VERSION ""

NS_ :

BS_:

BU_: PFAF_HS LVMPC_HS DCDC_HS AMP_HS VICM2_HS FICM_HS ARS_HS MCP_B_HS MCP_A_HS ICCM_OBD_HS SAS_HS ACCM_HS VLBS_HS EBCM_OBD_HS EDI_HS HPCC_HS VITM_OBD_HS PTAM_HS OBCM_HS VICM_HS HCP_HS FDCM_HS APPS_HS ICCM_HS EOCM_F_HS GPCM_HS FSCM_ITBC_HS SCM_HS ITBC_HS VCM_HS HMIM_HS FCP_HS VES_HS Dummy_HS MCP_C_HS RWS_HS ONSTAR_HS EPS_HS TestTool_HS MCP_HS BCP_HS ALC_HS AHL_AFL_HS SADS_HS EPB_HS FSCM_HS AFS_HS FCM_HS TCCM_HS RDCM_HS PTO_HS PCM_HS EBCM_HS ACC_HS BCM_HS TCM_HS ECM_HS

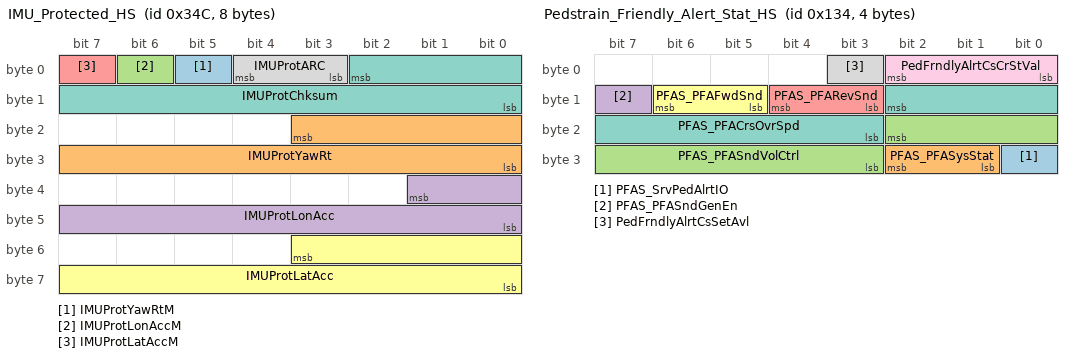
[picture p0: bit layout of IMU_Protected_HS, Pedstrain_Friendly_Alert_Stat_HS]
BO_ 844 IMU_Protected_HS: 8 EBCM_HS
  SG_ IMUProtYawRtM: 5|1@0+ (1,0) [0|1] "" FCM_HS
  SG_ IMUProtYawRt: 19|12@0- (0.0625,0) [-128|127.93751] "deg/sec" FCM_HS
  SG_ IMUProtLonAccM: 6|1@0+ (1,0) [0|1] "" FCM_HS
  SG_ IMUProtLonAcc: 33|10@0- (0.030000001,0) [-15.360001|15.33] "m/s^2" FCM_HS
  SG_ IMUProtLatAccM: 7|1@0+ (1,0) [0|1] "" FCM_HS
  SG_ IMUProtLatAcc: 51|12@0- (0.015625,0) [-32|31.984375] "m/s^2" FCM_HS
  SG_ IMUProtChksum: 2|11@0+ (1,0) [0|2047] "" FCM_HS
  SG_ IMUProtARC: 4|2@0+ (1,0) [0|3] "" FCM_HS

BO_ 308 Pedstrain_Friendly_Alert_Stat_HS: 4 PFAF_HS
  SG_ PFAS_SrvPedAlrtIO: 24|1@0+ (1,0) [0|1] "" BCM_HS
  SG_ PFAS_PFASysStat: 26|2@0+ (1,0) [0|3] "" BCM_HS
  SG_ PFAS_PFASndVolCtrl: 18|8@0+ (0.39215702,0) [0|100.00004] "%" BCM_HS
  SG_ PFAS_PFASndGenEn: 15|1@0+ (1,0) [0|1] "" BCM_HS
  SG_ PFAS_PFARevSnd: 12|2@0+ (1,0) [0|3] "" BCM_HS
  SG_ PFAS_PFAFwdSnd: 14|2@0+ (1,0) [0|3] "" BCM_HS
  SG_ PFAS_PFACrsOvrSpd: 10|8@0+ (1,0) [0|255] "km/h" BCM_HS
  SG_ PedFrndlyAlrtCsSetAvl: 3|1@0+ (1,0) [0|1] "" BCM_HS
  SG_ PedFrndlyAlrtCsCrStVal: 2|3@0+ (1,0) [0|7] "" BCM_HS

BO_ 806 DC_Converter_Stabilization_HS: 1 DCDC_HS
  SG_ DCCnvStblznErrIO: 0|1@0+ (1,0) [0|1] "" BCM_HS

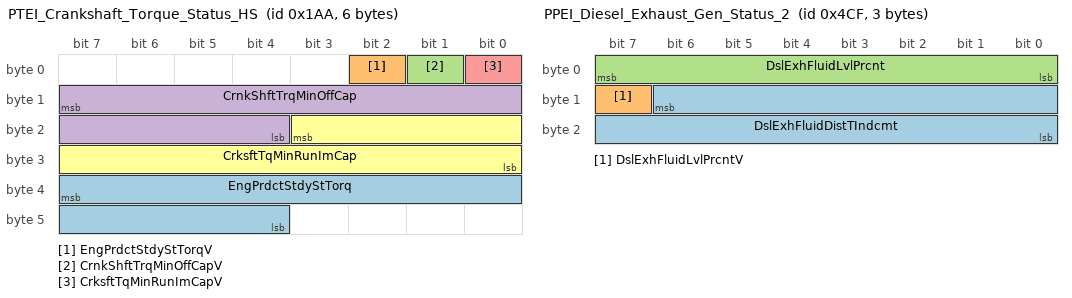
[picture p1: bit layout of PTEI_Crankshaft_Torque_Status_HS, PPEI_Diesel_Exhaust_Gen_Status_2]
BO_ 426 PTEI_Crankshaft_Torque_Status_HS: 6 ECM_HS
  SG_ EngPrdctStdyStTorq: 39|12@0+ (0.5,-848) [-848|1199.5] "Nm" TCM_HS
  SG_ EngPrdctStdyStTorqV: 2|1@0+ (1,0) [0|1] "" TCM_HS
  SG_ CrnkShftTrqMinOffCapV: 1|1@0+ (1,0) [0|1] "" TCM_HS
  SG_ CrnkShftTrqMinOffCap: 15|12@0+ (0.5,-848) [-848|1199.5] "Nm" TCM_HS
  SG_ CrksftTqMinRunImCapV: 0|1@0+ (1,0) [0|1] "" TCM_HS
  SG_ CrksftTqMinRunImCap: 19|12@0+ (0.5,-848) [-848|1199.5] "Nm" TCM_HS

BO_ 1231 PPEI_Diesel_Exhaust_Gen_Status_2: 3 ECM_HS
  SG_ DslExhFluidDistTIndcmt: 14|15@0+ (2,0) [0|65534] "km" BCM_HS
  SG_ DslExhFluidLvlPrcntV: 15|1@0+ (1,0) [0|1] "" BCM_HS
  SG_ DslExhFluidLvlPrcnt: 7|8@0+ (0.39215702,0) [0|100.00004] "%" BCM_HS

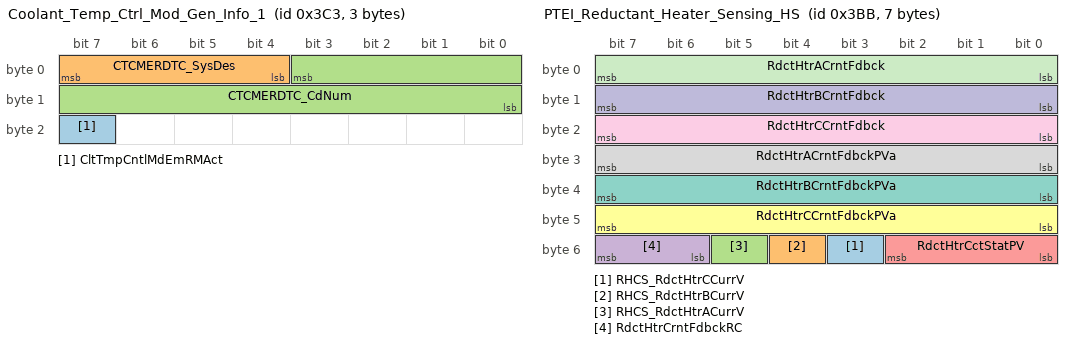
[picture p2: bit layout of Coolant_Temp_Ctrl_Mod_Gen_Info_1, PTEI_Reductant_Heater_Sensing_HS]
BO_ 963 Coolant_Temp_Ctrl_Mod_Gen_Info_1: 3 VICM2_HS
  SG_ CltTmpCntlMdEmRMAct: 23|1@0+ (1,0) [0|1] "" ECM_HS
  SG_ CTCMERDTC_SysDes: 7|4@0+ (1,0) [0|15] "" ECM_HS
  SG_ CTCMERDTC_CdNum: 3|12@0+ (1,0) [0|4095] "" ECM_HS

BO_ 955 PTEI_Reductant_Heater_Sensing_HS: 7 GPCM_HS
  SG_ RHCS_RdctHtrCCurrV: 51|1@0+ (1,0) [0|1] "" PCM_HS ECM_HS
  SG_ RHCS_RdctHtrBCurrV: 52|1@0+ (1,0) [0|1] "" PCM_HS ECM_HS
  SG_ RHCS_RdctHtrACurrV: 53|1@0+ (1,0) [0|1] "" PCM_HS ECM_HS
  SG_ RdctHtrCrntFdbckRC: 55|2@0+ (1,0) [0|3] "" PCM_HS ECM_HS
  SG_ RdctHtrCctStatPV: 50|3@0+ (1,0) [0|7] "" PCM_HS ECM_HS
  SG_ RdctHtrCCrntFdbckPVa: 47|8@0+ (1,0) [0|255] "" PCM_HS ECM_HS
  SG_ RdctHtrBCrntFdbckPVa: 39|8@0+ (1,0) [0|255] "" PCM_HS ECM_HS
  SG_ RdctHtrACrntFdbckPVa: 31|8@0+ (1,0) [0|255] "" PCM_HS ECM_HS
  SG_ RdctHtrCCrntFdbck: 23|8@0+ (0.11764701,0) [0|29.999987] "A" PCM_HS ECM_HS
  SG_ RdctHtrBCrntFdbck: 15|8@0+ (0.11764701,0) [0|29.999987] "A" PCM_HS ECM_HS
  SG_ RdctHtrACrntFdbck: 7|8@0+ (0.11764701,0) [0|29.999987] "A" PCM_HS ECM_HS

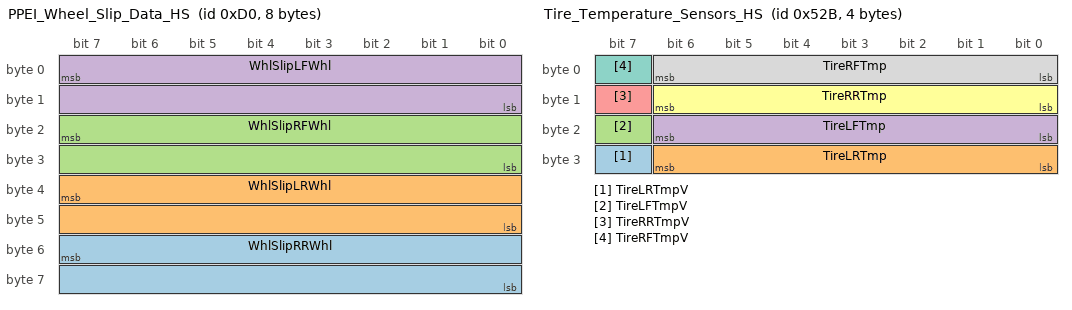
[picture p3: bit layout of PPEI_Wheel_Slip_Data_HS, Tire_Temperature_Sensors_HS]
BO_ 208 PPEI_Wheel_Slip_Data_HS: 8 EBCM_HS
  SG_ WhlSlipRRWhl: 55|16@0+ (0.39062503,-12800) [-12800|12799.608] "%" TCM_HS
  SG_ WhlSlipLRWhl: 39|16@0+ (0.39062503,-12800) [-12800|12799.608] "%" TCM_HS
  SG_ WhlSlipRFWhl: 23|16@0+ (0.39062503,-12800) [-12800|12799.608] "%" TCM_HS
  SG_ WhlSlipLFWhl: 7|16@0+ (0.39062503,-12800) [-12800|12799.608] "%" TCM_HS

BO_ 2034 CCP_Data_Transmission_Object_HS: 8 PTO_HS
  SG_ DgnInf: 7|64@0+ (1,0) [0|1.8446742e+19] "" TestTool_HS

BO_ 2032 CCP_Command_Receive_Object_HS: 8 TestTool_HS
  SG_ DgnInf: 7|64@0+ (1,0) [0|1.8446742e+19] "" PTO_HS

BO_ 563 Performance_Mode_Cust_Setings_HS: 5 EBCM_HS
  SG_ SPMCA_SusPrfMd6Avl: 32|1@0+ (1,0) [0|1] "" BCM_HS
  SG_ SPMCA_SusPrfMd5Avl: 33|1@0+ (1,0) [0|1] "" BCM_HS
  SG_ SPMCA_SusPrfMd4Avl: 34|1@0+ (1,0) [0|1] "" BCM_HS
  SG_ SPMCA_SusPrfMd3Avl: 35|1@0+ (1,0) [0|1] "" BCM_HS
  SG_ SPMCA_SusPrfMd2Avl: 36|1@0+ (1,0) [0|1] "" BCM_HS
  SG_ SPMCA_SusPrfMd1Avl: 37|1@0+ (1,0) [0|1] "" BCM_HS
  SG_ SPMCA_StrPrfMd6Avl: 24|1@0+ (1,0) [0|1] "" BCM_HS
  SG_ SPMCA_StrPrfMd5Avl: 25|1@0+ (1,0) [0|1] "" BCM_HS
  SG_ SPMCA_StrPrfMd4Avl: 26|1@0+ (1,0) [0|1] "" BCM_HS
  SG_ SPMCA_StrPrfMd3Avl: 27|1@0+ (1,0) [0|1] "" BCM_HS
  SG_ SPMCA_StrPrfMd2Avl: 28|1@0+ (1,0) [0|1] "" BCM_HS
  SG_ SPMCA_StrPrfMd1Avl: 29|1@0+ (1,0) [0|1] "" BCM_HS
  SG_ SPMCA_SndPrfMd6Avl: 16|1@0+ (1,0) [0|1] "" BCM_HS
  SG_ SPMCA_SndPrfMd5Avl: 17|1@0+ (1,0) [0|1] "" BCM_HS
  SG_ SPMCA_SndPrfMd4Avl: 18|1@0+ (1,0) [0|1] "" BCM_HS
  SG_ SPMCA_SndPrfMd3Avl: 19|1@0+ (1,0) [0|1] "" BCM_HS
  SG_ SPMCA_SndPrfMd2Avl: 20|1@0+ (1,0) [0|1] "" BCM_HS
  SG_ SPMCA_SndPrfMd1Avl: 21|1@0+ (1,0) [0|1] "" BCM_HS
  SG_ DPMCA_DispPrfMd6Avl: 8|1@0+ (1,0) [0|1] "" BCM_HS
  SG_ DPMCA_DispPrfMd5Avl: 9|1@0+ (1,0) [0|1] "" BCM_HS
  SG_ DPMCA_DispPrfMd4Avl: 10|1@0+ (1,0) [0|1] "" BCM_HS
  SG_ DPMCA_DispPrfMd3Avl: 11|1@0+ (1,0) [0|1] "" BCM_HS
  SG_ DPMCA_DispPrfMd2Avl: 12|1@0+ (1,0) [0|1] "" BCM_HS
  SG_ DPMCA_DispPrfMd1Avl: 13|1@0+ (1,0) [0|1] "" BCM_HS
  SG_ DPMCA_DrvlPrfMd6Avl: 0|1@0+ (1,0) [0|1] "" BCM_HS
  SG_ DPMCA_DrvlPrfMd5Avl: 1|1@0+ (1,0) [0|1] "" BCM_HS
  SG_ DPMCA_DrvlPrfMd4Avl: 2|1@0+ (1,0) [0|1] "" BCM_HS
  SG_ DPMCA_DrvlPrfMd3Avl: 3|1@0+ (1,0) [0|1] "" BCM_HS
  SG_ DPMCA_DrvlPrfMd2Avl: 4|1@0+ (1,0) [0|1] "" BCM_HS
  SG_ DPMCA_DrvlPrfMd1Avl: 5|1@0+ (1,0) [0|1] "" BCM_HS

BO_ 1323 Tire_Temperature_Sensors_HS: 4 BCM_HS
  SG_ TireLRTmpV: 31|1@0+ (1,0) [0|1] "" LVMPC_HS EDI_HS EBCM_OBD_HS EBCM_HS ICCM_OBD_HS ICCM_HS RDCM_HS
  SG_ TireLRTmp: 30|7@0+ (1,-20) [-20|107] "deg C" LVMPC_HS EDI_HS EBCM_OBD_HS EBCM_HS ICCM_OBD_HS ICCM_HS RDCM_HS
  SG_ TireLFTmpV: 23|1@0+ (1,0) [0|1] "" LVMPC_HS EDI_HS EBCM_OBD_HS EBCM_HS ICCM_OBD_HS ICCM_HS RDCM_HS
  SG_ TireLFTmp: 22|7@0+ (1,-20) [-20|107] "deg C" LVMPC_HS EDI_HS EBCM_OBD_HS EBCM_HS ICCM_OBD_HS ICCM_HS RDCM_HS
  SG_ TireRRTmpV: 15|1@0+ (1,0) [0|1] "" LVMPC_HS EDI_HS EBCM_OBD_HS EBCM_HS ICCM_OBD_HS ICCM_HS RDCM_HS
  SG_ TireRRTmp: 14|7@0+ (1,-20) [-20|107] "deg C" LVMPC_HS EDI_HS EBCM_OBD_HS EBCM_HS ICCM_OBD_HS ICCM_HS RDCM_HS
  SG_ TireRFTmpV: 7|1@0+ (1,0) [0|1] "" LVMPC_HS EDI_HS EBCM_OBD_HS EBCM_HS ICCM_OBD_HS ICCM_HS RDCM_HS
  SG_ TireRFTmp: 6|7@0+ (1,-20) [-20|107] "deg C" LVMPC_HS EDI_HS EBCM_OBD_HS EBCM_HS ICCM_OBD_HS ICCM_HS RDCM_HS

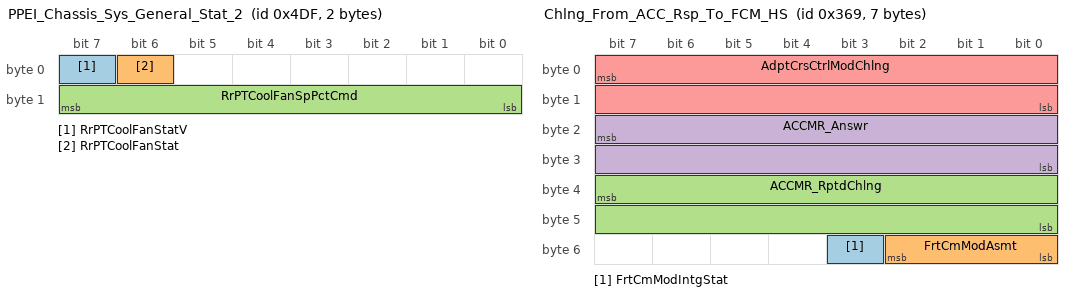
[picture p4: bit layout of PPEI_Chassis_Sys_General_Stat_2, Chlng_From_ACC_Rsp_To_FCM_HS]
BO_ 1247 PPEI_Chassis_Sys_General_Stat_2: 2 ICCM_HS
  SG_ RrPTCoolFanStatV: 7|1@0+ (1,0) [0|2] "" TCM_HS
  SG_ RrPTCoolFanStat: 6|1@0+ (1,0) [0|1] "" TCM_HS
  SG_ RrPTCoolFanSpPctCmd: 15|8@0+ (0.39215702,0) [0|100.00004] "%" TCM_HS

BO_ 873 Chlng_From_ACC_Rsp_To_FCM_HS: 7 ACC_HS
  SG_ FrtCmModIntgStat: 51|1@0+ (1,0) [0|1] "" FCM_HS
  SG_ FrtCmModAsmt: 50|3@0+ (1,0) [0|7] "" FCM_HS
  SG_ ACCMR_RptdChlng: 39|16@0+ (1,0) [0|65535] "" FCM_HS
  SG_ ACCMR_Answr: 23|16@0+ (1,0) [0|65535] "" FCM_HS
  SG_ AdptCrsCtrlModChlng: 7|16@0+ (1,0) [0|65535] "" FCM_HS

BO_ 306 Exhst_Heat_Recvry_Mngmnt_HS: 1 VICM2_HS
  SG_ ClntCrcFlwRtEst: 7|8@0+ (0.39215702,0) [0|100.00004] "%" BCM_HS

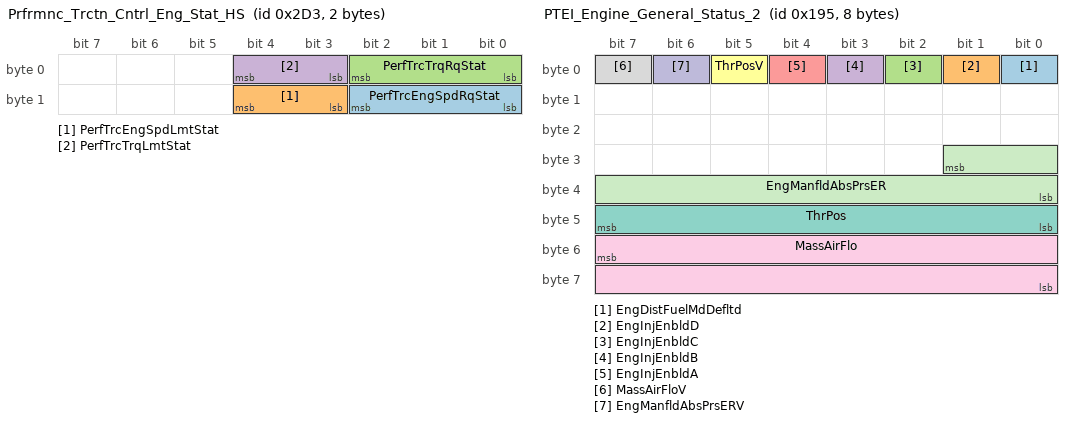
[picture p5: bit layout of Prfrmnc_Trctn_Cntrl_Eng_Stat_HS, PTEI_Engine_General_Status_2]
BO_ 723 Prfrmnc_Trctn_Cntrl_Eng_Stat_HS: 2 ECM_HS
  SG_ PerfTrcEngSpdRqStat: 10|3@0+ (1,0) [0|7] "" EBCM_OBD_HS EBCM_HS PTAM_HS
  SG_ PerfTrcEngSpdLmtStat: 12|2@0+ (1,0) [0|3] "" EBCM_OBD_HS EBCM_HS PTAM_HS
  SG_ PerfTrcTrqRqStat: 2|3@0+ (1,0) [0|7] "" EBCM_OBD_HS EBCM_HS PTAM_HS
  SG_ PerfTrcTrqLmtStat: 4|2@0+ (1,0) [0|3] "" EBCM_OBD_HS EBCM_HS PTAM_HS

BO_ 405 PTEI_Engine_General_Status_2: 8 ECM_HS
  SG_ EngDistFuelMdDefltd: 0|1@0+ (1,0) [0|1] "" FICM_HS
  SG_ EngInjEnbldD: 1|1@0+ (1,0) [0|1] "" FICM_HS
  SG_ EngInjEnbldC: 2|1@0+ (1,0) [0|1] "" FICM_HS
  SG_ EngInjEnbldB: 3|1@0+ (1,0) [0|1] "" FICM_HS
  SG_ EngInjEnbldA: 4|1@0+ (1,0) [0|1] "" FICM_HS
  SG_ ThrPosV: 5|1@0+ (1,0) [0|1] "" FICM_HS
  SG_ ThrPos: 47|8@0+ (0.39215702,0) [0|100.00004] "%" FICM_HS
  SG_ MassAirFloV: 7|1@0+ (1,0) [0|1] "" VCM_HS FICM_HS
  SG_ MassAirFlo: 55|16@0+ (0.010000001,0) [0|655.34998] "grams/s" VCM_HS FICM_HS
  SG_ EngManfldAbsPrsERV: 6|1@0+ (1,0) [0|1] "" FICM_HS
  SG_ EngManfldAbsPrsER: 25|10@0+ (0.5,0) [0|511.5] "kPa" FICM_HS

BO_ 419 PTEI_Engine_Common_Use_1: 1 ECM_HS
  SG_ EngRunng: 7|1@0+ (1,0) [0|1] "" BCM_HS DCDC_HS TCCM_HS EBCM_OBD_HS EBCM_HS OBCM_HS MCP_C_HS MCP_B_HS MCP_A_HS FICM_HS TCM_HS HCP_HS BCP_HS

BO_ 289 ADASIS_RawData_Multiplexed_HS: 8 HMIM_HS
  SG_ ARDM_RawData: 4|61@0+ (1,0) [0|2.305843e+18] "" Dummy_HS
  SG_ ARDM_MsgType: 7|3@0+ (1,0) [0|7] "" Dummy_HS

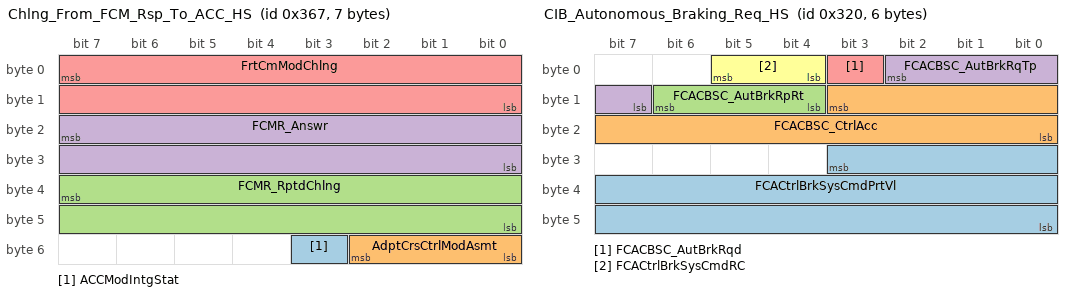
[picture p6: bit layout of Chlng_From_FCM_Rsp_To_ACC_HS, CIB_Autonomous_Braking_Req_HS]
BO_ 871 Chlng_From_FCM_Rsp_To_ACC_HS: 7 FCM_HS
  SG_ ACCModIntgStat: 51|1@0+ (1,0) [0|1] "" ACC_HS
  SG_ AdptCrsCtrlModAsmt: 50|3@0+ (1,0) [0|7] "" ACC_HS
  SG_ FCMR_RptdChlng: 39|16@0+ (1,0) [0|65535] "" ACC_HS
  SG_ FCMR_Answr: 23|16@0+ (1,0) [0|65535] "" ACC_HS
  SG_ FrtCmModChlng: 7|16@0+ (1,0) [0|65535] "" ACC_HS

BO_ 800 CIB_Autonomous_Braking_Req_HS: 6 FCM_HS
  SG_ FCACtrlBrkSysCmdPrtVl: 27|20@0+ (1,0) [0|1048575] "" EBCM_OBD_HS EBCM_HS
  SG_ FCACBSC_CtrlAcc: 11|12@0- (0.010000001,0) [-20.48|20.469999] "m/s^2" EBCM_OBD_HS EBCM_HS
  SG_ FCACBSC_AutBrkRpRt: 14|3@0+ (1,0) [0|7] "" EBCM_OBD_HS EBCM_HS
  SG_ FCACBSC_AutBrkRqTp: 2|4@0+ (1,0) [0|15] "" EBCM_OBD_HS EBCM_HS
  SG_ FCACBSC_AutBrkRqd: 3|1@0+ (1,0) [0|1] "" EBCM_OBD_HS EBCM_HS
  SG_ FCACtrlBrkSysCmdRC: 5|2@0+ (1,0) [0|3] "" EBCM_OBD_HS EBCM_HS

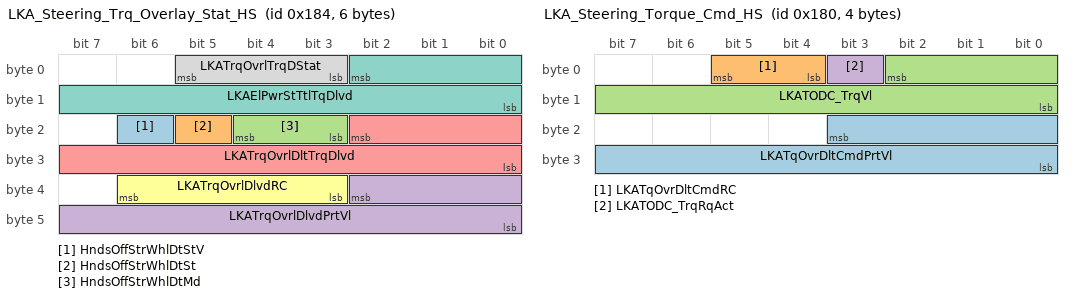
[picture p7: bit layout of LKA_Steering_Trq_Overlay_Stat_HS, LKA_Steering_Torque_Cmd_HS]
BO_ 388 LKA_Steering_Trq_Overlay_Stat_HS: 6 EPS_HS
  SG_ HndsOffStrWhlDtStV: 22|1@0+ (1,0) [0|1] "" FCM_HS
  SG_ HndsOffStrWhlDtSt: 21|1@0+ (1,0) [0|1] "" FCM_HS
  SG_ HndsOffStrWhlDtMd: 20|2@0+ (1,0) [0|3] "" FCM_HS
  SG_ LKATrqOvrlDlvdPrtVl: 34|11@0+ (1,0) [0|2047] "" FCM_HS
  SG_ LKATrqOvrlDltTrqDlvd: 18|11@0- (0.010000001,0) [-10.24|10.23] "Nm" FCM_HS
  SG_ LKATrqOvrlDlvdRC: 38|4@0+ (1,0) [0|15] "" FCM_HS
  SG_ LKAElPwrStTtlTqDlvd: 2|11@0- (0.010000001,0) [-10.24|10.23] "Nm" FCM_HS
  SG_ LKATrqOvrlTrqDStat: 5|3@0+ (1,0) [0|7] "" FCM_HS

BO_ 384 LKA_Steering_Torque_Cmd_HS: 4 FCM_HS
  SG_ LKATqOvrDltCmdPrtVl: 19|12@0+ (1,0) [0|4095] "" EPS_HS
  SG_ LKATqOvrDltCmdRC: 5|2@0+ (1,0) [0|3] "" EPS_HS
  SG_ LKATODC_TrqVl: 2|11@0- (0.010000001,0) [-10.24|10.23] "Nm" EPS_HS
  SG_ LKATODC_TrqRqAct: 3|1@0+ (1,0) [0|1] "" EPS_HS

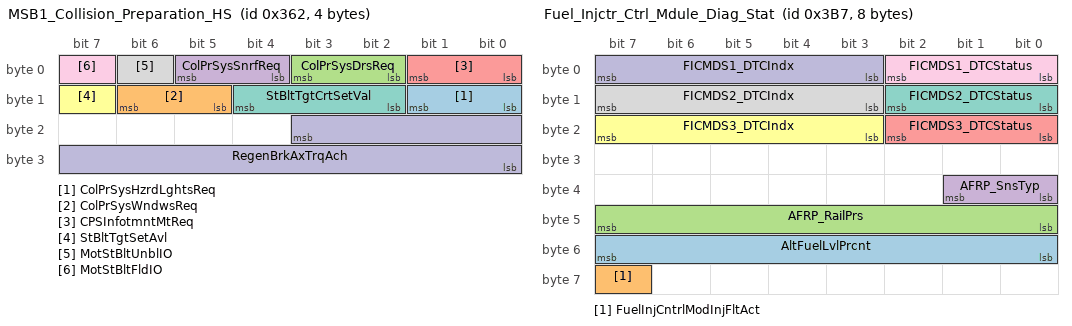
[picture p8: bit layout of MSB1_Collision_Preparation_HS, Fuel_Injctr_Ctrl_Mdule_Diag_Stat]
BO_ 866 MSB1_Collision_Preparation_HS: 4 EBCM_HS
  SG_ ColPrSysHzrdLghtsReq: 9|2@0+ (1,0) [0|3] "" BCM_HS
  SG_ ColPrSysWndwsReq: 14|2@0+ (1,0) [0|3] "" BCM_HS
  SG_ ColPrSysDrsReq: 3|2@0+ (1,0) [0|3] "" BCM_HS
  SG_ ColPrSysSnrfReq: 5|2@0+ (1,0) [0|3] "" BCM_HS
  SG_ CPSInfotmntMtReq: 1|2@0+ (1,0) [0|3] "" BCM_HS
  SG_ StBltTgtSetAvl: 15|1@0+ (1,0) [0|1] "" BCM_HS
  SG_ StBltTgtCrtSetVal: 12|3@0+ (1,0) [0|7] "" BCM_HS
  SG_ MotStBltUnblIO: 6|1@0+ (1,0) [0|1] "" BCM_HS
  SG_ MotStBltFldIO: 7|1@0+ (1,0) [0|1] "" BCM_HS
  SG_ RegenBrkAxTrqAch: 19|12@0+ (2,0) [0|8190] "Nm" VICM_HS

BO_ 951 Fuel_Injctr_Ctrl_Mdule_Diag_Stat: 8 FICM_HS
  SG_ AltFuelLvlPrcnt: 55|8@0+ (0.39215702,0) [0|100.00004] "%" ECM_HS
  SG_ FuelInjCntrlModInjFltAct: 63|1@0+ (1,0) [0|1] "" ECM_HS
  SG_ AFRP_RailPrs: 47|8@0+ (3,0) [0|765] "kPa" ECM_HS
  SG_ AFRP_SnsTyp: 33|2@0+ (1,0) [0|3] "" ECM_HS
  SG_ FICMDS3_DTCStatus: 18|3@0+ (1,0) [0|7] "" ECM_HS
  SG_ FICMDS3_DTCIndx: 23|5@0+ (1,0) [0|31] "" ECM_HS
  SG_ FICMDS2_DTCStatus: 10|3@0+ (1,0) [0|7] "" ECM_HS
  SG_ FICMDS2_DTCIndx: 15|5@0+ (1,0) [0|31] "" ECM_HS
  SG_ FICMDS1_DTCStatus: 2|3@0+ (1,0) [0|7] "" ECM_HS
  SG_ FICMDS1_DTCIndx: 7|5@0+ (1,0) [0|31] "" ECM_HS

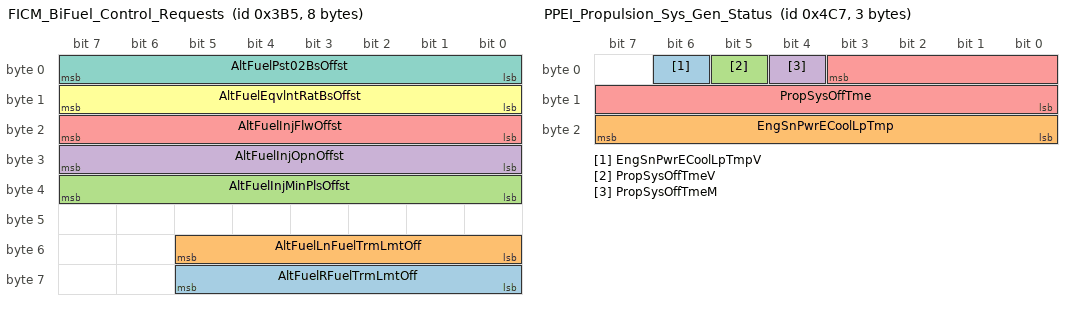
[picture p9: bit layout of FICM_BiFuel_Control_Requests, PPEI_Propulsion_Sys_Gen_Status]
BO_ 949 FICM_BiFuel_Control_Requests: 8 FICM_HS
  SG_ AltFuelRFuelTrmLmtOff: 61|6@0- (0.010000001,0) [-0.32000002|0.31] "" ECM_HS
  SG_ AltFuelLnFuelTrmLmtOff: 53|6@0- (0.010000001,0) [-0.32000002|0.31] "" ECM_HS
  SG_ AltFuelInjMinPlsOffst: 39|8@0- (0.031372499,0) [-4.0156803|3.9843073] "grams/s" ECM_HS
  SG_ AltFuelInjOpnOffst: 31|8@0- (0.031372499,0) [-4.0156803|3.9843073] "grams/s" ECM_HS
  SG_ AltFuelInjFlwOffst: 23|8@0- (0.031372499,0) [-4.0156803|3.9843073] "grams/s" ECM_HS
  SG_ AltFuelEqvlntRatBsOffst: 15|8@0- (0.00039215703,0) [-0.050196104|0.049803939] "" ECM_HS
  SG_ AltFuelPst02BsOffst: 7|8@0- (4,0) [-512|508] "mVolts" ECM_HS

BO_ 1223 PPEI_Propulsion_Sys_Gen_Status: 3 ECM_HS
  SG_ EngSnPwrECoolLpTmpV: 6|1@0+ (1,0) [0|1] "" VICM_HS
  SG_ EngSnPwrECoolLpTmp: 23|8@0+ (1,-40) [-40|215] "deg C" VICM_HS
  SG_ PropSysOffTmeV: 5|1@0+ (1,0) [0|1] "" VICM2_HS EBCM_OBD_HS EBCM_HS MCP_C_HS TCM_HS HCP_HS BCP_HS MCP_B_HS MCP_A_HS VICM_HS
  SG_ PropSysOffTmeM: 4|1@0+ (1,0) [0|1] "" VICM2_HS EBCM_OBD_HS EBCM_HS MCP_C_HS TCM_HS HCP_HS BCP_HS MCP_B_HS MCP_A_HS VICM_HS
  SG_ PropSysOffTme: 3|12@0+ (0.5,0) [0|2047.5] "min" VICM2_HS EBCM_OBD_HS EBCM_HS MCP_C_HS TCM_HS HCP_HS BCP_HS MCP_B_HS MCP_A_HS VICM_HS

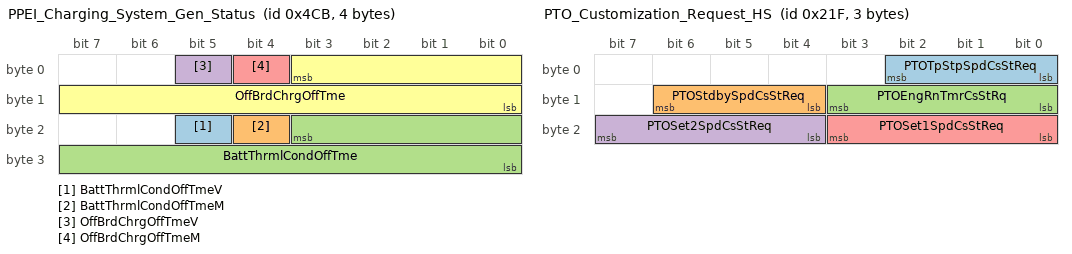
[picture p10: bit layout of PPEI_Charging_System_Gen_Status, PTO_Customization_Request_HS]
BO_ 1227 PPEI_Charging_System_Gen_Status: 4 VICM_HS
  SG_ BattThrmlCondOffTmeV: 21|1@0+ (1,0) [0|1] "" MCP_C_HS TCM_HS HCP_HS MCP_B_HS MCP_A_HS PCM_HS ECM_HS
  SG_ BattThrmlCondOffTmeM: 20|1@0+ (1,0) [0|1] "" MCP_C_HS TCM_HS HCP_HS MCP_B_HS MCP_A_HS PCM_HS ECM_HS
  SG_ BattThrmlCondOffTme: 19|12@0+ (0.5,0) [0|2047.5] "min" MCP_C_HS TCM_HS HCP_HS MCP_B_HS MCP_A_HS PCM_HS ECM_HS
  SG_ OffBrdChrgOffTmeV: 5|1@0+ (1,0) [0|1] "" MCP_C_HS TCM_HS HCP_HS MCP_B_HS MCP_A_HS PCM_HS ECM_HS
  SG_ OffBrdChrgOffTmeM: 4|1@0+ (1,0) [0|1] "" MCP_C_HS TCM_HS HCP_HS MCP_B_HS MCP_A_HS PCM_HS ECM_HS
  SG_ OffBrdChrgOffTme: 3|12@0+ (0.5,0) [0|2047.5] "min" MCP_C_HS TCM_HS HCP_HS MCP_B_HS MCP_A_HS PCM_HS ECM_HS

BO_ 543 PTO_Customization_Request_HS: 3 BCM_HS
  SG_ PTOTpStpSpdCsStReq: 2|3@0+ (1,0) [0|7] "" PTO_HS
  SG_ PTOStdbySpdCsStReq: 14|3@0+ (1,0) [0|7] "" PTO_HS
  SG_ PTOEngRnTmrCsStRq: 11|4@0+ (1,0) [0|15] "" PTO_HS
  SG_ PTOSet2SpdCsStReq: 23|4@0+ (1,0) [0|15] "" PTO_HS
  SG_ PTOSet1SpdCsStReq: 19|4@0+ (1,0) [0|15] "" PTO_HS

BO_ 544 PTO_Status_HS: 5 PTO_HS
  SG_ PTOAudExtAlertReq: 19|1@0+ (1,0) [0|1] "" BCM_HS
  SG_ PTOTransInGearIO: 13|1@0+ (1,0) [0|1] "" BCM_HS
  SG_ PTOTpStpSpdCsStAvl: 10|1@0+ (1,0) [0|1] "" BCM_HS
  SG_ PTOTpStSpdCsCrStVal: 26|3@0+ (1,0) [0|7] "" BCM_HS
  SG_ PTOStdbySpdCsStAvl: 12|1@0+ (1,0) [0|1] "" BCM_HS
  SG_ PTOStdbSpdCsCrStVal: 18|3@0+ (1,0) [0|7] "" BCM_HS
  SG_ PTOSetPrkBrkIO: 14|1@0+ (1,0) [0|1] "" BCM_HS
  SG_ PTOSet2SpdCsStAvl: 9|1@0+ (1,0) [0|1] "" BCM_HS
  SG_ PTOSet2SpdCsCrStVal: 39|4@0+ (1,0) [0|15] "" BCM_HS
  SG_ PTOSet1SpdCsStAvl: 8|1@0+ (1,0) [0|1] "" BCM_HS
  SG_ PTOSet1SpdCsCrStVal: 35|4@0+ (1,0) [0|15] "" BCM_HS
  SG_ PTORelCltPedIO: 15|1@0+ (1,0) [0|1] "" BCM_HS
  SG_ PTORelBrkPedIO: 0|1@0+ (1,0) [0|1] "" BCM_HS
  SG_ PTORelAccPedIO: 1|1@0+ (1,0) [0|1] "" BCM_HS
  SG_ PTORedEngSpdIO: 2|1@0+ (1,0) [0|1] "" BCM_HS
  SG_ PTOPrsRelCltPedIO: 3|1@0+ (1,0) [0|1] "" BCM_HS
  SG_ PTOPrsRelBrkPedIO: 4|1@0+ (1,0) [0|1] "" BCM_HS
  SG_ PTOEngRnTmrCsStAvl: 11|1@0+ (1,0) [0|1] "" BCM_HS
  SG_ PTOEnRnTmCsCrStVal: 30|4@0+ (1,0) [0|15] "" BCM_HS
  SG_ PTOEngmntStatInd: 6|2@0+ (1,0) [0|3] "" BCM_HS
  SG_ PTODisengCrsCntlIO: 7|1@0+ (1,0) [0|1] "" BCM_HS

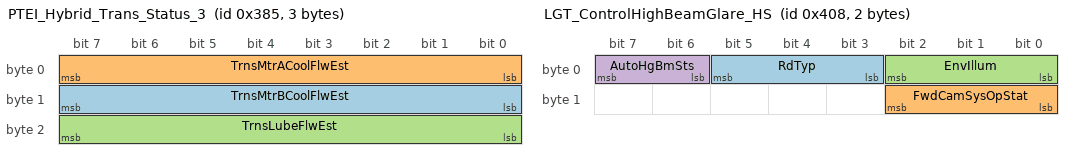
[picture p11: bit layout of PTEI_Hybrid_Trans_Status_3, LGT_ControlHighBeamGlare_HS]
BO_ 901 PTEI_Hybrid_Trans_Status_3: 3 TCM_HS
  SG_ TrnsMtrBCoolFlwEst: 15|8@0+ (0.050000004,0) [0|12.75] "l/min" HCP_HS
  SG_ TrnsMtrACoolFlwEst: 7|8@0+ (0.050000004,0) [0|12.75] "l/min" HCP_HS
  SG_ TrnsLubeFlwEst: 23|8@0+ (0.0625,0) [0|15.937499] "l/min" HCP_HS

BO_ 1032 LGT_ControlHighBeamGlare_HS: 2 FCM_HS
  SG_ RdTyp: 5|3@0+ (1,0) [0|7] "" AHL_AFL_HS
  SG_ FwdCamSysOpStat: 10|3@0+ (1,0) [0|7] "" AHL_AFL_HS
  SG_ EnvIllum: 2|3@0+ (1,0) [0|7] "" AHL_AFL_HS
  SG_ AutoHgBmSts: 7|2@0+ (1,0) [0|3] "" AHL_AFL_HS

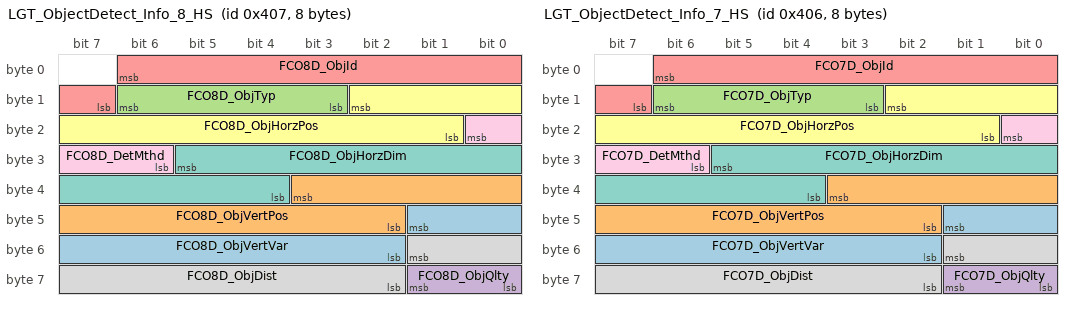
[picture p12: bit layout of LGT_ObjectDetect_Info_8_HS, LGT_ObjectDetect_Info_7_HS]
BO_ 1031 LGT_ObjectDetect_Info_8_HS: 8 FCM_HS
  SG_ FCO8D_ObjVertVar: 41|8@0- (0.050000004,0) [-6.4000001|6.3500004] "deg" AHL_AFL_HS
  SG_ FCO8D_ObjVertPos: 35|10@0- (0.050000004,0) [-25.6|25.549999] "deg" AHL_AFL_HS
  SG_ FCO8D_ObjTyp: 14|4@0+ (1,0) [0|15] "" AHL_AFL_HS
  SG_ FCO8D_ObjQlty: 57|2@0+ (1,0) [0|3] "" AHL_AFL_HS
  SG_ FCO8D_ObjId: 6|8@0+ (1,0) [0|255] "" AHL_AFL_HS
  SG_ FCO8D_ObjHorzPos: 10|10@0- (0.050000004,0) [-25.6|25.549999] "deg" AHL_AFL_HS
  SG_ FCO8D_ObjHorzDim: 29|10@0+ (0.010000001,0) [0|10.23] "deg" AHL_AFL_HS
  SG_ FCO8D_ObjDist: 49|8@0+ (2,0) [0|510] "m" AHL_AFL_HS
  SG_ FCO8D_DetMthd: 16|3@0+ (1,0) [0|7] "" AHL_AFL_HS

BO_ 1030 LGT_ObjectDetect_Info_7_HS: 8 FCM_HS
  SG_ FCO7D_ObjVertVar: 41|8@0- (0.050000004,0) [-6.4000001|6.3500004] "deg" AHL_AFL_HS
  SG_ FCO7D_ObjVertPos: 35|10@0- (0.050000004,0) [-25.6|25.549999] "deg" AHL_AFL_HS
  SG_ FCO7D_ObjTyp: 14|4@0+ (1,0) [0|15] "" AHL_AFL_HS
  SG_ FCO7D_ObjQlty: 57|2@0+ (1,0) [0|3] "" AHL_AFL_HS
  SG_ FCO7D_ObjId: 6|8@0+ (1,0) [0|255] "" AHL_AFL_HS
  SG_ FCO7D_ObjHorzPos: 10|10@0- (0.050000004,0) [-25.6|25.549999] "deg" AHL_AFL_HS
  SG_ FCO7D_ObjHorzDim: 29|10@0+ (0.010000001,0) [0|10.23] "deg" AHL_AFL_HS
  SG_ FCO7D_ObjDist: 49|8@0+ (2,0) [0|510] "m" AHL_AFL_HS
  SG_ FCO7D_DetMthd: 16|3@0+ (1,0) [0|7] "" AHL_AFL_HS

BO_ 479 PPEI_Propulsion_Gen_Stat_1_HS: 4 HCP_HS
  SG_ ASIRI_Indication16: 24|1@0+ (1,0) [0|1] "" BCM_HS
  SG_ ASIRI_Indication15: 25|1@0+ (1,0) [0|1] "" BCM_HS
  SG_ ASIRI_Indication14: 26|1@0+ (1,0) [0|1] "" BCM_HS
  SG_ ASIRI_Indication13: 27|1@0+ (1,0) [0|1] "" BCM_HS
  SG_ ASIRI_Indication12: 28|1@0+ (1,0) [0|1] "" BCM_HS
  SG_ ASIRI_Indication11: 29|1@0+ (1,0) [0|1] "" BCM_HS
  SG_ ASIRI_Indication10: 30|1@0+ (1,0) [0|1] "" BCM_HS
  SG_ ASIRI_Indication09: 31|1@0+ (1,0) [0|1] "" BCM_HS
  SG_ ASIRI_Indication08: 16|1@0+ (1,0) [0|1] "" BCM_HS
  SG_ ASIRI_Indication07: 17|1@0+ (1,0) [0|1] "" BCM_HS
  SG_ ASIRI_Indication06: 18|1@0+ (1,0) [0|1] "" BCM_HS
  SG_ ASIRI_Indication05: 19|1@0+ (1,0) [0|1] "" BCM_HS
  SG_ ASIRI_Indication04: 20|1@0+ (1,0) [0|1] "" BCM_HS
  SG_ ASIRI_Indication03: 21|1@0+ (1,0) [0|1] "" BCM_HS
  SG_ ASIRI_Indication02: 22|1@0+ (1,0) [0|1] "" BCM_HS
  SG_ ASIRI_Indication01: 23|1@0+ (1,0) [0|1] "" BCM_HS
  SG_ PTWrmgWtToShftIO: 5|1@0+ (1,0) [0|1] "" BCM_HS
  SG_ PrplsnSysAtv: 7|1@0+ (1,0) [0|1] "" EPB_HS TCM_HS ECM_HS TCCM_HS VICM_HS ICCM_OBD_HS ICCM_HS FSCM_HS ACCM_HS EBCM_OBD_HS EBCM_HS OBCM_HS VICM2_HS VITM_OBD_HS
  SG_ PTShftLvrLckRqd: 6|1@0+ (1,0) [0|1] "" BCM_HS

BO_ 211 PPEI_Hybrid_General_Status_3_HS: 2 HCP_HS
  SG_ ActAxleTrqV: 7|1@0+ (1,0) [0|1] "" SADS_HS ICCM_OBD_HS ICCM_HS TCM_HS PCM_HS ECM_HS EBCM_OBD_HS EBCM_HS BCP_HS EOCM_F_HS VICM_HS TCCM_HS ACC_HS
  SG_ ActAxleTrq: 6|15@0+ (2,-22534) [-22534|43000] "Nm" SADS_HS ICCM_OBD_HS ICCM_HS EBCM_OBD_HS EBCM_HS TCM_HS PCM_HS ECM_HS BCP_HS EOCM_F_HS TCCM_HS VICM_HS ACC_HS

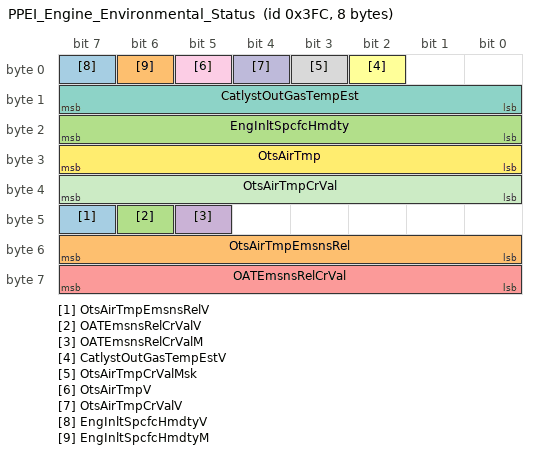
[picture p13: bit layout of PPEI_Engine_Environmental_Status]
BO_ 1020 PPEI_Engine_Environmental_Status: 8 ECM_HS
  SG_ OtsAirTmpEmsnsRelV: 47|1@0+ (1,0) [0|1] "" VICM_HS
  SG_ OtsAirTmpEmsnsRel: 55|8@0+ (0.5,-40) [-40|87.5] "deg C" VICM_HS
  SG_ OATEmsnsRelCrValV: 46|1@0+ (1,0) [0|1] "" VICM_HS
  SG_ OATEmsnsRelCrValM: 45|1@0+ (1,0) [0|1] "" VICM_HS
  SG_ OATEmsnsRelCrVal: 63|8@0+ (0.5,-40) [-40|87.5] "deg C" VICM_HS
  SG_ CatlystOutGasTempEstV: 2|1@0+ (1,0) [0|1] "" VICM_HS
  SG_ CatlystOutGasTempEst: 15|8@0+ (5,-40) [-40|1235] "deg C" VICM_HS
  SG_ OtsAirTmpCrValMsk: 3|1@0+ (1,0) [0|1] "" VICM_HS BCM_HS
  SG_ OtsAirTmpV: 5|1@0+ (1,0) [0|1] "" VICM_HS BCM_HS
  SG_ OtsAirTmpCrValV: 4|1@0+ (1,0) [0|1] "" VICM_HS BCM_HS
  SG_ OtsAirTmpCrVal: 39|8@0+ (0.5,-40) [-40|87.5] "deg C" VICM_HS BCM_HS
  SG_ OtsAirTmp: 31|8@0+ (0.5,-40) [-40|87.5] "deg C" VICM_HS BCM_HS
  SG_ EngInltSpcfcHmdtyV: 7|1@0+ (1,0) [0|1] "" VICM_HS BCM_HS EBCM_OBD_HS EBCM_HS
  SG_ EngInltSpcfcHmdtyM: 6|1@0+ (1,0) [0|1] "" VICM_HS BCM_HS EBCM_OBD_HS EBCM_HS
  SG_ EngInltSpcfcHmdty: 23|8@0+ (0.019607801,0) [0|4.999989] "% water" VICM_HS BCM_HS EBCM_OBD_HS EBCM_HS

VAL_TABLE_ vt_BooleanValues 0 "false" 1 "true";
VAL_TABLE_ TCTPIR_DrvNotfn 0 "No Indication" 1 "Indication 1" 2 "Indication 2" 3 "Indication 3" 4 "Indication 4" 5 "Indication 5" 6 "Indication 6" 7 "Indication 7" 8 "Indication 8" 9 "Indication 9" 10 "Indication 10" 11 "Indication 11" 12 "Indication 12" 13 "Indication 13" 14 "Indication 14" 15 "Indication 15";
VAL_TABLE_ PltfrmEngSpdCmmndSt 0 "No Request" 1 "Request Honored" 2 "Lost Arbitration" 3 "Request Denied";
VAL_TABLE_ TrStPTGrdBrkDsMdOvr 0 "No Override" 1 "To Not Grade Braking Disable" 2 "To Grade Braking Disable" 3 "Unused and Reserved";
VAL_TABLE_ SpdLmtrSttngTyp 0 "Manual" 1 "Auto";
VAL_TABLE_ HiPresFuelPmpCntMd 0 "Disable Mode" 1 "DFCO Mode" 2 "Normal Mode" 3 "Start Mode" 4 "Noise Control Disable Mode" 5 "Noise Control Max Mode" 6 "Zero Flow Mode";
VAL_TABLE_ ClmtCtrlHtrEngRunRq 0 "No Action" 1 "Engine Run Requested";
VAL_TABLE_ TrnsStWntrMdOvrd 0 "No Override" 1 "Override To Not Winter" 2 "Override To Winter";
VAL_TABLE_ TrnsStTwHaulMdOvrd 0 "No Override" 1 "Override To Not Tow Haul" 2 "Override To Tow Haul";
VAL_TABLE_ TrnsStSprtMdOvrd 0 "No Override" 1 "Override To Not Sport" 2 "Override To Sport";
VAL_TABLE_ TrnsStEconMdOvrd 0 "No Override" 1 "Override To Not Economy" 2 "Override To Economy";
VAL_TABLE_ StgSysPerfMdRq 0 "No Action" 1 "Performance Mode 1" 2 "Performance Mode 2" 3 "Performance Mode 3" 4 "Performance Mode 4" 5 "Performance Mode 5" 6 "Performance Mode 6" 7 "Performance Mode 7";
VAL_TABLE_ SndEnhcmtPerfMdRq 0 "No Action" 1 "Performance Mode 1" 2 "Performance Mode 2" 3 "Performance Mode 3" 4 "Performance Mode 4" 5 "Performance Mode 5" 6 "Performance Mode 6" 7 "Performance Mode 7";
VAL_TABLE_ RideCntrlPerfMdRq 0 "No Action" 1 "Performance Mode 1" 2 "Performance Mode 2" 3 "Performance Mode 3" 4 "Performance Mode 4" 5 "Performance Mode 5" 6 "Performance Mode 6" 7 "Performance Mode 7";
VAL_TABLE_ ExhstPerfMdRq 0 "No Action" 1 "Performance Mode 1" 2 "Performance Mode 2" 3 "Performance Mode 3" 4 "Performance Mode 4" 5 "Performance Mode 5" 6 "Performance Mode 6" 7 "Performance Mode 7";
VAL_TABLE_ DsplyPerfMdRq 0 "No Action" 1 "Performance Mode 1" 2 "Performance Mode 2" 3 "Performance Mode 3" 4 "Performance Mode 4" 5 "Performance Mode 5" 6 "Performance Mode 6" 7 "Performance Mode 7";
VAL_TABLE_ DiffPerfMdRq 0 "No Action" 1 "Performance Mode 1" 2 "Performance Mode 2" 3 "Performance Mode 3" 4 "Performance Mode 4" 5 "Performance Mode 5" 6 "Performance Mode 6" 7 "Performance Mode 7";
VAL_TABLE_ AWDPerfMdRq 0 "No Action" 1 "Performance Mode 1" 2 "Performance Mode 2" 3 "Performance Mode 3" 4 "Performance Mode 4" 5 "Performance Mode 5" 6 "Performance Mode 6" 7 "Performance Mode 7";
VAL_TABLE_ RdHVltBatPckVltM 0 "Don't Use Data" 1 "Use Data";
VAL_TABLE_ RdHVltBatPckCrntM 0 "Don't Use Data" 1 "Use Data";
VAL_TABLE_ RdHVltBatMinClVltM 0 "Don't Use Data" 1 "Use Data";
VAL_TABLE_ RdHVltBatMaxClVltM 0 "Don't Use Data" 1 "Use Data";
VAL_TABLE_ AFRP_SnsTyp 0 "Not Supported" 1 "Pressure Relative Manifold Vacuum" 2 "Absolute Pressure" 3 "Gauge Pressure";
VAL_TABLE_ FICMDS3_DTCStatus 0 "Not Supported" 1 "Critically Disabled" 2 "No Status to Report" 3 "Diagnostic Passed" 4 "Diagnostic Failed";
VAL_TABLE_ FICMDS2_DTCStatus 0 "Not Supported" 1 "Critically Disabled" 2 "No Status to Report" 3 "Diagnostic Passed" 4 "Diagnostic Failed";
VAL_TABLE_ FICMDS1_DTCStatus 0 "Not Supported" 1 "Critically Disabled" 2 "No Status to Report" 3 "Diagnostic Passed" 4 "Diagnostic Failed";
VAL_TABLE_ PropSysOffTmeM 0 "Don't Use Data" 1 "Use Data";
VAL_TABLE_ OffBrdChrgOffTmeM 0 "Don't Use Data" 1 "Use Data";
VAL_TABLE_ BattThrmlCondOffTmeM 0 "Don't Use Data" 1 "Use Data";
VAL_TABLE_ CrsSecSwStat 0 "Indeterminate" 1 "No Activation" 2 "Unused and Reserved 1" 3 "Gap Down" 4 "Gap Up" 5 "Speed Increase High" 6 "Speed Decrease High" 7 "Open/Short to Ground" 8 "Short to Power" 9 "Between Ranges" 10 "Unused and Reserved 2" 11 "Unused and Reserved 3" 12 "Unused and Reserved 4" 13 "Unused and Reserved 5" 14 "Unused and Reserved 6" 15 "Unused and Reserved 7";
VAL_TABLE_ EDADS_RcmndtFwdGr 0 "None" 1 "First Gear" 2 "Second Gear" 3 "Third Gear" 4 "Fourth Gear" 5 "Fifth Gear" 6 "Sixth Gear" 7 "Seventh Gear" 8 "Eighth Gear" 9 "Unused and Reserved 1" 10 "Unused and Reserved 2" 11 "Unused and Reserved 3" 12 "Unused and Reserved 4" 13 "Unused and Reserved 5" 14 "Unused and Reserved 6" 15 "Unused and Reserved 7";
VAL_TABLE_ EDADS_CrntFwdMsdG 0 "None" 1 "First Gear" 2 "Second Gear" 3 "Third Gear" 4 "Fourth Gear" 5 "Fifth Gear" 6 "Sixth Gear" 7 "Seventh Gear" 8 "Eighth Gear" 9 "Unused and Reserved 1" 10 "Unused and Reserved 2" 11 "Unused and Reserved 3" 12 "Unused and Reserved 4" 13 "Unused and Reserved 5" 14 "Unused and Reserved 6" 15 "Unused and Reserved 7";
VAL_TABLE_ EDADS_ShftIndStat 0 "Shift Down" 1 "Shift Up" 2 "No Shift";
VAL_TABLE_ PrsElvtdIdlCntlStat 0 "Disabled" 1 "Enabled";
VAL_TABLE_ GPCMDS2_DTCStatus 0 "Not Supported" 1 "Critically Disabled" 2 "No Status to Report" 3 "Diagnostic Passed" 4 "Diagnostic Failed";
VAL_TABLE_ EngPwrCnfg 0 "Default" 1 "Configuration 1" 2 "Configuration 2" 3 "Configuration 3" 4 "Configuration 4" 5 "Configuration 5" 6 "Configuration 6" 7 "Configuration 7" 8 "Configuration 8" 9 "Configuration 9" 10 "Configuration 10" 11 "Configuration 11" 12 "Configuration 12" 13 "Configuration 13" 14 "Configuration 14" 15 "Configuration 15";
VAL_TABLE_ CTSS_StbltyLvl 0 "Level 0" 1 "Level 1" 2 "Level 2" 3 "Level 3" 4 "Level 4" 5 "Level 5" 6 "Level 6" 7 "Level 7";
VAL_TABLE_ CTSS_StbltyTyp 0 "Normal Stability" 1 "Torque High Pulsation" 2 "Torque Decrease Pending" 3 "Torque Increase Pending" 4 "Unused and Reserved 1" 5 "Unused and Reserved 2" 6 "Unused and Reserved 3" 7 "Unused and Reserved 4";
VAL_TABLE_ DslExhFldWrngIdRqER 0 "No Indication" 1 "Warning Level 1" 2 "Warning Level 2" 3 "Warning Level 3" 4 "Warning Level 4" 5 "Warning Level 5" 6 "Warning Level 6" 7 "Warning Level 7" 8 "Warning Level 8" 9 "Warning Level 9" 10 "Warning Level 10" 11 "Warning Level 11" 12 "Warning Level 12" 13 "Warning Level 13" 14 "Warning Level 14" 15 "Warning Level 15";
VAL_TABLE_ DslExhFldQlyWrngIReq 0 "No Indication" 1 "Warning Level 1" 2 "Warning Level 2" 3 "Warning Level 3" 4 "Warning Level 4" 5 "Warning Level 5" 6 "Warning Level 6" 7 "Warning Level 7" 8 "Warning Level 8" 9 "Warning Level 9" 10 "Warning Level 10" 11 "Warning Level 11" 12 "Warning Level 12" 13 "Warning Level 13" 14 "Warning Level 14" 15 "Warning Level 15";
VAL_TABLE_ DslExNxEmWrngIndRq 0 "No Indication" 1 "Warning Level 1" 2 "Warning Level 2" 3 "Warning Level 3" 4 "Warning Level 4" 5 "Warning Level 5" 6 "Warning Level 6" 7 "Warning Level 7" 8 "Warning Level 8" 9 "Warning Level 9" 10 "Warning Level 10" 11 "Warning Level 11" 12 "Warning Level 12" 13 "Warning Level 13" 14 "Warning Level 14" 15 "Warning Level 15";
VAL_TABLE_ DslExFldTpWrngIndRq 0 "No Indication" 1 "Warning Level 1" 2 "Warning Level 2" 3 "Warning Level 3" 4 "Warning Level 4" 5 "Warning Level 5" 6 "Warning Level 6" 7 "Warning Level 7" 8 "Warning Level 8" 9 "Warning Level 9" 10 "Warning Level 10" 11 "Warning Level 11" 12 "Warning Level 12" 13 "Warning Level 13" 14 "Warning Level 14" 15 "Warning Level 15";
VAL_TABLE_ DslExFldCnWrngIndRq 0 "No Indication" 1 "Warning Level 1" 2 "Warning Level 2" 3 "Warning Level 3" 4 "Warning Level 4" 5 "Warning Level 5" 6 "Warning Level 6" 7 "Warning Level 7" 8 "Warning Level 8" 9 "Warning Level 9" 10 "Warning Level 10" 11 "Warning Level 11" 12 "Warning Level 12" 13 "Warning Level 13" 14 "Warning Level 14" 15 "Warning Level 15";
VAL_TABLE_ DrvSelMdSw3Sta 0 "Inactive" 1 "Active";
VAL_TABLE_ DrvSelMdSw2Sta 0 "Inactive" 1 "Active";
VAL_TABLE_ DrvSelMd8Stat 0 "Inactive" 1 "Active";
VAL_TABLE_ DrvSelMd7Stat 0 "Inactive" 1 "Active";
VAL_TABLE_ DrvSelMd6Stat 0 "Inactive" 1 "Active";
VAL_TABLE_ DrvSelMd5Stat 0 "Inactive" 1 "Active";
VAL_TABLE_ DrvSelMd4Stat 0 "Inactive" 1 "Active";
VAL_TABLE_ DrvSelMd3Stat 0 "Inactive" 1 "Active";
VAL_TABLE_ DrvSelMd2Stat 0 "Inactive" 1 "Active";
VAL_TABLE_ A6ERRAlrmReq 0 "No Action" 1 "Set Alarm" 2 "Cancel Alarm";
VAL_TABLE_ MntnceMdDsplyRq 0 "No Request" 1 "EM 5 Day Warning" 2 "EM 4 Day Warning" 3 "EM 3 Day Warning" 4 "EM 2 Day Warning" 5 "EM 1 Day Warning" 6 "Force EM" 7 "Continue EM" 8 "FM 5 Day Warning" 9 "FM 4 Day Warning" 10 "FM 3 Day Warning" 11 "FM 2 Day Warning" 12 "FM 1 Day Warning" 13 "Force FM" 14 "Continue FM" 15 "Unused and Reserved";
VAL_TABLE_ HybACCompRq 0 "No Action" 1 "Engage" 2 "Disengage" 3 "Reserved";
VAL_TABLE_ TrnsInpDvcStat 0 "Normal Control" 1 "Temporary Isolation" 2 "Permanent Isolation" 3 "Unused and Reserved 1" 4 "Unused and Reserved 2" 5 "Unused and Reserved 3" 6 "Unused and Reserved 4" 7 "Unused and Reserved 5";
VAL_TABLE_ AuxClntHtrVlvStat 0 "Engine Bypass" 1 "Transition" 2 "Engine Link" 3 "Fault Active" 4 "Re-Calibration" 5 "Diagnostic Override" 6 "De-Aeration Routine Active" 7 "Unused and Reserved 2";
VAL_TABLE_ DrvSelMdSw1Sta 0 "Inactive" 1 "Active";
VAL_TABLE_ VICntlModRunCrkTrmSt 0 "Inactive" 1 "Active";
VAL_TABLE_ DrvSelMd1Stat 0 "Inactive" 1 "Active";
VAL_TABLE_ ETC_EngOpMd 0 "All cylinders" 1 "Half Cylinders";
VAL_TABLE_ EngCntrlUtldTrnCsRng 0 "High" 1 "Low" 2 "Unused and Reserved" 3 "Neutral";
VAL_TABLE_ CSTATRS_ReqStat 0 "No Request" 1 "Request Honored" 2 "Lost Arbitration" 3 "Serial Data Failure Temporary" 4 "Serial Data Failure Permanent" 5 "Control System Failure Temporary" 6 "Control System Failure Permanent";
VAL_TABLE_ CSTATRS_LmtgStat 0 "Not Limited" 1 "Rate Limited" 2 "Value Limited" 3 "Rate and Value Limited";
VAL_TABLE_ PTTrnsfrCseMd 0 "2 Wheel Drive High" 1 "4 Wheel Drive High" 2 "4 Wheel Drive Low" 3 "Neutral";
VAL_TABLE_ TrnsHybEngSrtStpOvrd 0 "No Override" 1 "Engine On" 2 "Engine Off";
VAL_TABLE_ EngCntrlDtrmdTrfCRng 0 "High" 1 "Low" 2 "Unused and Reserved" 3 "Neutral";
VAL_TABLE_ ElecPrkBrkAvailStat 0 "Unavailable, Not Failed" 1 "Available, Not Failed" 2 "Unavailable, Failed Applied" 3 "Unavailable, Failed Released" 4 "Unavailable, Failed other" 5 "Unused and Reserved 1" 6 "Unused and Reserved 2" 7 "Unused and Reserved 3";
VAL_TABLE_ ElecPrkBrkApplStat 0 "Unknown" 1 "Park Brake Applied" 2 "Park brake Released" 3 "Park Brake Application in Progress";
VAL_TABLE_ BCHR_BattCrntRwVlMu 0 "Multiplier Factor 1" 1 "Multiplier Factor 8" 2 "Multiplier Factor 64" 3 "Multiplier Factor 256";
VAL_TABLE_ BattSOXStat 0 "Don't Use SOC,SOH, & SOF" 1 "Use SOC,SOH, & SOF";
VAL_TABLE_ CSPATR_TrqIntrvnTyp 0 "No Intervention" 1 "Maximum Limit" 2 "Minimum Limit" 3 "Minimum and Maximum Limit";
VAL_TABLE_ CSPATR_TrqRqTyp 0 "Absolute Torque Request";
VAL_TABLE_ ChsSysAxlTqRqRspTyp 0 "Inactive" 1 "Pleasability Limited Request" 2 "Maximum Range Request" 3 "Automatic Actuator Selection" 4 "Braking Torque Request";
VAL_TABLE_ EngOffTmPTM 0 "Don't Use Data" 1 "Use Data";
VAL_TABLE_ HybMdDisp 0 "Default / Accessory" 1 "Engine Idle" 2 "Auto Stop" 3 "Battery Power 2WD" 4 "Battery Power 4WD" 5 "Engine Power 2WD" 6 "Engine Power 4WD" 7 "Hybrid Power 2WD" 8 "Hybrid Power 4WD" 9 "Charging With Engine Off" 10 "Charging With Engine On" 11 "Undetermined" 12 "Battery Power Load Sharing" 13 "Engine Power Load Sharing" 14 "Engine Charging Battery Moving" 15 "Engine Charging Battery While Idle";
VAL_TABLE_ PerfTrcTrqRqStat 0 "No Request" 1 "Request Honored" 2 "Lost Arbitration" 3 "Serial Data Failure Temporary" 4 "Serial Data Failure Permanent" 5 "Control System Failure Temporary" 6 "Control System Failure Permanent";
VAL_TABLE_ PTTR_TrqRedRlzSugg 0 "No Suggestion" 1 "Transient Optimized";
VAL_TABLE_ PTTR_TrqInvTyp 0 "No Intervention" 1 "Maximum Limit";
VAL_TABLE_ PerfTrcTrqLmtStat 0 "Not Limited" 1 "Rate Limited" 2 "Value Limited" 3 "Rate & Value Limited";
VAL_TABLE_ PerfTrcEngSpdRqStat 0 "No Request" 1 "Request Honored" 2 "Lost Arbitration" 3 "Serial Data Failure Temporary" 4 "Serial Data Failure Permanent" 5 "Control System Failure Temporary" 6 "Control System Failure Permanent";
VAL_TABLE_ PTESR_EngSpdCntlRs 0 "No Suggestion" 1 "Transient Optimized" 2 "Stability Optimized Cond 1" 3 "Stability Optimized Cond 2";
VAL_TABLE_ PTESR_EngSpdIntTyp 0 "No Intervention" 1 "Engine Speed Max Limit";
VAL_TABLE_ PerfTrcEngSpdLmtStat 0 "Not Limited" 1 "Rate Limited" 2 "Value Limited" 3 "Rate & Value Limited";
VAL_TABLE_ TPCTR_TrqIntrvnTyp 0 "No Request" 1 "Maximum Limit" 2 "Minimum Limit" 3 "Unused and Reserved";
VAL_TABLE_ TICTR_TorqRespTyp 0 "Inactive" 1 "Pleasability Limited" 2 "Maximum Range" 3 "Automatic Actuator Selection";
VAL_TABLE_ EngCrsCntrlMode 0 "Inactive" 1 "Engaged" 2 "Resume" 3 "Accel" 4 "Coast" 5 "Tap";
VAL_TABLE_ EngPrdctTrqTnsRqStat 0 "No Request" 1 "Request Honored" 2 "Lost Arbitration" 3 "Serial Data Failure Temporary" 4 "Serial Data Failure Permanent" 5 "Control System Failure Temporary" 6 "Control System Failure Permanent" 7 "Unused and Reserved";
VAL_TABLE_ EngPrdctTrqTnsRqLmS 0 "Not Limited" 1 "Rate Limited" 2 "Value Limited Low" 3 "Value Limited High" 4 "Unused and Reserved 1" 5 "Unused and Reserved 2" 6 "Unused and Reserved 3" 7 "Unused and Reserved 4";
VAL_TABLE_ EngImmTrqTnsRqStat 0 "No Request" 1 "Request Honored" 2 "Lost Arbitration" 3 "Serial Data Failure Temporary" 4 "Serial Data Failure Permanent" 5 "Control System Failure Temporary" 6 "Control System Failure Permanent" 7 "Unused and Reserved";
VAL_TABLE_ EngImmTrqTnsRqLmSt 0 "Not Limited" 1 "Rate Limited" 2 "Value Limited Low" 3 "Value Limited High" 4 "Unused and Reserved 1" 5 "Unused and Reserved 2" 6 "Unused and Reserved 3" 7 "Unused and Reserved 4";
VAL_TABLE_ CrsSpdLmtrSwStat 0 "Indeterminate" 1 "No Activation" 2 "Resume" 3 "Set" 4 "SL/SW On/Off/GAP" 5 "Cruise On/Off" 6 "Cancel" 7 "Open/Short to Ground" 8 "Short to Power" 9 "Between Ranges";
VAL_TABLE_ RrAxlSta 0 "Normal" 1 "Temporary Inhibit" 2 "Temporary Limited" 3 "Permanently Failed";
VAL_TABLE_ SecAxlStat 0 "Normal" 1 "Temporary Inhibit" 2 "Temporary Limited" 3 "Permanently Failed";
VAL_TABLE_ HESSI_EngStrtTyp 0 "No Start" 1 "Key Start Normal" 2 "Key Start Low Power" 3 "Key Start Low Power B" 4 "Key Start Generic" 5 "Auto Start Smooth" 6 "Auto Start Normal" 7 "Auto Start Aggressive" 8 "Auto Start Generic" 9 "Compression Test";
VAL_TABLE_ HESSI_EngStrtStpMd 0 "Stop" 1 "Immediate Stop" 2 "Start Pending" 3 "Enable Fuel" 4 "Producing Torque" 5 "Disable Fuel" 6 "Stop Pending" 7 "Start Failed";
VAL_TABLE_ HybDFCOReq 0 "DFCO Not Requested" 1 "DFCO Requested";
VAL_TABLE_ EngCntlSenPTRlyVltM 0 "Don't Use Data" 1 "Use Data";
VAL_TABLE_ GPCMDS_DTCStatus 0 "Not Supported" 1 "Critically Disabled" 2 "No Status to Report" 3 "Diagnostic Passed" 4 "Diagnostic Failed";
VAL_TABLE_ IQAI_InjIdInd 0 "Injector 1" 1 "Injector 2" 2 "Injector 3" 3 "Injector 4" 4 "Injector 5" 5 "Injector 6" 6 "Injector 7" 7 "Injector 8";
VAL_TABLE_ IQAI_DataStat 0 "IQA Data Byte Not Stored" 1 "IQA Data Byte Stored";
VAL_TABLE_ ACCATC_DrvAstdGoSt 0 "Not Stopped" 1 "Apply Accel Pedal to Go" 2 "Apply Acc Pedal or Resume Sw To Go";
VAL_TABLE_ WhlSlpSt 0 "No Slip Detected" 1 "Negative Slip Detected" 2 "Positive Slip Detected" 3 "Slip Detection Fault";
VAL_TABLE_ EnhSvVehTopSpdLmR 0 "No Action" 1 "Active" 2 "Inactive";
VAL_TABLE_ ACCmEngRunReq 0 "No Action" 1 "Engine Run Requested";
VAL_TABLE_ FuelMdSwAct 0 "False" 1 "True";
VAL_TABLE_ FuelMdStat 0 "Gasoline Mode" 1 "Natural Gas Mode" 2 "Liquified Petroleum Gas Mode" 3 "Alternative Fuel Cut-off Active";
VAL_TABLE_ WrmUpShftPtrnRq 0 "Inactive" 1 "Active";
VAL_TABLE_ EngCntrlRunCrnkTrmSt 0 "Inactive" 1 "Active";
VAL_TABLE_ ACCATC_ACCTyp 0 "Adaptive Cruise Control" 1 "Full Speed Range ACC" 2 "Full Speed Range ACC with Booster";
VAL_TABLE_ ACCATCS_RqStat 0 "No Request" 1 "Request Honored" 2 "Lost Arbitration" 3 "Request Denied" 4 "Request Suspended Till Driver Input";
VAL_TABLE_ ACCATCS_LmtgStat 0 "Request Not Limited" 1 "Request Value Limited Minimum" 2 "Request Value Limited Maximum" 3 "Request Rate Limited";
VAL_TABLE_ EPBSysWrnIndReq 0 "No Indication" 1 "Continuous Indication" 2 "Flash Rate #1 Indication" 3 "Flash Rate #2 Indication";
VAL_TABLE_ VehSpeSta 0 "Stationary" 1 "Slow" 2 "Fast" 3 "Invalid";
VAL_TABLE_ DslPartFltrClngAlgActM 0 "Don't Use Data" 1 "Use Data";
VAL_TABLE_ SecAxlOpeMod 0 "2 Wheel Drive High" 1 "4 Wheel Drive High Locked" 2 "4 Wheel Drive Low Locked" 3 "Active All Wheel Drive (High)" 4 "4 Wheel Drive High Open" 5 "4 Wheel Drive Low Open" 6 "Active All Wheel Drive (Low)" 7 "2 Wheel Drive Low" 14 "Unknown" 15 "Neutral";
VAL_TABLE_ SecAxlCtrlMod 0 "Internal" 1 "External";
VAL_TABLE_ RrAxlOpeMod 0 "Open" 1 "Active" 2 "Locked" 3 "Unknown";
VAL_TABLE_ RrAxlCtrlMod 0 "Internal" 1 "External";
VAL_TABLE_ EPBSwSta 0 "NotActive" 1 "Release" 2 "Apply";
VAL_TABLE_ EPBSta 0 "Released" 1 "Applied" 2 "Fault";
VAL_TABLE_ FlPmpEDscOtptCmdSta 0 "Fuel Pump Disabled" 1 "Fuel Pump Enabled";
VAL_TABLE_ TransTUDMdStat 0 "No Activation" 1 "Driver Shift Control Active" 2 "Electronic Range Select Active";
VAL_TABLE_ TrnShftPtrnActStat 0 "Default Shift Pattern Active" 1 "Shift Pattern 1 Active" 2 "Shift Pattern 2 Active" 3 "Shift Pattern 3 Active" 4 "Shift Pattern 4 Active" 5 "PT Non-Protection Pattern Active" 6 "PT Protection Pattern Active";
VAL_TABLE_ EPBSysAudWarnReq 0 "Off" 1 "Warning #1" 2 "Warning #2";
VAL_TABLE_ NotEventSta 0 "No Event" 1 "Near Deployment Event" 2 "Pretensioner Deployment Event" 3 "Airbag Deployment Event";
VAL_TABLE_ VehMovSta 0 "Parked" 1 "Neutral" 2 "Forward" 3 "Reverse" 4 "Invalid";
VAL_TABLE_ PFTrnsTUDSwSt 0 "No Activation" 1 "Increment Switch Active" 2 "Decrement Switch Active" 3 "Illegal Up/Down Switch State Active";
VAL_TABLE_ PFTrnsTUDEnSwSt 0 "No Activation" 1 "Driver Shift Control Enable Switch" 2 "Electronic Range Select Enable Sw" 3 "Illegal Enable Switch State";
VAL_TABLE_ AuxHtrRq 0 "Off" 1 "On";
VAL_TABLE_ TrnsEngdState 0 "Transmission Not Engaged" 1 "Transmission Engaged in Forward" 2 "Transmission Engaged in Reverse" 3 "Operating State Not Reached";
VAL_TABLE_ EPBSysDspMsgReq 0 "Off" 1 "Message #1" 2 "Message #2" 3 "Message #3" 4 "Message #4" 5 "Message #5" 6 "Message #6" 7 "Message #7";
VAL_TABLE_ OtsdAmbtLtLvlStat 0 "Unknown" 1 "Night" 2 "Day";
VAL_TABLE_ RdSpdCatType 0 "all speed categories > 130 km/h" 1 "all speed categories 81-130 km/h" 2 "all speed categories 51-80 km/h" 3 "all speed categories 0 - 50 km/h";
VAL_TABLE_ LnCat 0 "no info available" 1 "One lane" 2 "Two Or Three Lanes" 3 "Four Or More Lanes";
VAL_TABLE_ FncRdClass 0 "LOCAL (Residential Road)" 1 "SFREEWAY" 2 "FREEWAY" 3 "PED-MALL" 4 "HIGHWAY" 5 "ARTERIAL" 6 "ALLEY" 7 "COLLECTOR";
VAL_TABLE_ CustomizationSettingRequest 0 "No Action" 1 "Performance Mode 1" 2 "Performance Mode 2" 3 "Performance Mode 3" 4 "Performance Mode 4" 5 "Performance Mode 5" 6 "Performance Mode 6" 7 "Auto";
VAL_TABLE_ RstrCustFctrDef 0 "No Action" 1 "Restore Defaults";
VAL_TABLE_ PFTrnsTUDSecSwSt 0 "No Activation" 1 "Increment Switch Active" 2 "Decrement Switch Active" 3 "Illegal Up/Down Switch State Active";
VAL_TABLE_ AdvFrntLghtSysIndRq 0 "No Indication" 1 "Indication 1" 2 "Indication 2" 3 "Indication 3" 4 "Indication 4" 5 "Indication 5" 6 "Indication 6" 7 "Indication 7";
VAL_TABLE_ CustomizationCurrentSettingValue 0 "No Action" 1 "Performance Mode 1" 2 "Performance Mode 2" 3 "Performance Mode 3" 4 "Performance Mode 4" 5 "Performance Mode 5" 6 "Performance Mode 6" 7 "Auto";
VAL_TABLE_ EPBSysStatIndReq 0 "No Indication" 1 "Continuous Indication" 2 "Flash Rate 1 Indication" 3 "Flash Rate 2 Indication";
VAL_TABLE_ AllNodesVNA 0 "No Activation" 1 "Activate Virtual Network";
VAL_TABLE_ ClntCircPmpRq 0 "Off" 1 "On";
VAL_TABLE_ ImoIdSt 0 "No info" 1 "Info valid";
VAL_TABLE_ LrnEnvIdSt 0 "No_info" 1 "Info_valid";
VAL_TABLE_ EnvIdRspSt4 0 "No_info" 1 "Info_valid" 2 "Incorrect_immo_id" 3 "Environment_id_request";
VAL_TABLE_ VDAvailability 0 "VirtualDeviceUnavailable" 1 "VirtualDeviceAvailable";
VAL_TABLE_ AlrmStat 0 "Off" 1 "Armed" 2 "Disarmed" 3 "Alarm Active" 4 "Arming Delay";
VAL_TABLE_ RstVTDTmprDtctd 0 "No Action" 1 "Reset";
VAL_TABLE_ RstIllDrIdDevDtctd 0 "No Action" 1 "Reset";
VAL_TABLE_ RstDrIdDevLrnd 0 "No Action" 1 "Reset";
VAL_TABLE_ CldrMth 0 "Unknown" 1 "January" 2 "February" 3 "March" 4 "April" 5 "May" 6 "June" 7 "July" 8 "August" 9 "September" 10 "October" 11 "November" 12 "December";
VAL_TABLE_ TrnSwAct 0 "No Activation" 1 "Left" 2 "Right";
VAL_TABLE_ VehHghtStat 0 "Unknown" 1 "Normal Design Ride Height" 2 "Aerodynamic Height" 3 "Kneeling Height" 4 "Maximum Height";
VAL_TABLE_ HdlmpBmSelectStat 0 "Unknown" 1 "Low Beams" 2 "High Beams";
VAL_TABLE_ ACSAlarm9 0 "Inactive" 1 "Active" 2 "Expired";
VAL_TABLE_ ACSAlarm8 0 "Inactive" 1 "Active" 2 "Expired";
VAL_TABLE_ ACSAlarm7 0 "Inactive" 1 "Active" 2 "Expired";
VAL_TABLE_ ACSAlarm6 0 "Inactive" 1 "Active" 2 "Expired";
VAL_TABLE_ ACSAlarm5 0 "Inactive" 1 "Active" 2 "Expired";
VAL_TABLE_ ACSAlarm4 0 "Inactive" 1 "Active" 2 "Expired";
VAL_TABLE_ ACSAlarm3 0 "Inactive" 1 "Active" 2 "Expired";
VAL_TABLE_ ACSAlarm2 0 "Inactive" 1 "Active" 2 "Expired";
VAL_TABLE_ ACSAlarm15 0 "Inactive" 1 "Active" 2 "Expired";
VAL_TABLE_ ACSAlarm14 0 "Inactive" 1 "Active" 2 "Expired";
VAL_TABLE_ ACSAlarm13 0 "Inactive" 1 "Active" 2 "Expired";
VAL_TABLE_ ACSAlarm12 0 "Inactive" 1 "Active" 2 "Expired";
VAL_TABLE_ ACSAlarm11 0 "Inactive" 1 "Active" 2 "Expired";
VAL_TABLE_ ACSAlarm10 0 "Inactive" 1 "Active" 2 "Expired";
VAL_TABLE_ ACSAlarm1 0 "Inactive" 1 "Active" 2 "Expired";
VAL_TABLE_ ACSAlarm0 0 "Inactive" 1 "Active" 2 "Expired";
VAL_TABLE_ ACCHdwyStg 0 "Minimum Headway Setting" 1 "Headway Setting 1" 2 "Headway Setting 2" 3 "Headway Setting 3" 4 "Headway Setting 4" 5 "Headway Setting 5" 6 "Headway Setting 6" 7 "Headway Setting 7";
VAL_TABLE_ VehStabEnhmntMd 0 "Off" 1 "Normal" 2 "Competitive";
VAL_TABLE_ VehStabEnhmntStat 0 "Inactive" 1 "Active" 2 "Fault" 3 "Warming Up" 4 "Not Ready";
VAL_TABLE_ TCSysOpMd 0 "Off" 1 "Normal" 2 "Off Road";
VAL_TABLE_ TCSysOpStat 0 "Inactive" 1 "Active" 2 "Fault";
VAL_TABLE_ HillDscntCntlSysStat 0 "Normal" 1 "Enabled" 2 "Active" 3 "Failed" 4 "Temporarily Inhibited";
VAL_TABLE_ EnrgMgtLdShdRq 0 "No Load Shedding" 1 "Load Shed Level 1" 2 "Load Shed Level 2" 3 "Load Shed Level 3" 4 "Load Shed Level 4";
VAL_TABLE_ DrId 0 "Driver #1" 1 "Driver #2" 2 "Driver #3" 3 "Driver #4" 4 "Driver #5" 5 "Driver #6" 6 "Driver #7" 7 "Unknown";
VAL_TABLE_ TireRRPrsStat 0 "Unknown" 1 "Nominal" 2 "Low - Service Now" 3 "Low" 4 "Low - Extended Mobility" 5 "High";
VAL_TABLE_ TireRFPrsStat 0 "Unknown" 1 "Nominal" 2 "Low - Service Now" 3 "Low" 4 "Low - Extended Mobility" 5 "High";
VAL_TABLE_ TireLRPrsStat 0 "Unknown" 1 "Nominal" 2 "Low - Service Now" 3 "Low" 4 "Low - Extended Mobility" 5 "High";
VAL_TABLE_ TireLFPrsStat 0 "Unknown" 1 "Nominal" 2 "Low - Service Now" 3 "Low" 4 "Low - Extended Mobility" 5 "High";
VAL_TABLE_ DTCI_DTCFaultType 0 "Not Supported" 1 "Type A" 2 "Type B" 3 "Type C";
VAL_TABLE_ DistRollCntAvgDrvnSrc 0 "Transmission Output Speed" 1 "Wheel Speed";
VAL_TABLE_ VehSpdAvgDrvnSrc 0 "Transmission Output Speed" 1 "Wheel Speed";
VAL_TABLE_ TORSLstTransType 0 "Single Edge Sensor" 1 "Rising Transition" 2 "Falling Transition" 3 "Undefined";
VAL_TABLE_ TORSRotDir 0 "Unknown" 1 "Forward" 2 "Reverse" 3 "Undefined";
VAL_TABLE_ TrnsThrmlMngmntStat 0 "Normal" 1 "Countermeasures Active" 2 "Driver Intervention Requested";
VAL_TABLE_ TrnsSftMdStat 0 "No Override Mode" 1 "Performance Mode" 2 "Lift-Foot Cornering Mode" 3 "Automatic Grade Braking Mode";
VAL_TABLE_ TrnsRngInhbtStat 0 "No Range Inhibit Active" 1 "Transmission Inhibit Active" 2 "Transmission Range Re-Selection Req" 3 "Driveline Not Engaged" 4 "Diagnostic Inhibit Active";
VAL_TABLE_ DrvtShftCntrlTrgtGear 0 "Not Supported" 1 "First Gear" 2 "Second Gear" 3 "Third Gear" 4 "Fourth Gear" 5 "Fifth Gear" 6 "Sixth Gear" 7 "Seventh Gear" 8 "Eighth Gear";
VAL_TABLE_ StrWhlAngSenCalStat 0 "Unknown" 1 "Estimated" 2 "Calibrated";
VAL_TABLE_ PTOTGRReqdGear 0 "No Action" 1 "First Gear" 2 "Second Gear" 3 "Third Gear" 4 "Fourth Gear" 5 "Fifth Gear" 6 "Sixth Gear" 7 "Seventh Gear" 8 "Eighth Gear";
VAL_TABLE_ PTOTGRReqType 0 "No Action" 1 "Max Gear Request" 2 "Min Gear Request" 3 "Hold Gear";
VAL_TABLE_ PTORmtEngStrtReq 0 "PTO Remote Start Not Requested" 1 "PTO Remote Start Requested";
VAL_TABLE_ FSERDTC_SysDes 0 "P0-Powertrain Codes SAE Controlled" 1 "P1-Powertrain Codes MFG Controlled" 2 "P2-Powertrain Codes Reserved" 3 "P3-Powertrain Codes Reserved" 4 "C0-Chassis Codes SAE Controlled" 5 "C1-Chassis Codes MFG Controlled" 6 "C2-Chassis Codes Reserved" 7 "C3-Chassis Codes Reserved" 8 "B0-Body Codes SAE Controlled" 9 "B1-Body Codes MFG Controlled" 10 "B2-Body Codes Reserved" 11 "B3-Body Codes Reserved" 12 "U0-Network Codes SAE Controlled" 13 "U1-Network Codes MFG Controlled" 14 "U2-Network Codes Reserved" 15 "U3-Network Codes Reserved";
VAL_TABLE_ EngFuelCntlState 0 "Open Loop" 1 "Non-Stoichiometric Closed Loop" 2 "Stoichiometric Closed Loop";
VAL_TABLE_ EngTrqRdFlrSt 0 "Torque Reduction OK" 1 "Torque Reduction Temporarily Failed" 2 "Torque Reduction Permanently Failed" 3 "Torque Reduction Limited" 4 "Torq Reduction Communication Failed";
VAL_TABLE_ ParkNeutralSwStat 0 "Park/Neutral" 1 "Not Park/Neutral";
VAL_TABLE_ EngBrkStat 0 "Inactive" 1 "Active Not Absorbing Torque" 2 "Active Absorbing Torque";
VAL_TABLE_ ETGRReqdGear 0 "No Action" 1 "First Gear" 2 "Second Gear" 3 "Third Gear" 4 "Fourth Gear" 5 "Fifth Gear" 6 "Sixth Gear" 7 "Seventh Gear" 8 "Eighth Gear";
VAL_TABLE_ ETGRReqType 0 "No Action" 1 "Max Gear Request" 2 "Min Gear Request" 3 "Hold Gear";
VAL_TABLE_ OAT_PT_EstM 0 "Don't Use Data" 1 "Use Data";
VAL_TABLE_ ACCompCmnd 0 "Off" 1 "On";
VAL_TABLE_ EngEmsRelMalfIndReq 0 "Continuous Indication" 1 "No Indication" 2 "Flashing 1 Hertz Indication" 3 "Flashing 2 Hertz Indication" 4 "Flashing 0.5 Hertz Indication";
VAL_TABLE_ EngCylDeactMd 0 "All Cylinders Active" 1 "Deactivation In Progress" 2 "Half of Total Cylinders Active" 3 "Reactivation In Progress";
VAL_TABLE_ PltfrmEngSpdCmdInhtRq 0 "Allow Platform Engine Speed Control" 1 "Inhibit Platform Eng. Speed Control";
VAL_TABLE_ PT_BrkPedDscrtInpStat 0 "Brake Not Applied" 1 "Brake Applied";
VAL_TABLE_ EngSpdStat 0 "Normal Operation" 1 "Degraded Operation" 3 "Invalid";
VAL_TABLE_ TrnsCyDactTransStat 0 "Not Ready" 1 "Ready for All Cylinders" 2 "Ready for Half of TotalCylinders";
VAL_TABLE_ ACCompSysVDM 0 "Don't Use Data" 1 "Use Data";
VAL_TABLE_ BkupPwrModeMstrVDM 0 "Don't Use Data" 1 "Use Data";
VAL_TABLE_ PrkBrkVDM 0 "Don't Use Data" 1 "Use Data";
VAL_TABLE_ DispMeasSys 0 "Metric" 1 "English";
VAL_TABLE_ ACCompModReq 0 "Disengage Immediately" 1 "Disengage" 2 "Engage" 3 "No Action";
VAL_TABLE_ TransNtrlCntrlMdStat 0 "Neutral Control Not Active" 1 "Entering Neutral Control" 2 "Neutral Control Active" 3 "Exiting Neutral Control";
VAL_TABLE_ ACCompType 0 "None" 1 "Fixed Displacement Clutched" 2 "Variable Displacement Mechanical" 3 "Variable Displacement Electronic" 4 "Electric Driven Motor";
VAL_TABLE_ TrnsShftLvrPos 0 "Between Ranges" 1 "Park Range" 2 "Reverse Range" 3 "Neutral Range" 4 "Forward Range A" 5 "Forward Range B" 6 "Forward Range C" 7 "Forward Range D" 8 "Forward Range E" 9 "Forward Range F" 10 "Forward Range G" 11 "Forward Range H" 15 "Lever Position Unknown";
VAL_TABLE_ TrnsTrqCnvCltCmndMd 0 "Unlocked" 1 "Transitioning" 2 "Controlled Slip" 3 "Locked" 7 "Not Supported";
VAL_TABLE_ AutoTransComndGear 0 "Not Supported" 1 "First Gear" 2 "Second Gear" 3 "Third Gear" 4 "Fourth Gear" 5 "Fifth Gear" 6 "Sixth Gear" 7 "Seventh Gear" 8 "Eighth Gear" 10 "EVT Mode 1" 11 "EVT Mode 2" 12 "CVT Forward Gear" 13 "Neutral Gear" 14 "Reverse Gear" 15 "Park Gear";
VAL_TABLE_ AutoTransGrSftDirect 0 "No Shift in Progress" 1 "Upshift in Progress" 2 "Downshift in Progress";
VAL_TABLE_ TransEstGear 0 "Not Supported" 1 "First Gear" 2 "Second Gear" 3 "Third Gear" 4 "Fourth Gear" 5 "Fifth Gear" 6 "Sixth Gear" 7 "Seventh Gear" 8 "Eighth Gear" 10 "EVT Mode 1" 11 "EVT Mode 2" 12 "CVT Forward Gear" 13 "Neutral Gear" 14 "Reverse Gear" 15 "Park Gear";
VAL_TABLE_ TERDTC_SysDes 0 "P0-Powertrain Codes SAE Controlled" 1 "P1-Powertrain Codes MFG Controlled" 2 "P2-Powertrain Codes Reserved" 3 "P3-Powertrain Codes Reserved" 4 "C0-Chassis Codes SAE Controlled" 5 "C1-Chassis Codes MFG Controlled" 6 "C2-Chassis Codes Reserved" 7 "C3-Chassis Codes Reserved" 8 "B0-Body Codes SAE Controlled" 9 "B1-Body Codes MFG Controlled" 10 "B2-Body Codes Reserved" 11 "B3-Body Codes Reserved" 12 "U0-Network Codes SAE Controlled" 13 "U1-Network Codes MFG Controlled" 14 "U2-Network Codes Reserved" 15 "U3-Network Codes Reserved";
VAL_TABLE_ TESR_EngSpdCntlRsp 0 "No Suggestion" 1 "Transient Optimized" 2 "Stability Optimized Condition 1" 3 "Stability Optimized Condition 2";
VAL_TABLE_ TESR_EngSpdIntTyp 0 "No Intervention" 1 "Engine Speed Max Limit" 2 "Engine Speed Min Limit";
VAL_TABLE_ TTRLT_TqRdnRlznSgg 0 "No Suggestion" 1 "Transient Optimized" 2 "Stability Optimized 1" 3 "Stability Optimized 2";
VAL_TABLE_ TTRLT_TorqInvntnTyp 0 "No Intervention" 1 "Maximum Limit" 2 "Minimum Limit";
VAL_TABLE_ TTRST_TorqInvntnTyp 0 "No Intervention" 1 "Maximum Limit";
VAL_TABLE_ PTORmStMsEngStRq 0 "PTO Remote Start Not Requested" 1 "PTO Remote Start Requested";
VAL_TABLE_ PFESpdCmdSwDIntg 0 "Data Valid" 1 "Data Invalid" 2 "Failure Detected";
VAL_TABLE_ RmVehStrRq 0 "Remote Start Not Requested" 1 "Remote Start Requested";
VAL_TABLE_ VehSpdCntlSystmType 0 "No Vehicle Speed Control" 1 "Conventional Cruise Control" 2 "Adaptive Cruise Control";
VAL_TABLE_ PF_MinIdlBstLvlReq 0 "No Boost Requested" 1 "Boost Level 1" 2 "Boost Level 2" 3 "Boost Level 3";
VAL_TABLE_ PltfrmEngSpdCmdSysTp 0 "No Platform Eng. Speed Command Sys." 1 "Stationary PTO" 2 "Stationary Variable PTO" 3 "Mobile Variable PTO" 4 "Fast Idle" 5 "Enhanced Fast Idle" 6 "Auto Elevated Idle";
VAL_TABLE_ ThrtlPrgrsnReq 0 "Map A" 1 "Map B" 2 "Map C";
VAL_TABLE_ PMMAccTrmSt 0 "Inactive" 1 "Active";
VAL_TABLE_ PMMRunCrkTrmSt 0 "Inactive" 1 "Active";
VAL_TABLE_ SysBkUpPwrMd 0 "Off" 1 "Accessory" 2 "Run" 3 "Crank Request";
VAL_TABLE_ SysPwrMd 0 "Off" 1 "Accessory" 2 "Run" 3 "Crank Request";
VAL_TABLE_ ImmblzrPreRelPswdStat 0 "No Information" 1 "Information Valid";
VAL_TABLE_ AdptCrsGapSwAct 0 "No Activation" 1 "Decrease Gap" 2 "Increase Gap";
VAL_TABLE_ CrsCntrlSwStSwDataIntgty 0 "Data Valid" 1 "Data Invalid" 2 "Failure Detected" 3 "Illegal Range";
VAL_TABLE_ CrsCntCncRq 0 "Do Not Cancel" 1 "Cancel";
VAL_TABLE_ WhlSpdSnsgDTCStat 0 "Not Supported" 1 "Critically Disabled" 2 "No Status to Report" 3 "Diagnostic Passed" 4 "Diagnostic Failed";
VAL_TABLE_ SprTireSt 0 "Undetermined" 1 "No Spare Detected" 2 "Spare Detected";
VAL_TABLE_ BSTGRReqdGear 0 "No Action" 1 "First Gear" 2 "Second Gear" 3 "Third Gear" 4 "Fourth Gear" 5 "Fifth Gear" 6 "Sixth Gear" 7 "Seventh Gear" 8 "Eighth Gear";
VAL_TABLE_ BSTGRReqType 0 "No Action" 1 "Max Gear Request" 2 "Min Gear Request" 3 "Hold Gear";
VAL_TABLE_ VhDynCntlSysSt 0 "Normal Operation" 1 "Reduced Function" 2 "Temporarily Inhibited" 3 "Permanently Failed" 4 "Warming Up" 5 "Calibrating" 6 "Enhanced Operation" 7 "Driver Disabled";
VAL_TABLE_ TracCntrlSysDrIntnt 0 "Disabled" 1 "Enabled";
VAL_TABLE_ ValidityStates 0 "Valid" 1 "Invalid";
VAL_TABLE_ MainLghtSw 0 "AUTO" 1 "OFF" 2 "PARKLAMP" 3 "HEADLAMP";
VAL_TABLE_ ExhPrsRgVlvPos 0 "Open" 1 "Closed";
VAL_TABLE_ CSETRER_TqIntvnTyp 0 "No Intervention" 1 "Reduce Torque" 2 "Increase Torque";
BO_TX_BU_ 844:EBCM_OBD_HS,EBCM_HS;
BO_TX_BU_ 426:PCM_HS,ECM_HS;
BO_TX_BU_ 208:EBCM_OBD_HS,EBCM_HS;
BO_TX_BU_ 563:EBCM_OBD_HS,EBCM_HS;
BO_TX_BU_ 1247:ICCM_OBD_HS,ICCM_HS;
BO_TX_BU_ 419:PCM_HS,ECM_HS;
BO_TX_BU_ 866:EBCM_OBD_HS,EBCM_HS;
BO_TX_BU_ 951:VCM_HS,FICM_HS;
BO_TX_BU_ 1223:PCM_HS,ECM_HS;
BO_TX_BU_ 479:BCP_HS,ECM_HS,HCP_HS;
BO_TX_BU_ 211:HCP_HS,PCM_HS,ECM_HS;
BO_TX_BU_ 1020:PCM_HS,ECM_HS;
VAL_ 844 IMUProtYawRtM 0 "Don't Use Data" 1 "Use Data";
VAL_ 844 IMUProtLonAccM 0 "Don't Use Data" 1 "Use Data";
VAL_ 844 IMUProtLatAccM 0 "Don't Use Data" 1 "Use Data";
VAL_ 308 PFAS_SrvPedAlrtIO 0 "false" 1 "true";
VAL_ 308 PFAS_PFASysStat 0 "Disable" 1 "Active" 2 "Fault" 3 "Unused and Reserved";
VAL_ 308 PFAS_PFASndGenEn 0 "false" 1 "true";
VAL_ 308 PFAS_PFARevSnd 0 "No Action" 1 "Sound #1" 2 "Sound #2" 3 "Sound #3";
VAL_ 308 PFAS_PFAFwdSnd 0 "No Action" 1 "Sound #1" 2 "Sound #2" 3 "Sound #3";
VAL_ 308 PedFrndlyAlrtCsSetAvl 0 "false" 1 "true";
VAL_ 308 PedFrndlyAlrtCsCrStVal 0 "No Value" 1 "Off" 2 "On";
VAL_ 806 DCCnvStblznErrIO 0 "false" 1 "true";
VAL_ 426 EngPrdctStdyStTorqV 0 "Valid" 1 "Invalid";
VAL_ 426 CrnkShftTrqMinOffCapV 0 "Valid" 1 "Invalid";
VAL_ 426 CrksftTqMinRunImCapV 0 "Valid" 1 "Invalid";
VAL_ 1231 DslExhFluidLvlPrcntV 0 "Valid" 1 "Invalid";
VAL_ 963 CltTmpCntlMdEmRMAct 0 "false" 1 "true";
VAL_ 963 CTCMERDTC_SysDes 0 "P0-Powertrain Codes SAE Controlled" 1 "P1-Powertrain Codes MFG Controlled" 2 "P2-Powertrain Codes Reserved" 3 "P3-Powertrain Codes Reserved" 4 "C0-Chassis Codes SAE Controlled" 5 "C1-Chassis Codes MFG Controlled" 6 "C2-Chassis Codes Reserved" 7 "C3-Chassis Codes Reserved" 8 "B0-Body Codes SAE Controlled" 9 "B1-Body Codes MFG Controlled" 10 "B2-Body Codes Reserved" 11 "B3-Body Codes Reserved" 12 "U0-Network Codes SAE Controlled" 13 "U1-Network Codes MFG Controlled" 14 "U2- Network Codes Reserved" 15 "U3-Network Codes Reserved";
VAL_ 955 RHCS_RdctHtrCCurrV 0 "Valid" 1 "Invalid";
VAL_ 955 RHCS_RdctHtrBCurrV 0 "Valid" 1 "Invalid";
VAL_ 955 RHCS_RdctHtrACurrV 0 "Valid" 1 "Invalid";
VAL_ 563 SPMCA_SusPrfMd6Avl 0 "false" 1 "true";
VAL_ 563 SPMCA_SusPrfMd5Avl 0 "false" 1 "true";
VAL_ 563 SPMCA_SusPrfMd4Avl 0 "false" 1 "true";
VAL_ 563 SPMCA_SusPrfMd3Avl 0 "false" 1 "true";
VAL_ 563 SPMCA_SusPrfMd2Avl 0 "false" 1 "true";
VAL_ 563 SPMCA_SusPrfMd1Avl 0 "false" 1 "true";
VAL_ 563 SPMCA_StrPrfMd6Avl 0 "false" 1 "true";
VAL_ 563 SPMCA_StrPrfMd5Avl 0 "false" 1 "true";
VAL_ 563 SPMCA_StrPrfMd4Avl 0 "false" 1 "true";
VAL_ 563 SPMCA_StrPrfMd3Avl 0 "false" 1 "true";
VAL_ 563 SPMCA_StrPrfMd2Avl 0 "false" 1 "true";
VAL_ 563 SPMCA_StrPrfMd1Avl 0 "false" 1 "true";
VAL_ 563 SPMCA_SndPrfMd6Avl 0 "false" 1 "true";
VAL_ 563 SPMCA_SndPrfMd5Avl 0 "false" 1 "true";
VAL_ 563 SPMCA_SndPrfMd4Avl 0 "false" 1 "true";
VAL_ 563 SPMCA_SndPrfMd3Avl 0 "false" 1 "true";
VAL_ 563 SPMCA_SndPrfMd2Avl 0 "false" 1 "true";
VAL_ 563 SPMCA_SndPrfMd1Avl 0 "false" 1 "true";
VAL_ 563 DPMCA_DispPrfMd6Avl 0 "false" 1 "true";
VAL_ 563 DPMCA_DispPrfMd5Avl 0 "false" 1 "true";
VAL_ 563 DPMCA_DispPrfMd4Avl 0 "false" 1 "true";
VAL_ 563 DPMCA_DispPrfMd3Avl 0 "false" 1 "true";
VAL_ 563 DPMCA_DispPrfMd2Avl 0 "false" 1 "true";
VAL_ 563 DPMCA_DispPrfMd1Avl 0 "false" 1 "true";
VAL_ 563 DPMCA_DrvlPrfMd6Avl 0 "false" 1 "true";
VAL_ 563 DPMCA_DrvlPrfMd5Avl 0 "false" 1 "true";
VAL_ 563 DPMCA_DrvlPrfMd4Avl 0 "false" 1 "true";
VAL_ 563 DPMCA_DrvlPrfMd3Avl 0 "false" 1 "true";
VAL_ 563 DPMCA_DrvlPrfMd2Avl 0 "false" 1 "true";
VAL_ 563 DPMCA_DrvlPrfMd1Avl 0 "false" 1 "true";
VAL_ 1323 TireLRTmpV 0 "Valid" 1 "Invalid";
VAL_ 1323 TireLFTmpV 0 "Valid" 1 "Invalid";
VAL_ 1323 TireRRTmpV 0 "Valid" 1 "Invalid";
VAL_ 1323 TireRFTmpV 0 "Valid" 1 "Invalid";
VAL_ 1247 RrPTCoolFanStatV 0 "Valid" 1 "Invalid";
VAL_ 1247 RrPTCoolFanStat 0 "Off" 1 "On";
VAL_ 873 FrtCmModIntgStat 0 "Pass" 1 "Fail";
VAL_ 873 FrtCmModAsmt 0 "No Problem" 1 "Improper Response" 2 "Repeated Challenge";
VAL_ 723 PerfTrcEngSpdRqStat 0 "No Request" 1 "Request Honored" 2 "Lost Arbitration" 3 "Serial Data Failure Temporary" 4 "Serial Data Failure Permanent" 5 "Control System Failure Temporary" 6 "Control System Failure Permanent";
VAL_ 723 PerfTrcEngSpdLmtStat 0 "Not Limited" 1 "Rate Limited" 2 "Value Limited" 3 "Rate & Value Limited";
VAL_ 723 PerfTrcTrqRqStat 0 "No Request" 1 "Request Honored" 2 "Lost Arbitration" 3 "Serial Data Failure Temporary" 4 "Serial Data Failure Permanent" 5 "Control System Failure Temporary" 6 "Control System Failure Permanent";
VAL_ 723 PerfTrcTrqLmtStat 0 "Not Limited" 1 "Rate Limited" 2 "Value Limited" 3 "Rate & Value Limited";
VAL_ 405 EngDistFuelMdDefltd 0 "false" 1 "true";
VAL_ 405 EngInjEnbldD 0 "false" 1 "true";
VAL_ 405 EngInjEnbldC 0 "false" 1 "true";
VAL_ 405 EngInjEnbldB 0 "false" 1 "true";
VAL_ 405 EngInjEnbldA 0 "false" 1 "true";
VAL_ 405 ThrPosV 0 "Valid" 1 "Invalid";
VAL_ 405 MassAirFloV 0 "Valid" 1 "Invalid";
VAL_ 405 EngManfldAbsPrsERV 0 "Valid" 1 "Invalid";
VAL_ 419 EngRunng 0 "false" 1 "true";
VAL_ 289 ARDM_MsgType 0 "Reserved 1" 1 "Position" 2 "Segment" 3 "Stub" 4 "Profile Short" 5 "Profile Long" 6 "Meta Data" 7 "Reserved 2";
VAL_ 871 ACCModIntgStat 0 "Pass" 1 "Fail";
VAL_ 871 AdptCrsCtrlModAsmt 0 "No Problem" 1 "Improper Response" 2 "Repeated Challenge";
VAL_ 800 FCACBSC_AutBrkRpRt 0 "None" 1 "Light" 2 "Full" 3 "Reserved";
VAL_ 800 FCACBSC_AutBrkRqTp 0 "None" 1 "Prefill" 2 "Haptic Pulse" 3 "Brake Per Requested Decel" 4 "Apply Park Brake" 5 "Hold" 6 "Lower Panic Brake Threshold" 7 "Reserved" 8 "Object Detected/Confirmation";
VAL_ 800 FCACBSC_AutBrkRqd 0 "false" 1 "true";
VAL_ 388 HndsOffStrWhlDtStV 0 "Valid" 1 "Invalid";
VAL_ 388 HndsOffStrWhlDtSt 0 "Hands Off" 1 "Hands On";
VAL_ 388 HndsOffStrWhlDtMd 0 "Disabled" 1 "Enabled" 2 "Failed";
VAL_ 388 LKATrqOvrlTrqDStat 0 "Inactive" 1 "Active" 2 "Temporarily Limited" 3 "Permanently Failed";
VAL_ 384 LKATODC_TrqRqAct 0 "false" 1 "true";
VAL_ 866 ColPrSysHzrdLghtsReq 0 "No Action" 1 "Activate" 2 "Deactivate" 3 "Reserved";
VAL_ 866 ColPrSysWndwsReq 0 "No Action" 1 "Close" 2 "Open" 3 "Reserved";
VAL_ 866 ColPrSysDrsReq 0 "No Action" 1 "Lock All" 2 "Unlock All" 3 "Reserved";
VAL_ 866 ColPrSysSnrfReq 0 "No Action" 1 "Close" 2 "Open" 3 "Reserved";
VAL_ 866 CPSInfotmntMtReq 0 "No Mute" 1 "Unused and Reserved 1" 2 "Unused and Reserved 2" 3 "Mute";
VAL_ 866 StBltTgtSetAvl 0 "false" 1 "true";
VAL_ 866 StBltTgtCrtSetVal 0 "No Action" 1 "Low" 2 "Normal" 3 "Performance" 4 "Locked";
VAL_ 866 MotStBltUnblIO 0 "false" 1 "true";
VAL_ 866 MotStBltFldIO 0 "false" 1 "true";
VAL_ 951 FuelInjCntrlModInjFltAct 0 "false" 1 "true";
VAL_ 951 AFRP_SnsTyp 0 "Not Supported" 1 "Pressure Relative Manifold Vacuum" 2 "Absolute Pressure" 3 "Gauge Pressure";
VAL_ 951 FICMDS3_DTCStatus 0 "Not Supported" 1 "Critically Disabled" 2 "No Status to Report" 3 "Diagnostic Passed" 4 "Diagnostic Failed";
VAL_ 951 FICMDS2_DTCStatus 0 "Not Supported" 1 "Critically Disabled" 2 "No Status to Report" 3 "Diagnostic Passed" 4 "Diagnostic Failed";
VAL_ 951 FICMDS1_DTCStatus 0 "Not Supported" 1 "Critically Disabled" 2 "No Status to Report" 3 "Diagnostic Passed" 4 "Diagnostic Failed";
VAL_ 1223 EngSnPwrECoolLpTmpV 0 "Valid" 1 "Invalid";
VAL_ 1223 PropSysOffTmeV 0 "Valid" 1 "Invalid";
VAL_ 1223 PropSysOffTmeM 0 "Don't Use Data" 1 "Use Data";
VAL_ 1227 BattThrmlCondOffTmeV 0 "Valid" 1 "Invalid";
VAL_ 1227 BattThrmlCondOffTmeM 0 "Don't Use Data" 1 "Use Data";
VAL_ 1227 OffBrdChrgOffTmeV 0 "Valid" 1 "Invalid";
VAL_ 1227 OffBrdChrgOffTmeM 0 "Don't Use Data" 1 "Use Data";
VAL_ 543 PTOTpStpSpdCsStReq 0 "No Action" 1 "5 rpm" 2 "10 rpm" 3 "25 rpm" 4 "50 rpm" 5 "100 rpm" 6 "250 rpm" 7 "500 rpm";
VAL_ 543 PTOStdbySpdCsStReq 0 "No Action" 1 "900 rpm" 2 "1000 rpm" 3 "1100 rpm" 4 "1200 rpm" 5 "1300 rpm" 6 "1400 rpm" 7 "1500 rpm";
VAL_ 543 PTOEngRnTmrCsStRq 0 "No Action" 1 "10 min" 2 "30 min" 3 "90 min" 4 "120 min" 5 "150 min" 6 "180 min" 7 "210 min" 8 "240 min" 9 "270 min" 10 "300 min" 11 "330 min" 12 "360 min" 13 "390 min" 14 "420 min" 15 "450 min";
VAL_ 543 PTOSet2SpdCsStReq 0 "No Action" 1 "1900 rpm" 2 "2000 rpm" 3 "2100 rpm" 4 "2200 rpm" 5 "2300 rpm" 6 "2400 rpm" 7 "2500 rpm" 8 "2600 rpm" 9 "2700 rpm" 10 "2800 rpm" 11 "2900 rpm" 12 "3000 rpm" 13 "3100 rpm" 14 "3200 rpm" 15 "3300 rpm";
VAL_ 543 PTOSet1SpdCsStReq 0 "No Action" 1 "1100 rpm" 2 "1200 rpm" 3 "1300 rpm" 4 "1400 rpm" 5 "1500 rpm" 6 "1600 rpm" 7 "1700 rpm" 8 "1800 rpm" 9 "1900 rpm" 10 "2000 rpm" 11 "2100 rpm" 12 "2200 rpm" 13 "2300 rpm" 14 "2400 rpm" 15 "2500 rpm";
VAL_ 544 PTOAudExtAlertReq 0 "false" 1 "true";
VAL_ 544 PTOTransInGearIO 0 "false" 1 "true";
VAL_ 544 PTOTpStpSpdCsStAvl 0 "false" 1 "true";
VAL_ 544 PTOTpStSpdCsCrStVal 0 "No Action" 1 "5 rpm" 2 "10 rpm" 3 "25 rpm" 4 "50 rpm" 5 "100 rpm" 6 "250 rpm" 7 "500 rpm";
VAL_ 544 PTOStdbySpdCsStAvl 0 "false" 1 "true";
VAL_ 544 PTOStdbSpdCsCrStVal 0 "No Action" 1 "900 rpm" 2 "1000 rpm" 3 "1100 rpm" 4 "1200 rpm" 5 "1300 rpm" 6 "1400 rpm" 7 "1500 rpm";
VAL_ 544 PTOSetPrkBrkIO 0 "false" 1 "true";
VAL_ 544 PTOSet2SpdCsStAvl 0 "false" 1 "true";
VAL_ 544 PTOSet2SpdCsCrStVal 0 "No Action" 1 "1900 rpm" 2 "2000 rpm" 3 "2100 rpm" 4 "2200 rpm" 5 "2300 rpm" 6 "2400 rpm" 7 "2500 rpm" 8 "2600 rpm" 9 "2700 rpm" 10 "2800 rpm" 11 "2900 rpm" 12 "3000 rpm" 13 "3100 rpm" 14 "3200 rpm" 15 "3300 rpm";
VAL_ 544 PTOSet1SpdCsStAvl 0 "false" 1 "true";
VAL_ 544 PTOSet1SpdCsCrStVal 0 "No Action" 1 "1100 rpm" 2 "1200 rpm" 3 "1300 rpm" 4 "1400 rpm" 5 "1500 rpm" 6 "1600 rpm" 7 "1700 rpm" 8 "1800 rpm" 9 "1900 rpm" 10 "2000 rpm" 11 "2100 rpm" 12 "2200 rpm" 13 "2300 rpm" 14 "2400 rpm" 15 "2500 rpm";
VAL_ 544 PTORelCltPedIO 0 "false" 1 "true";
VAL_ 544 PTORelBrkPedIO 0 "false" 1 "true";
VAL_ 544 PTORelAccPedIO 0 "false" 1 "true";
VAL_ 544 PTORedEngSpdIO 0 "false" 1 "true";
VAL_ 544 PTOPrsRelCltPedIO 0 "false" 1 "true";
VAL_ 544 PTOPrsRelBrkPedIO 0 "false" 1 "true";
VAL_ 544 PTOEngRnTmrCsStAvl 0 "false" 1 "true";
VAL_ 544 PTOEnRnTmCsCrStVal 0 "No Action" 1 "10 min" 2 "30 min" 3 "90 min" 4 "120 min" 5 "150 min" 6 "180 min" 7 "210 min" 8 "240 min" 9 "270 min" 10 "300 min" 11 "330 min" 12 "360 min" 13 "390 min" 14 "420 min" 15 "450 min";
VAL_ 544 PTOEngmntStatInd 0 "No Indication" 1 "Continuous Indication" 2 "Slow Flashing Indication" 3 "Fast Flashing Indication";
VAL_ 544 PTODisengCrsCntlIO 0 "false" 1 "true";
VAL_ 1032 RdTyp 0 "Town" 1 "Country Road" 2 "Motorway" 3 "Unused and Reserved 1" 4 "Unused and Reserved 2" 5 "Unused and Reserved 3" 6 "Unused and Reserved 4" 7 "Undefined";
VAL_ 1032 FwdCamSysOpStat 0 "Unknown" 1 "Initializing" 2 "Inactive" 3 "Active" 4 "Unused and Reserved 1" 5 "Unused and Reserved 2" 6 "Unused and Reserved 3" 7 "Failed";
VAL_ 1032 EnvIllum 0 "Unknown" 1 "Lit Environment During Night" 2 "Unlit Environment During Night" 3 "Daylight";
VAL_ 1032 AutoHgBmSts 0 "Not Available" 1 "Inactive" 2 "Active";
VAL_ 1031 FCO8D_ObjTyp 0 "No Object" 1 "Headlamp" 2 "Rearlamp" 3 "Pair Headlamps" 4 "Pair Rearlamps";
VAL_ 1031 FCO8D_ObjQlty 0 "Less than 70%" 1 "70-85%" 2 "85-95%" 3 "95-100%";
VAL_ 1031 FCO8D_DetMthd 0 "Measured Object" 1 "Tracked Object" 2 "Initializing" 3 "Unavailable";
VAL_ 1030 FCO7D_ObjTyp 0 "No Object" 1 "Headlamp" 2 "Rearlamp" 3 "Pair Headlamps" 4 "Pair Rearlamps";
VAL_ 1030 FCO7D_ObjQlty 0 "Less than 70%" 1 "70-85%" 2 "85-95%" 3 "95-100%";
VAL_ 1030 FCO7D_DetMthd 0 "Measured Object" 1 "Tracked Object" 2 "Initializing" 3 "Unavailable";
VAL_ 479 ASIRI_Indication16 0 "false" 1 "true";
VAL_ 479 ASIRI_Indication15 0 "false" 1 "true";
VAL_ 479 ASIRI_Indication14 0 "false" 1 "true";
VAL_ 479 ASIRI_Indication13 0 "false" 1 "true";
VAL_ 479 ASIRI_Indication12 0 "false" 1 "true";
VAL_ 479 ASIRI_Indication11 0 "false" 1 "true";
VAL_ 479 ASIRI_Indication10 0 "false" 1 "true";
VAL_ 479 ASIRI_Indication09 0 "false" 1 "true";
VAL_ 479 ASIRI_Indication08 0 "false" 1 "true";
VAL_ 479 ASIRI_Indication07 0 "false" 1 "true";
VAL_ 479 ASIRI_Indication06 0 "false" 1 "true";
VAL_ 479 ASIRI_Indication05 0 "false" 1 "true";
VAL_ 479 ASIRI_Indication04 0 "false" 1 "true";
VAL_ 479 ASIRI_Indication03 0 "false" 1 "true";
VAL_ 479 ASIRI_Indication02 0 "false" 1 "true";
VAL_ 479 ASIRI_Indication01 0 "false" 1 "true";
VAL_ 479 PTWrmgWtToShftIO 0 "false" 1 "true";
VAL_ 479 PrplsnSysAtv 0 "false" 1 "true";
VAL_ 479 PTShftLvrLckRqd 0 "false" 1 "true";
VAL_ 211 ActAxleTrqV 0 "Valid" 1 "Invalid";
VAL_ 1020 OtsAirTmpEmsnsRelV 0 "Valid" 1 "Invalid";
VAL_ 1020 OATEmsnsRelCrValV 0 "Valid" 1 "Invalid";
VAL_ 1020 OATEmsnsRelCrValM 0 "Don't Use Data" 1 "Use Data";
VAL_ 1020 CatlystOutGasTempEstV 0 "Valid" 1 "Invalid";
VAL_ 1020 OtsAirTmpCrValMsk 0 "Don't Use Data" 1 "Use Data";
VAL_ 1020 OtsAirTmpV 0 "Valid" 1 "Invalid";
VAL_ 1020 OtsAirTmpCrValV 0 "Valid" 1 "Invalid";
VAL_ 1020 EngInltSpcfcHmdtyV 0 "Valid" 1 "Invalid";
VAL_ 1020 EngInltSpcfcHmdtyM 0 "Don't Use Data" 1 "Use Data";
CM_ "Primary High Speed GMLAN";
CM_ BU_ PFAF_HS "Pedestrian Friendly Alert Function";
CM_ BU_ LVMPC_HS "Low Volume Module (Performance Computer )";
CM_ BU_ DCDC_HS "DC/DC Converter";
CM_ BU_ AMP_HS "Audio Amplifier";
CM_ BU_ VICM2_HS "Vehicle Integration Control Module 2 (CTCM - Coolant Temperature Control Module)";
CM_ BU_ FICM_HS "Fuel Injection Control Module";
CM_ BU_ ARS_HS "Active Rear Steering";
CM_ BU_ MCP_B_HS "Motor Control Processor B(part of TPIM-Traction Powertrain Inverter Module)";
CM_ BU_ MCP_A_HS "Motor Control Processor A(part of TPIM-Traction Powertrain Inverter Module)";
CM_ BU_ ICCM_OBD_HS "Integrated Chassis Control Module";
CM_ BU_ SAS_HS "Steering Angle Sensor";
CM_ BU_ ACCM_HS "Air Conditioning Control Module";
CM_ BU_ VLBS_HS "Vehicle Location & Blocking System";
CM_ BU_ EBCM_OBD_HS "Electronic Brake Control Module";
CM_ BU_ EDI_HS "Enhanced Driver Interface";
CM_ BU_ HPCC_HS "High Power Charging Contactor";
CM_ BU_ VITM_OBD_HS "Voltage, Current, Temperature Module BAS+";
CM_ BU_ PTAM_HS "Perfomance Traction Algorithm Module";
CM_ BU_ OBCM_HS "On Board Charger Module";
CM_ BU_ VICM_HS "Vehicle Integration Control Module 4Mode";
CM_ BU_ HCP_HS "Hybrid Control Processor";
CM_ BU_ FDCM_HS "Front Drive Control Module";
CM_ BU_ APPS_HS "Active Pedestrian Protection System";
CM_ BU_ ICCM_HS "Integrated Chassis Control Module";
CM_ BU_ EOCM_F_HS "External Object Control Module - Front";
CM_ BU_ GPCM_HS "Glow Plug Control Module";
CM_ BU_ FSCM_ITBC_HS "Fuel System Control Module";
CM_ BU_ SCM_HS "Supervisory Control";
CM_ BU_ ITBC_HS "Integrated Trail Brake Control";
CM_ BU_ VCM_HS "Vaporizer Control Module";
CM_ BU_ HMIM_HS "Next-Gen Infotainment HMIModule ";
CM_ BU_ FCP_HS "Flexible Compute Platform";
CM_ BU_ VES_HS "Variable Effort Steering";
CM_ BU_ Dummy_HS "This is for avoid signle ended signalling";
CM_ BU_ MCP_C_HS "Motor control processor C";
CM_ BU_ RWS_HS "Rear Wheel Steer";
CM_ BU_ ONSTAR_HS "OnStar Module";
CM_ BU_ EPS_HS "Electronic Power Steering";
CM_ BU_ MCP_HS "Motor Control Processor";
CM_ BU_ BCP_HS "BAS+";
CM_ BU_ ALC_HS "Automatic Level Control";
CM_ BU_ AHL_AFL_HS "Automatic Headlamp Levelling";
CM_ BU_ SADS_HS "Semi Active Damping System";
CM_ BU_ EPB_HS "Electronic Park Brake";
CM_ BU_ FSCM_HS "Fuel System Control Module";
CM_ BU_ AFS_HS "Active Front Steering";
CM_ BU_ FCM_HS "Front Camera Module";
CM_ BU_ TCCM_HS "Transfer Case Control Module";
CM_ BU_ RDCM_HS "Rear Drive Control Module";
CM_ BU_ PTO_HS "Power TakeOff Module";
CM_ BU_ PCM_HS "Engine Control Module";
CM_ BU_ EBCM_HS "Electronic Brake Control Module";
CM_ BU_ ACC_HS "Adaptive Cruise Control";
CM_ BU_ BCM_HS "HS Side Global Architecture Gateway and Body Control Module";
CM_ BU_ TCM_HS "Transmission Control Module";
CM_ BU_ ECM_HS "Engine Control Module";
CM_ SG_ 949 AltFuelEqvlntRatBsOffst "Units = Equivalence Ratio";
BA_DEF_  "BusType" STRING;
BA_DEF_ SG_ "VNSigSLHS_VNReq" ENUM "No","Yes";
BA_DEF_ SG_ "VNSigSLHSSharedDiagnostic" ENUM "No","Yes";
BA_DEF_ SG_ "SignalType" STRING;
BA_DEF_ SG_ "PacketOrder" INT 0 65535;
BA_DEF_ SG_ "SignalLongName" STRING;
BA_DEF_ SG_ "GenSigStartValue" INT 0 65535;
BA_DEF_ SG_ "VNSigAllNodes" ENUM "No","Yes";
BA_DEF_ SG_ "GenSigDeltaValue" INT 0 0;
BA_DEF_ SG_ "GenSigSendType" ENUM "not used","not used","not used","not used","not used","not used","not used","NoSigSendType","not used","not used","OnAnyChange","OnChangeIfActive","OnDelta";
BA_DEF_ SG_ "GenSigSendOnInit" ENUM "Not Initialized","Application","Handler";
BA_DEF_ BO_ "AppGenMsgCycleTime" INT 0 0;
BA_DEF_ BO_ "GenMsgILSupport" ENUM "No","Yes";
BA_DEF_ BO_ "TpApplType" STRING;
BA_DEF_ BO_ "Prio" INT 0 7;
BA_DEF_ BO_ "MessageSubnet" ENUM "LS","MS","HS","CE","PE","HV","FO";
BA_DEF_ BO_ "DiagState" ENUM "No","Yes";
BA_DEF_ BO_ "GenMsgDelayTime" INT 0 100000;
BA_DEF_ BO_ "GenMsgCycleTime" INT 0 100000;
BA_DEF_ BO_ "GenMsgSendType" ENUM "cyclicX","spontanX","cyclicIfActiveX","spontanWithDelay","cyclicAndSpontanX","cyclicAndSpontanWithDelay","spontanWithRepitition","cyclicIfActiveAndSpontanWD";
BA_DEF_ BO_ "DiagResponse" ENUM "No","Yes";
BA_DEF_ BO_ "DiagRequest" ENUM "No","Yes";
BA_DEF_ BO_ "NmMessage" ENUM "No","Yes";
BA_DEF_ BU_ "MessageManagerUsed" ENUM "No","Yes";
BA_DEF_ BU_ "NmNode" ENUM "No","Yes";
BA_DEF_ BU_ "ILUsed" ENUM "No","Yes";
BA_DEF_ BU_ "NodeLayerModules" STRING;
BA_DEF_ BU_ "VNECUSLHS_VNReq" ENUM "None","Activator","Remoted","Activator and Remoted","Shared Local";
BA_DEF_ BU_ "VNECUSLHSSharedDiagnostic" ENUM "None","Activator","Remoted","Activator and Remoted","Shared Local";
BA_DEF_ BU_ "D22_FRdDataByPID" ENUM "No","Yes";
BA_DEF_ BU_ "D22_N12" ENUM "No","Yes";
BA_DEF_ BU_ "D22_ReqType" ENUM "Functional","Physical","Both";
BA_DEF_ BU_ "D2D_ReqType" ENUM "Functional","Physical","Both";
BA_DEF_ BU_ "DAE_ReqType" ENUM "Functional","Physical","Both";
BA_DEF_ BU_ "DAE_NE3" ENUM "No","Yes";
BA_DEF_ BU_ "DAE_N78" ENUM "No","Yes";
BA_DEF_ BU_ "DAE_N31" ENUM "No","Yes";
BA_DEF_ BU_ "DAE_N12" ENUM "No","Yes";
BA_DEF_ BU_ "DAE_FDevCtrl" ENUM "No","Yes","vector_leerstring";
BA_DEF_ BU_ "DAA_ReqType" ENUM "Functional","Physical","Both";
BA_DEF_ BU_ "DAA_N81" ENUM "No","Yes";
BA_DEF_ BU_ "DAA_N78" ENUM "No","Yes";
BA_DEF_ BU_ "DAA_N31" ENUM "No","Yes";
BA_DEF_ BU_ "DAA_N12" ENUM "No","Yes";
BA_DEF_ BU_ "DAA_L04_FastRate" ENUM "No","Yes";
BA_DEF_ BU_ "DAA_L03_MedRate" ENUM "No","Yes";
BA_DEF_ BU_ "DAA_L02_SlowRate" ENUM "No","Yes";
BA_DEF_ BU_ "DAA_L01_SndOneRsp" ENUM "No","Yes";
BA_DEF_ BU_ "DAA_L00_StopSnd" ENUM "No","Yes";
BA_DEF_ BU_ "DAA_FRdDPID" ENUM "No","Yes","vector_leerstring";
BA_DEF_ BU_ "DA9_ReqType" ENUM "Functional","Physical","Both";
BA_DEF_ BU_ "DA9_N78" ENUM "No","Yes";
BA_DEF_ BU_ "DA9_N31" ENUM "No","Yes";
BA_DEF_ BU_ "DA9_N12" ENUM "No","Yes";
BA_DEF_ BU_ "DA9_L82_SndChgDTC" ENUM "No","Yes";
BA_DEF_ BU_ "DA9_L81_RdStatDTCbyMsk" ENUM "No","Yes";
BA_DEF_ BU_ "DA9_L80_RdStatDTCbyNum" ENUM "No","Yes";
BA_DEF_ BU_ "DA9_FRdDiagInfo" ENUM "No","Yes","vector_leerstring";
BA_DEF_ BU_ "DA5_ReqType" ENUM "Functional","Physical","Both";
BA_DEF_ BU_ "DA5_N78" ENUM "No","Yes";
BA_DEF_ BU_ "DA5_N22" ENUM "No","Yes";
BA_DEF_ BU_ "DA5_N12" ENUM "No","Yes";
BA_DEF_ BU_ "DA5_L03_EnabProgMode" ENUM "No","Yes";
BA_DEF_ BU_ "DA5_L01_ReqProgMode" ENUM "No","Yes";
BA_DEF_ BU_ "DA5_FProgMode" ENUM "No","Yes","vector_leerstring";
BA_DEF_ BU_ "DA2_ReqType" ENUM "Functional","Physical","Both";
BA_DEF_ BU_ "DA2_N78" ENUM "No","Yes";
BA_DEF_ BU_ "DA2_N12" ENUM "No","Yes";
BA_DEF_ BU_ "DA2_FRptPrgStat" ENUM "No","Yes","vector_leerstring";
BA_DEF_ BU_ "D3E_ReqType" ENUM "Functional","Physical","Both";
BA_DEF_ BU_ "D3E_N12" ENUM "No","Yes";
BA_DEF_ BU_ "D3E_FTstrPres" ENUM "No","Yes","vector_leerstring";
BA_DEF_ BU_ "D3B_ReqType" ENUM "Functional","Physical","Both";
BA_DEF_ BU_ "D3B_N78" ENUM "No","Yes";
BA_DEF_ BU_ "D3B_N31" ENUM "No","Yes";
BA_DEF_ BU_ "D3B_N22" ENUM "No","Yes";
BA_DEF_ BU_ "D3B_N12" ENUM "No","Yes";
BA_DEF_ BU_ "D3B_FWrtBlk" ENUM "No","Yes","vector_leerstring";
BA_DEF_ BU_ "D36_ReqType" ENUM "Functional","Physical","Both";
BA_DEF_ BU_ "D36_N89" ENUM "No","Yes";
BA_DEF_ BU_ "D36_N85" ENUM "No","Yes";
BA_DEF_ BU_ "D36_N83" ENUM "No","Yes";
BA_DEF_ BU_ "D36_N78" ENUM "No","Yes";
BA_DEF_ BU_ "D36_N31" ENUM "No","Yes";
BA_DEF_ BU_ "D36_N22" ENUM "No","Yes";
BA_DEF_ BU_ "D36_N12" ENUM "No","Yes";
BA_DEF_ BU_ "D36_L80_DwnldExec" ENUM "No","Yes";
BA_DEF_ BU_ "D36_L00_DownLoad" ENUM "No","Yes";
BA_DEF_ BU_ "D36_FXfrData" ENUM "No","Yes","vector_leerstring";
BA_DEF_ BU_ "D34_ReqType" ENUM "Functional","Physical","Both";
BA_DEF_ BU_ "D34_N99" ENUM "No","Yes";
BA_DEF_ BU_ "D34_N78" ENUM "No","Yes";
BA_DEF_ BU_ "D34_N22" ENUM "No","Yes";
BA_DEF_ BU_ "D34_N12" ENUM "No","Yes";
BA_DEF_ BU_ "D34_FReqDwnld" ENUM "No","Yes";
BA_DEF_ BU_ "D2C_ReqType" ENUM "Functional","Physical","Both";
BA_DEF_ BU_ "D2C_N78" ENUM "No","Yes";
BA_DEF_ BU_ "D2C_N31" ENUM "No","Yes";
BA_DEF_ BU_ "D2C_N12" ENUM "No","Yes";
BA_DEF_ BU_ "D2C_FDynMsg" ENUM "No","Yes","vector_leerstring";
BA_DEF_ BU_ "D28_ReqType" ENUM "Functional","Physical","Both";
BA_DEF_ BU_ "D28_N22" ENUM "No","Yes";
BA_DEF_ BU_ "D28_N12" ENUM "No","Yes";
BA_DEF_ BU_ "D28_FDisNormComm" ENUM "No","Yes","vector_leerstring";
BA_DEF_ BU_ "D27_ReqType" ENUM "Functional","Physical","Both";
BA_DEF_ BU_ "D27_N78" ENUM "No","Yes";
BA_DEF_ BU_ "D27_N37" ENUM "No","Yes";
BA_DEF_ BU_ "D27_N36" ENUM "No","Yes";
BA_DEF_ BU_ "D27_N35" ENUM "No","Yes";
BA_DEF_ BU_ "D27_N22" ENUM "No","Yes";
BA_DEF_ BU_ "D27_N12" ENUM "No","Yes";
BA_DEF_ BU_ "D27_L04_DevCtrlSeedKey" ENUM "No","Yes";
BA_DEF_ BU_ "D27_L03_CtrlReqSeed" ENUM "No","Yes";
BA_DEF_ BU_ "D27_L02_SndKey" ENUM "No","Yes";
BA_DEF_ BU_ "D27_L01_ReqSeed" ENUM "No","Yes";
BA_DEF_ BU_ "D27_FSecAcc" ENUM "No","Yes","vector_leerstring";
BA_DEF_ BU_ "D23_ReqType" ENUM "Functional","Physical","Both";
BA_DEF_ BU_ "D23_N78" ENUM "No","Yes";
BA_DEF_ BU_ "D23_N31" ENUM "No","Yes";
BA_DEF_ BU_ "D23_N12" ENUM "No","Yes";
BA_DEF_ BU_ "D23_FRdMemAddr" ENUM "No","Yes","vector_leerstring";
BA_DEF_ BU_ "D20_ReqType" ENUM "Functional","Physical","Both";
BA_DEF_ BU_ "D20_N12" ENUM "No","Yes";
BA_DEF_ BU_ "D20_FRtnNormComm" ENUM "No","Yes","vector_leerstring";
BA_DEF_ BU_ "D1A_ReqType" ENUM "Functional","Physical","Both";
BA_DEF_ BU_ "D1A_N78" ENUM "No","Yes";
BA_DEF_ BU_ "D1A_N31" ENUM "No","Yes";
BA_DEF_ BU_ "D1A_N22" ENUM "No","Yes";
BA_DEF_ BU_ "D1A_N12" ENUM "No","Yes";
BA_DEF_ BU_ "D1A_FRdDataID" ENUM "No","Yes","vector_leerstring";
BA_DEF_ BU_ "D12_ReqType" ENUM "Functional","Physical","Both";
BA_DEF_ BU_ "D12_N78" ENUM "No","Yes";
BA_DEF_ BU_ "D12_N31" ENUM "No","Yes";
BA_DEF_ BU_ "D12_N12" ENUM "No","Yes";
BA_DEF_ BU_ "D12_L02_RdFRcdParam" ENUM "No","Yes";
BA_DEF_ BU_ "D12_L01_RdFRcdData" ENUM "No","Yes";
BA_DEF_ BU_ "D12_FRdFailRec" ENUM "No","Yes","vector_leerstring";
BA_DEF_ BU_ "D10_ReqType" ENUM "Functional","Physical ","Both";
BA_DEF_ BU_ "D10_N78" ENUM "No","Yes","vector_leerstring";
BA_DEF_ BU_ "D10_N22" ENUM "No","Yes","vector_leerstring";
BA_DEF_ BU_ "D10_N12" ENUM "No","Yes","vector_leerstring";
BA_DEF_ BU_ "D10_L04_WakeUpLinks" ENUM "No","Yes","vector_leerstring";
BA_DEF_ BU_ "D10_L03_DTCsDurDevCtrl" ENUM "No","Yes","vector_leerstring";
BA_DEF_ BU_ "D10_L02_DisAllDTCs" ENUM "No","Yes","vector_leerstring";
BA_DEF_ BU_ "D10_FInitDiagOp" ENUM "No","Yes","vector_leerstring";
BA_DEF_ BU_ "D04_ReqType" ENUM "Functional","Physical","Both","vector_leerstring";
BA_DEF_ BU_ "D04_N78" ENUM "No","Yes","vector_leerstring";
BA_DEF_ BU_ "D04_N22" ENUM "No","Yes","vector_leerstring";
BA_DEF_ BU_ "D04_N12" ENUM "No","Yes","vector_leerstring";
BA_DEF_ BU_ "D04_FClrDTC" ENUM "No","Yes","vector_leerstring";
BA_DEF_ BU_ "VNECUAllNodes" ENUM "None","Activator","Remoted","Activator and Remoted","Shared Local";
BA_DEF_ BU_ "ECU_Id" HEX 0 255;
BA_DEF_ BU_ "SourceId" HEX 0 253;
BA_DEF_  "SyncJumpWidthMax" INT 0 255;
BA_DEF_  "SyncJumpWidthMin" INT 0 255;
BA_DEF_  "SamplePointMax" FLOAT 0.00000000 100.00000000;
BA_DEF_  "SamplePointMin" FLOAT 0.00000000 100.00000000;
BA_DEF_  "Baudrate" INT 0 1000000;
BA_DEF_  "VehicleArchitecture" STRING;
BA_DEF_  "VNInitActSLHS_VNReq" ENUM "No","Yes";
BA_DEF_  "VN_SLHS_VNReq" INT 0 255;
BA_DEF_  "VNInitActSLHSSharedDiagnostic" ENUM "No","Yes";
BA_DEF_  "VN_SLHSSharedDiagnostic" INT 0 255;
BA_DEF_  "NmMessageCount" INT 0 32;
BA_DEF_  "NmBaseAddress" HEX 0 2032;
BA_DEF_  "NetworkType" STRING;
BA_DEF_  "VNMFPeriodicInterval" INT 0 65535;
BA_DEF_  "BusWakeUpDelay" INT 0 65535;
BA_DEF_  "BusOffRecoveryTime" INT 0 65535;
BA_DEF_  "NodeStatusMsgID" HEX 0 536870911;
BA_DEF_  "NodeStatusMsgCycleTime" INT 0 65535;
BA_DEF_  "NodeStatusMsgTimeoutTime" INT 0 65535;
BA_DEF_  "UseGMParameterIDs" INT 0 1;
BA_DEF_  "VersionWeek" INT 0 255;
BA_DEF_  "VersionYear" INT 0 255;
BA_DEF_  "VN_AllNodes" INT 0 255;
BA_DEF_  "Manufacturer" ENUM "DBAG","VAG","BMW","PAG","GM";
BA_DEF_  "NmType" STRING;
BA_DEF_DEF_ "BusType" "";
BA_DEF_DEF_ "VNSigSLHS_VNReq" "No";
BA_DEF_DEF_ "VNSigSLHSSharedDiagnostic" "No";
BA_DEF_DEF_ "SignalType" "";
BA_DEF_DEF_ "PacketOrder" 0;
BA_DEF_DEF_ "SignalLongName" "";
BA_DEF_DEF_ "GenSigStartValue" 0;
BA_DEF_DEF_ "VNSigAllNodes" "No";
BA_DEF_DEF_ "GenSigDeltaValue" 0;
BA_DEF_DEF_ "GenSigSendType" "NoSigSendType";
BA_DEF_DEF_ "GenSigSendOnInit" "Not Initialized";
BA_DEF_DEF_ "AppGenMsgCycleTime" 0;
BA_DEF_DEF_ "GenMsgILSupport" "Yes";
BA_DEF_DEF_ "TpApplType" "";
BA_DEF_DEF_ "Prio" 4;
BA_DEF_DEF_ "MessageSubnet" "FO";
BA_DEF_DEF_ "DiagState" "No";
BA_DEF_DEF_ "GenMsgDelayTime" 0;
BA_DEF_DEF_ "GenMsgCycleTime" 0;
BA_DEF_DEF_ "GenMsgSendType" "spontanX";
BA_DEF_DEF_ "DiagResponse" "No";
BA_DEF_DEF_ "DiagRequest" "No";
BA_DEF_DEF_ "NmMessage" "No";
BA_DEF_DEF_ "MessageManagerUsed" "Yes";
BA_DEF_DEF_ "NmNode" "Yes";
BA_DEF_DEF_ "ILUsed" "Yes";
BA_DEF_DEF_ "NodeLayerModules" "gmlan02.dll";
BA_DEF_DEF_ "VNECUSLHS_VNReq" "None";
BA_DEF_DEF_ "VNECUSLHSSharedDiagnostic" "None";
BA_DEF_DEF_ "D22_FRdDataByPID" "No";
BA_DEF_DEF_ "D22_N12" "No";
BA_DEF_DEF_ "D22_ReqType" "Both";
BA_DEF_DEF_ "D2D_ReqType" "Both";
BA_DEF_DEF_ "DAE_ReqType" "Both";
BA_DEF_DEF_ "DAE_NE3" "No";
BA_DEF_DEF_ "DAE_N78" "No";
BA_DEF_DEF_ "DAE_N31" "No";
BA_DEF_DEF_ "DAE_N12" "No";
BA_DEF_DEF_ "DAE_FDevCtrl" "No";
BA_DEF_DEF_ "DAA_ReqType" "Both";
BA_DEF_DEF_ "DAA_N81" "No";
BA_DEF_DEF_ "DAA_N78" "No";
BA_DEF_DEF_ "DAA_N31" "No";
BA_DEF_DEF_ "DAA_N12" "No";
BA_DEF_DEF_ "DAA_L04_FastRate" "No";
BA_DEF_DEF_ "DAA_L03_MedRate" "No";
BA_DEF_DEF_ "DAA_L02_SlowRate" "No";
BA_DEF_DEF_ "DAA_L01_SndOneRsp" "No";
BA_DEF_DEF_ "DAA_L00_StopSnd" "No";
BA_DEF_DEF_ "DAA_FRdDPID" "No";
BA_DEF_DEF_ "DA9_ReqType" "Both";
BA_DEF_DEF_ "DA9_N78" "No";
BA_DEF_DEF_ "DA9_N31" "No";
BA_DEF_DEF_ "DA9_N12" "No";
BA_DEF_DEF_ "DA9_L82_SndChgDTC" "No";
BA_DEF_DEF_ "DA9_L81_RdStatDTCbyMsk" "No";
BA_DEF_DEF_ "DA9_L80_RdStatDTCbyNum" "No";
BA_DEF_DEF_ "DA9_FRdDiagInfo" "Yes";
BA_DEF_DEF_ "DA5_ReqType" "Both";
BA_DEF_DEF_ "DA5_N78" "No";
BA_DEF_DEF_ "DA5_N22" "No";
BA_DEF_DEF_ "DA5_N12" "No";
BA_DEF_DEF_ "DA5_L03_EnabProgMode" "No";
BA_DEF_DEF_ "DA5_L01_ReqProgMode" "No";
BA_DEF_DEF_ "DA5_FProgMode" "Yes";
BA_DEF_DEF_ "DA2_ReqType" "Both";
BA_DEF_DEF_ "DA2_N78" "No";
BA_DEF_DEF_ "DA2_N12" "No";
BA_DEF_DEF_ "DA2_FRptPrgStat" "Yes";
BA_DEF_DEF_ "D3E_ReqType" "Both";
BA_DEF_DEF_ "D3E_N12" "No";
BA_DEF_DEF_ "D3E_FTstrPres" "Yes";
BA_DEF_DEF_ "D3B_ReqType" "Both";
BA_DEF_DEF_ "D3B_N78" "No";
BA_DEF_DEF_ "D3B_N31" "No";
BA_DEF_DEF_ "D3B_N22" "No";
BA_DEF_DEF_ "D3B_N12" "No";
BA_DEF_DEF_ "D3B_FWrtBlk" "No";
BA_DEF_DEF_ "D36_ReqType" "Both";
BA_DEF_DEF_ "D36_N89" "No";
BA_DEF_DEF_ "D36_N85" "No";
BA_DEF_DEF_ "D36_N83" "No";
BA_DEF_DEF_ "D36_N78" "No";
BA_DEF_DEF_ "D36_N31" "No";
BA_DEF_DEF_ "D36_N22" "No";
BA_DEF_DEF_ "D36_N12" "No";
BA_DEF_DEF_ "D36_L80_DwnldExec" "No";
BA_DEF_DEF_ "D36_L00_DownLoad" "No";
BA_DEF_DEF_ "D36_FXfrData" "Yes";
BA_DEF_DEF_ "D34_ReqType" "Both";
BA_DEF_DEF_ "D34_N99" "No";
BA_DEF_DEF_ "D34_N78" "No";
BA_DEF_DEF_ "D34_N22" "No";
BA_DEF_DEF_ "D34_N12" "No";
BA_DEF_DEF_ "D34_FReqDwnld" "Yes";
BA_DEF_DEF_ "D2C_ReqType" "Both";
BA_DEF_DEF_ "D2C_N78" "No";
BA_DEF_DEF_ "D2C_N31" "No";
BA_DEF_DEF_ "D2C_N12" "No";
BA_DEF_DEF_ "D2C_FDynMsg" "No";
BA_DEF_DEF_ "D28_ReqType" "Both";
BA_DEF_DEF_ "D28_N22" "No";
BA_DEF_DEF_ "D28_N12" "No";
BA_DEF_DEF_ "D28_FDisNormComm" "Yes";
BA_DEF_DEF_ "D27_ReqType" "Both";
BA_DEF_DEF_ "D27_N78" "No";
BA_DEF_DEF_ "D27_N37" "No";
BA_DEF_DEF_ "D27_N36" "No";
BA_DEF_DEF_ "D27_N35" "No";
BA_DEF_DEF_ "D27_N22" "No";
BA_DEF_DEF_ "D27_N12" "No";
BA_DEF_DEF_ "D27_L04_DevCtrlSeedKey" "No";
BA_DEF_DEF_ "D27_L03_CtrlReqSeed" "No";
BA_DEF_DEF_ "D27_L02_SndKey" "No";
BA_DEF_DEF_ "D27_L01_ReqSeed" "No";
BA_DEF_DEF_ "D27_FSecAcc" "No";
BA_DEF_DEF_ "D23_ReqType" "Both";
BA_DEF_DEF_ "D23_N78" "No";
BA_DEF_DEF_ "D23_N31" "No";
BA_DEF_DEF_ "D23_N12" "No";
BA_DEF_DEF_ "D23_FRdMemAddr" "No";
BA_DEF_DEF_ "D20_ReqType" "Both";
BA_DEF_DEF_ "D20_N12" "No";
BA_DEF_DEF_ "D20_FRtnNormComm" "Yes";
BA_DEF_DEF_ "D1A_ReqType" "Both";
BA_DEF_DEF_ "D1A_N78" "No";
BA_DEF_DEF_ "D1A_N31" "No";
BA_DEF_DEF_ "D1A_N22" "No";
BA_DEF_DEF_ "D1A_N12" "No";
BA_DEF_DEF_ "D1A_FRdDataID" "Yes";
BA_DEF_DEF_ "D12_ReqType" "Both";
BA_DEF_DEF_ "D12_N78" "No";
BA_DEF_DEF_ "D12_N31" "No";
BA_DEF_DEF_ "D12_N12" "No";
BA_DEF_DEF_ "D12_L02_RdFRcdParam" "No";
BA_DEF_DEF_ "D12_L01_RdFRcdData" "No";
BA_DEF_DEF_ "D12_FRdFailRec" "No";
BA_DEF_DEF_ "D10_ReqType" "Both";
BA_DEF_DEF_ "D10_N78" "No";
BA_DEF_DEF_ "D10_N22" "No";
BA_DEF_DEF_ "D10_N12" "No";
BA_DEF_DEF_ "D10_L04_WakeUpLinks" "No";
BA_DEF_DEF_ "D10_L03_DTCsDurDevCtrl" "No";
BA_DEF_DEF_ "D10_L02_DisAllDTCs" "No";
BA_DEF_DEF_ "D10_FInitDiagOp" "Yes";
BA_DEF_DEF_ "D04_ReqType" "Both";
BA_DEF_DEF_ "D04_N78" "No";
BA_DEF_DEF_ "D04_N22" "No";
BA_DEF_DEF_ "D04_N12" "No";
BA_DEF_DEF_ "D04_FClrDTC" "Yes";
BA_DEF_DEF_ "VNECUAllNodes" "None";
BA_DEF_DEF_ "ECU_Id" 0;
BA_DEF_DEF_ "SourceId" 0;
BA_DEF_DEF_ "SyncJumpWidthMax" 0;
BA_DEF_DEF_ "SyncJumpWidthMin" 0;
BA_DEF_DEF_ "SamplePointMax" 0.00000000;
BA_DEF_DEF_ "SamplePointMin" 0.00000000;
BA_DEF_DEF_ "Baudrate" 0;
BA_DEF_DEF_ "VehicleArchitecture" "";
BA_DEF_DEF_ "VNInitActSLHS_VNReq" "No";
BA_DEF_DEF_ "VN_SLHS_VNReq" 2;
BA_DEF_DEF_ "VNInitActSLHSSharedDiagnostic" "No";
BA_DEF_DEF_ "VN_SLHSSharedDiagnostic" 0;
BA_DEF_DEF_ "NmMessageCount" 32;
BA_DEF_DEF_ "NmBaseAddress" 1568;
BA_DEF_DEF_ "NetworkType" "";
BA_DEF_DEF_ "VNMFPeriodicInterval" 3000;
BA_DEF_DEF_ "BusWakeUpDelay" 100;
BA_DEF_DEF_ "BusOffRecoveryTime" 0;
BA_DEF_DEF_ "NodeStatusMsgID" 268427264;
BA_DEF_DEF_ "NodeStatusMsgCycleTime" 1200;
BA_DEF_DEF_ "NodeStatusMsgTimeoutTime" 0;
BA_DEF_DEF_ "UseGMParameterIDs" 1;
BA_DEF_DEF_ "VersionWeek" 0;
BA_DEF_DEF_ "VersionYear" 0;
BA_DEF_DEF_ "VN_AllNodes" 1;
BA_DEF_DEF_ "Manufacturer" "GM";
BA_DEF_DEF_ "NmType" "GMLAN";
BA_ "NmMessageCount" 16;
BA_ "NetworkType" "Powertrain";
BA_ "VNInitActSLHSSharedDiagnostic" 1;
BA_ "BusWakeUpDelay" 70;
BA_ "NmBaseAddress" 1536;
BA_ "VehicleArchitecture" "Global A";
BA_ "UseGMParameterIDs" 0;
BA_ "VersionWeek" 49;
BA_ "BusType" "CAN";
BA_ "Baudrate" 500000;
BA_ "BusOffRecoveryTime" 160;
BA_ "SamplePointMin" 80.00000000;
BA_ "VersionYear" 6;
BA_ "SamplePointMax" 81.25000000;
BA_ "VNInitActSLHS_VNReq" 1;
BA_ "SyncJumpWidthMax" 4;
BA_ "SyncJumpWidthMin" 3;
BA_ "NodeStatusMsgID" 0;
BA_ "VNECUSLHSSharedDiagnostic" BU_ PFAF_HS 4;
BA_ "VNECUAllNodes" BU_ PFAF_HS 4;
BA_ "ECU_Id" BU_ PFAF_HS 12;
BA_ "VNECUSLHS_VNReq" BU_ PFAF_HS 4;
BA_ "SourceId" BU_ PFAF_HS 87;
BA_ "VNECUSLHSSharedDiagnostic" BU_ LVMPC_HS 4;
BA_ "VNECUAllNodes" BU_ LVMPC_HS 4;
BA_ "VNECUSLHS_VNReq" BU_ LVMPC_HS 4;
BA_ "VNECUSLHSSharedDiagnostic" BU_ DCDC_HS 4;
BA_ "VNECUAllNodes" BU_ DCDC_HS 4;
BA_ "ECU_Id" BU_ DCDC_HS 4;
BA_ "VNECUSLHS_VNReq" BU_ DCDC_HS 4;
BA_ "SourceId" BU_ DCDC_HS 204;
BA_ "VNECUSLHSSharedDiagnostic" BU_ AMP_HS 4;
BA_ "VNECUAllNodes" BU_ AMP_HS 4;
BA_ "ECU_Id" BU_ AMP_HS 19;
BA_ "VNECUSLHS_VNReq" BU_ AMP_HS 4;
BA_ "SourceId" BU_ AMP_HS 129;
BA_ "VNECUSLHSSharedDiagnostic" BU_ VICM2_HS 4;
BA_ "VNECUAllNodes" BU_ VICM2_HS 4;
BA_ "ECU_Id" BU_ VICM2_HS 230;
BA_ "VNECUSLHS_VNReq" BU_ VICM2_HS 4;
BA_ "SourceId" BU_ VICM2_HS 206;
BA_ "VNECUSLHSSharedDiagnostic" BU_ FICM_HS 4;
BA_ "VNECUAllNodes" BU_ FICM_HS 4;
BA_ "ECU_Id" BU_ FICM_HS 230;
BA_ "VNECUSLHS_VNReq" BU_ FICM_HS 4;
BA_ "SourceId" BU_ FICM_HS 19;
BA_ "VNECUSLHSSharedDiagnostic" BU_ ARS_HS 4;
BA_ "VNECUAllNodes" BU_ ARS_HS 4;
BA_ "ECU_Id" BU_ ARS_HS 29;
BA_ "VNECUSLHS_VNReq" BU_ ARS_HS 4;
BA_ "SourceId" BU_ ARS_HS 50;
BA_ "VNECUSLHSSharedDiagnostic" BU_ MCP_B_HS 4;
BA_ "VNECUAllNodes" BU_ MCP_B_HS 4;
BA_ "ECU_Id" BU_ MCP_B_HS 24;
BA_ "VNECUSLHS_VNReq" BU_ MCP_B_HS 4;
BA_ "SourceId" BU_ MCP_B_HS 30;
BA_ "VNECUSLHSSharedDiagnostic" BU_ MCP_A_HS 4;
BA_ "VNECUAllNodes" BU_ MCP_A_HS 4;
BA_ "ECU_Id" BU_ MCP_A_HS 23;
BA_ "VNECUSLHS_VNReq" BU_ MCP_A_HS 4;
BA_ "SourceId" BU_ MCP_A_HS 206;
BA_ "VNECUSLHSSharedDiagnostic" BU_ ICCM_OBD_HS 4;
BA_ "VNECUAllNodes" BU_ ICCM_OBD_HS 4;
BA_ "ECU_Id" BU_ ICCM_OBD_HS 227;
BA_ "VNECUSLHS_VNReq" BU_ ICCM_OBD_HS 4;
BA_ "SourceId" BU_ ICCM_OBD_HS 19;
BA_ "VNECUSLHSSharedDiagnostic" BU_ SAS_HS 4;
BA_ "VNECUAllNodes" BU_ SAS_HS 4;
BA_ "ECU_Id" BU_ SAS_HS 23;
BA_ "VNECUSLHS_VNReq" BU_ SAS_HS 4;
BA_ "SourceId" BU_ SAS_HS 52;
BA_ "VNECUSLHSSharedDiagnostic" BU_ ACCM_HS 4;
BA_ "VNECUAllNodes" BU_ ACCM_HS 4;
BA_ "ECU_Id" BU_ ACCM_HS 53;
BA_ "VNECUSLHS_VNReq" BU_ ACCM_HS 4;
BA_ "SourceId" BU_ ACCM_HS 156;
BA_ "VNECUSLHSSharedDiagnostic" BU_ VLBS_HS 4;
BA_ "VNECUAllNodes" BU_ VLBS_HS 4;
BA_ "ECU_Id" BU_ VLBS_HS 31;
BA_ "VNECUSLHS_VNReq" BU_ VLBS_HS 4;
BA_ "SourceId" BU_ VLBS_HS 144;
BA_ "DA9_N78" BU_ EBCM_OBD_HS 1;
BA_ "VNECUSLHSSharedDiagnostic" BU_ EBCM_OBD_HS 4;
BA_ "D34_N99" BU_ EBCM_OBD_HS 1;
BA_ "D23_FRdMemAddr" BU_ EBCM_OBD_HS 1;
BA_ "D27_N78" BU_ EBCM_OBD_HS 1;
BA_ "D27_N12" BU_ EBCM_OBD_HS 1;
BA_ "D34_N22" BU_ EBCM_OBD_HS 1;
BA_ "D12_FRdFailRec" BU_ EBCM_OBD_HS 1;
BA_ "D36_N31" BU_ EBCM_OBD_HS 1;
BA_ "DAA_N78" BU_ EBCM_OBD_HS 1;
BA_ "D1A_N12" BU_ EBCM_OBD_HS 1;
BA_ "DAE_NE3" BU_ EBCM_OBD_HS 1;
BA_ "D10_L02_DisAllDTCs" BU_ EBCM_OBD_HS 1;
BA_ "D27_N35" BU_ EBCM_OBD_HS 1;
BA_ "D3B_FWrtBlk" BU_ EBCM_OBD_HS 1;
BA_ "D2C_N78" BU_ EBCM_OBD_HS 1;
BA_ "DA5_N22" BU_ EBCM_OBD_HS 1;
BA_ "D12_L02_RdFRcdParam" BU_ EBCM_OBD_HS 1;
BA_ "DAA_L01_SndOneRsp" BU_ EBCM_OBD_HS 1;
BA_ "D27_N36" BU_ EBCM_OBD_HS 1;
BA_ "D28_N22" BU_ EBCM_OBD_HS 1;
BA_ "DAA_L04_FastRate" BU_ EBCM_OBD_HS 1;
BA_ "D10_N22" BU_ EBCM_OBD_HS 1;
BA_ "D3B_N12" BU_ EBCM_OBD_HS 1;
BA_ "DAA_L02_SlowRate" BU_ EBCM_OBD_HS 1;
BA_ "DAE_N78" BU_ EBCM_OBD_HS 1;
BA_ "D27_N22" BU_ EBCM_OBD_HS 1;
BA_ "D27_L02_SndKey" BU_ EBCM_OBD_HS 1;
BA_ "D2C_N12" BU_ EBCM_OBD_HS 1;
BA_ "D27_L01_ReqSeed" BU_ EBCM_OBD_HS 1;
BA_ "D3B_N78" BU_ EBCM_OBD_HS 1;
BA_ "DAA_FRdDPID" BU_ EBCM_OBD_HS 1;
BA_ "D12_N78" BU_ EBCM_OBD_HS 1;
BA_ "DAE_FDevCtrl" BU_ EBCM_OBD_HS 1;
BA_ "DA9_L82_SndChgDTC" BU_ EBCM_OBD_HS 1;
BA_ "D27_N37" BU_ EBCM_OBD_HS 1;
BA_ "D22_FRdDataByPID" BU_ EBCM_OBD_HS 1;
BA_ "D27_L03_CtrlReqSeed" BU_ EBCM_OBD_HS 1;
BA_ "DAE_N31" BU_ EBCM_OBD_HS 1;
BA_ "D3B_N31" BU_ EBCM_OBD_HS 1;
BA_ "D34_N78" BU_ EBCM_OBD_HS 1;
BA_ "D36_N78" BU_ EBCM_OBD_HS 1;
BA_ "D23_N31" BU_ EBCM_OBD_HS 1;
BA_ "DAA_N31" BU_ EBCM_OBD_HS 1;
BA_ "VNECUAllNodes" BU_ EBCM_OBD_HS 4;
BA_ "DAE_N12" BU_ EBCM_OBD_HS 1;
BA_ "D3E_N12" BU_ EBCM_OBD_HS 1;
BA_ "DAA_N12" BU_ EBCM_OBD_HS 1;
BA_ "D28_N12" BU_ EBCM_OBD_HS 1;
BA_ "ECU_Id" BU_ EBCM_OBD_HS 3;
BA_ "D36_N83" BU_ EBCM_OBD_HS 1;
BA_ "D1A_N78" BU_ EBCM_OBD_HS 1;
BA_ "D27_L04_DevCtrlSeedKey" BU_ EBCM_OBD_HS 1;
BA_ "D2C_FDynMsg" BU_ EBCM_OBD_HS 1;
BA_ "D20_N12" BU_ EBCM_OBD_HS 1;
BA_ "DA9_N12" BU_ EBCM_OBD_HS 1;
BA_ "DA9_N31" BU_ EBCM_OBD_HS 1;
BA_ "DA5_L03_EnabProgMode" BU_ EBCM_OBD_HS 1;
BA_ "D23_N12" BU_ EBCM_OBD_HS 1;
BA_ "DA5_L01_ReqProgMode" BU_ EBCM_OBD_HS 1;
BA_ "VNECUSLHS_VNReq" BU_ EBCM_OBD_HS 4;
BA_ "D12_N31" BU_ EBCM_OBD_HS 1;
BA_ "DA5_N12" BU_ EBCM_OBD_HS 1;
BA_ "D22_N12" BU_ EBCM_OBD_HS 1;
BA_ "D27_FSecAcc" BU_ EBCM_OBD_HS 1;
BA_ "D36_N12" BU_ EBCM_OBD_HS 1;
BA_ "DA9_L80_RdStatDTCbyNum" BU_ EBCM_OBD_HS 1;
BA_ "D1A_N31" BU_ EBCM_OBD_HS 1;
BA_ "DAA_L00_StopSnd" BU_ EBCM_OBD_HS 1;
BA_ "D36_N85" BU_ EBCM_OBD_HS 1;
BA_ "D10_L03_DTCsDurDevCtrl" BU_ EBCM_OBD_HS 1;
BA_ "D1A_N22" BU_ EBCM_OBD_HS 1;
BA_ "D12_N12" BU_ EBCM_OBD_HS 1;
BA_ "D12_L01_RdFRcdData" BU_ EBCM_OBD_HS 1;
BA_ "D34_N12" BU_ EBCM_OBD_HS 1;
BA_ "D04_N12" BU_ EBCM_OBD_HS 1;
BA_ "DAA_L03_MedRate" BU_ EBCM_OBD_HS 1;
BA_ "D36_N22" BU_ EBCM_OBD_HS 1;
BA_ "D36_L80_DwnldExec" BU_ EBCM_OBD_HS 1;
BA_ "D04_N22" BU_ EBCM_OBD_HS 1;
BA_ "D3B_N22" BU_ EBCM_OBD_HS 1;
BA_ "DAA_N81" BU_ EBCM_OBD_HS 1;
BA_ "D36_L00_DownLoad" BU_ EBCM_OBD_HS 1;
BA_ "SourceId" BU_ EBCM_OBD_HS 40;
BA_ "D2C_N31" BU_ EBCM_OBD_HS 1;
BA_ "DA2_N12" BU_ EBCM_OBD_HS 1;
BA_ "D10_N12" BU_ EBCM_OBD_HS 1;
BA_ "VNECUSLHSSharedDiagnostic" BU_ EDI_HS 4;
BA_ "VNECUAllNodes" BU_ EDI_HS 4;
BA_ "VNECUSLHS_VNReq" BU_ EDI_HS 4;
BA_ "VNECUSLHSSharedDiagnostic" BU_ HPCC_HS 4;
BA_ "VNECUAllNodes" BU_ HPCC_HS 4;
BA_ "ECU_Id" BU_ HPCC_HS 3;
BA_ "VNECUSLHS_VNReq" BU_ HPCC_HS 4;
BA_ "SourceId" BU_ HPCC_HS 200;
BA_ "VNECUSLHSSharedDiagnostic" BU_ VITM_OBD_HS 4;
BA_ "VNECUAllNodes" BU_ VITM_OBD_HS 4;
BA_ "ECU_Id" BU_ VITM_OBD_HS 231;
BA_ "VNECUSLHS_VNReq" BU_ VITM_OBD_HS 4;
BA_ "SourceId" BU_ VITM_OBD_HS 205;
BA_ "VNECUSLHSSharedDiagnostic" BU_ PTAM_HS 4;
BA_ "VNECUAllNodes" BU_ PTAM_HS 4;
BA_ "ECU_Id" BU_ PTAM_HS 16;
BA_ "VNECUSLHS_VNReq" BU_ PTAM_HS 4;
BA_ "SourceId" BU_ PTAM_HS 32;
BA_ "VNECUSLHSSharedDiagnostic" BU_ OBCM_HS 4;
BA_ "VNECUAllNodes" BU_ OBCM_HS 4;
BA_ "ECU_Id" BU_ OBCM_HS 68;
BA_ "VNECUSLHS_VNReq" BU_ OBCM_HS 4;
BA_ "SourceId" BU_ OBCM_HS 202;
BA_ "VNECUSLHSSharedDiagnostic" BU_ VICM_HS 4;
BA_ "VNECUAllNodes" BU_ VICM_HS 4;
BA_ "ECU_Id" BU_ VICM_HS 228;
BA_ "VNECUSLHS_VNReq" BU_ VICM_HS 4;
BA_ "SourceId" BU_ VICM_HS 203;
BA_ "VNECUAllNodes" BU_ HCP_HS 4;
BA_ "ECU_Id" BU_ HCP_HS 225;
BA_ "SourceId" BU_ HCP_HS 23;
BA_ "VNECUSLHSSharedDiagnostic" BU_ FDCM_HS 4;
BA_ "VNECUAllNodes" BU_ FDCM_HS 4;
BA_ "ECU_Id" BU_ FDCM_HS 17;
BA_ "VNECUSLHS_VNReq" BU_ FDCM_HS 4;
BA_ "SourceId" BU_ FDCM_HS 54;
BA_ "VNECUSLHSSharedDiagnostic" BU_ APPS_HS 4;
BA_ "VNECUAllNodes" BU_ APPS_HS 4;
BA_ "ECU_Id" BU_ APPS_HS 6;
BA_ "VNECUSLHS_VNReq" BU_ APPS_HS 4;
BA_ "SourceId" BU_ APPS_HS 93;
BA_ "VNECUSLHSSharedDiagnostic" BU_ ICCM_HS 4;
BA_ "VNECUAllNodes" BU_ ICCM_HS 4;
BA_ "ECU_Id" BU_ ICCM_HS 227;
BA_ "VNECUSLHS_VNReq" BU_ ICCM_HS 4;
BA_ "SourceId" BU_ ICCM_HS 34;
BA_ "VNECUSLHSSharedDiagnostic" BU_ EOCM_F_HS 4;
BA_ "VNECUAllNodes" BU_ EOCM_F_HS 4;
BA_ "ECU_Id" BU_ EOCM_F_HS 75;
BA_ "VNECUSLHS_VNReq" BU_ EOCM_F_HS 4;
BA_ "SourceId" BU_ EOCM_F_HS 108;
BA_ "VNECUSLHSSharedDiagnostic" BU_ GPCM_HS 4;
BA_ "VNECUAllNodes" BU_ GPCM_HS 4;
BA_ "ECU_Id" BU_ GPCM_HS 230;
BA_ "VNECUSLHS_VNReq" BU_ GPCM_HS 4;
BA_ "SourceId" BU_ GPCM_HS 22;
BA_ "VNECUSLHSSharedDiagnostic" BU_ FSCM_ITBC_HS 4;
BA_ "VNECUAllNodes" BU_ FSCM_ITBC_HS 4;
BA_ "ECU_Id" BU_ FSCM_ITBC_HS 227;
BA_ "VNECUSLHS_VNReq" BU_ FSCM_ITBC_HS 4;
BA_ "SourceId" BU_ FSCM_ITBC_HS 19;
BA_ "VNECUSLHSSharedDiagnostic" BU_ SCM_HS 4;
BA_ "VNECUAllNodes" BU_ SCM_HS 4;
BA_ "ECU_Id" BU_ SCM_HS 16;
BA_ "VNECUSLHS_VNReq" BU_ SCM_HS 4;
BA_ "SourceId" BU_ SCM_HS 32;
BA_ "VNECUSLHSSharedDiagnostic" BU_ ITBC_HS 4;
BA_ "VNECUAllNodes" BU_ ITBC_HS 4;
BA_ "ECU_Id" BU_ ITBC_HS 4;
BA_ "VNECUSLHS_VNReq" BU_ ITBC_HS 4;
BA_ "SourceId" BU_ ITBC_HS 45;
BA_ "VNECUSLHSSharedDiagnostic" BU_ VCM_HS 4;
BA_ "VNECUAllNodes" BU_ VCM_HS 4;
BA_ "ECU_Id" BU_ VCM_HS 30;
BA_ "VNECUSLHS_VNReq" BU_ VCM_HS 4;
BA_ "SourceId" BU_ VCM_HS 20;
BA_ "VNECUSLHSSharedDiagnostic" BU_ HMIM_HS 4;
BA_ "VNECUAllNodes" BU_ HMIM_HS 4;
BA_ "ECU_Id" BU_ HMIM_HS 18;
BA_ "VNECUSLHS_VNReq" BU_ HMIM_HS 4;
BA_ "SourceId" BU_ HMIM_HS 143;
BA_ "VNECUSLHSSharedDiagnostic" BU_ FCP_HS 4;
BA_ "VNECUAllNodes" BU_ FCP_HS 4;
BA_ "ECU_Id" BU_ FCP_HS 13;
BA_ "VNECUSLHS_VNReq" BU_ FCP_HS 4;
BA_ "SourceId" BU_ FCP_HS 151;
BA_ "VNECUSLHSSharedDiagnostic" BU_ VES_HS 4;
BA_ "VNECUAllNodes" BU_ VES_HS 4;
BA_ "ECU_Id" BU_ VES_HS 2;
BA_ "VNECUSLHS_VNReq" BU_ VES_HS 4;
BA_ "SourceId" BU_ VES_HS 49;
BA_ "VNECUSLHSSharedDiagnostic" BU_ Dummy_HS 4;
BA_ "VNECUAllNodes" BU_ Dummy_HS 4;
BA_ "VNECUSLHSSharedDiagnostic" BU_ MCP_C_HS 4;
BA_ "VNECUAllNodes" BU_ MCP_C_HS 4;
BA_ "ECU_Id" BU_ MCP_C_HS 25;
BA_ "VNECUSLHS_VNReq" BU_ MCP_C_HS 4;
BA_ "SourceId" BU_ MCP_C_HS 31;
BA_ "VNECUSLHSSharedDiagnostic" BU_ RWS_HS 4;
BA_ "VNECUAllNodes" BU_ RWS_HS 4;
BA_ "ECU_Id" BU_ RWS_HS 6;
BA_ "VNECUSLHS_VNReq" BU_ RWS_HS 4;
BA_ "SourceId" BU_ RWS_HS 50;
BA_ "VNECUSLHSSharedDiagnostic" BU_ ONSTAR_HS 4;
BA_ "VNECUAllNodes" BU_ ONSTAR_HS 4;
BA_ "ECU_Id" BU_ ONSTAR_HS 13;
BA_ "VNECUSLHS_VNReq" BU_ ONSTAR_HS 4;
BA_ "SourceId" BU_ ONSTAR_HS 151;
BA_ "VNECUSLHSSharedDiagnostic" BU_ EPS_HS 4;
BA_ "VNECUAllNodes" BU_ EPS_HS 4;
BA_ "ECU_Id" BU_ EPS_HS 2;
BA_ "VNECUSLHS_VNReq" BU_ EPS_HS 4;
BA_ "SourceId" BU_ EPS_HS 49;
BA_ "VNECUSLHSSharedDiagnostic" BU_ TestTool_HS 4;
BA_ "VNECUAllNodes" BU_ TestTool_HS 4;
BA_ "VNECUSLHS_VNReq" BU_ TestTool_HS 4;
BA_ "SourceId" BU_ TestTool_HS 253;
BA_ "VNECUSLHSSharedDiagnostic" BU_ MCP_HS 4;
BA_ "VNECUAllNodes" BU_ MCP_HS 4;
BA_ "ECU_Id" BU_ MCP_HS 23;
BA_ "VNECUSLHS_VNReq" BU_ MCP_HS 4;
BA_ "SourceId" BU_ MCP_HS 206;
BA_ "VNECUSLHSSharedDiagnostic" BU_ BCP_HS 4;
BA_ "VNECUAllNodes" BU_ BCP_HS 4;
BA_ "ECU_Id" BU_ BCP_HS 225;
BA_ "VNECUSLHS_VNReq" BU_ BCP_HS 4;
BA_ "SourceId" BU_ BCP_HS 23;
BA_ "VNECUSLHSSharedDiagnostic" BU_ ALC_HS 4;
BA_ "VNECUAllNodes" BU_ ALC_HS 4;
BA_ "ECU_Id" BU_ ALC_HS 14;
BA_ "VNECUSLHS_VNReq" BU_ ALC_HS 4;
BA_ "SourceId" BU_ ALC_HS 58;
BA_ "VNECUSLHSSharedDiagnostic" BU_ AHL_AFL_HS 4;
BA_ "VNECUAllNodes" BU_ AHL_AFL_HS 4;
BA_ "ECU_Id" BU_ AHL_AFL_HS 9;
BA_ "VNECUSLHS_VNReq" BU_ AHL_AFL_HS 4;
BA_ "SourceId" BU_ AHL_AFL_HS 114;
BA_ "VNECUSLHSSharedDiagnostic" BU_ SADS_HS 4;
BA_ "VNECUAllNodes" BU_ SADS_HS 4;
BA_ "ECU_Id" BU_ SADS_HS 14;
BA_ "VNECUSLHS_VNReq" BU_ SADS_HS 4;
BA_ "SourceId" BU_ SADS_HS 56;
BA_ "VNECUSLHSSharedDiagnostic" BU_ EPB_HS 4;
BA_ "VNECUAllNodes" BU_ EPB_HS 4;
BA_ "ECU_Id" BU_ EPB_HS 20;
BA_ "VNECUSLHS_VNReq" BU_ EPB_HS 4;
BA_ "SourceId" BU_ EPB_HS 43;
BA_ "VNECUSLHSSharedDiagnostic" BU_ FSCM_HS 4;
BA_ "VNECUAllNodes" BU_ FSCM_HS 4;
BA_ "ECU_Id" BU_ FSCM_HS 227;
BA_ "VNECUSLHS_VNReq" BU_ FSCM_HS 4;
BA_ "SourceId" BU_ FSCM_HS 19;
BA_ "VNECUSLHSSharedDiagnostic" BU_ AFS_HS 4;
BA_ "VNECUAllNodes" BU_ AFS_HS 4;
BA_ "ECU_Id" BU_ AFS_HS 21;
BA_ "VNECUSLHS_VNReq" BU_ AFS_HS 4;
BA_ "SourceId" BU_ AFS_HS 51;
BA_ "VNECUSLHSSharedDiagnostic" BU_ FCM_HS 4;
BA_ "VNECUAllNodes" BU_ FCM_HS 4;
BA_ "ECU_Id" BU_ FCM_HS 11;
BA_ "VNECUSLHS_VNReq" BU_ FCM_HS 4;
BA_ "SourceId" BU_ FCM_HS 188;
BA_ "VNECUSLHSSharedDiagnostic" BU_ TCCM_HS 4;
BA_ "VNECUAllNodes" BU_ TCCM_HS 4;
BA_ "ECU_Id" BU_ TCCM_HS 22;
BA_ "VNECUSLHS_VNReq" BU_ TCCM_HS 4;
BA_ "SourceId" BU_ TCCM_HS 26;
BA_ "VNECUSLHSSharedDiagnostic" BU_ RDCM_HS 4;
BA_ "VNECUAllNodes" BU_ RDCM_HS 4;
BA_ "ECU_Id" BU_ RDCM_HS 15;
BA_ "VNECUSLHS_VNReq" BU_ RDCM_HS 4;
BA_ "SourceId" BU_ RDCM_HS 27;
BA_ "VNECUSLHSSharedDiagnostic" BU_ PTO_HS 4;
BA_ "VNECUAllNodes" BU_ PTO_HS 4;
BA_ "ECU_Id" BU_ PTO_HS 7;
BA_ "VNECUSLHS_VNReq" BU_ PTO_HS 4;
BA_ "SourceId" BU_ PTO_HS 25;
BA_ "VNECUSLHSSharedDiagnostic" BU_ PCM_HS 4;
BA_ "VNECUAllNodes" BU_ PCM_HS 4;
BA_ "ECU_Id" BU_ PCM_HS 225;
BA_ "VNECUSLHS_VNReq" BU_ PCM_HS 4;
BA_ "SourceId" BU_ PCM_HS 17;
BA_ "DA9_N78" BU_ EBCM_HS 1;
BA_ "VNECUSLHSSharedDiagnostic" BU_ EBCM_HS 4;
BA_ "D34_N99" BU_ EBCM_HS 1;
BA_ "D23_FRdMemAddr" BU_ EBCM_HS 1;
BA_ "D27_N78" BU_ EBCM_HS 1;
BA_ "D27_N12" BU_ EBCM_HS 1;
BA_ "D34_N22" BU_ EBCM_HS 1;
BA_ "D12_FRdFailRec" BU_ EBCM_HS 1;
BA_ "D36_N31" BU_ EBCM_HS 1;
BA_ "DAA_N78" BU_ EBCM_HS 1;
BA_ "D1A_N12" BU_ EBCM_HS 1;
BA_ "DAE_NE3" BU_ EBCM_HS 1;
BA_ "D10_L02_DisAllDTCs" BU_ EBCM_HS 1;
BA_ "D27_N35" BU_ EBCM_HS 1;
BA_ "D3B_FWrtBlk" BU_ EBCM_HS 1;
BA_ "D2C_N78" BU_ EBCM_HS 1;
BA_ "DA5_N22" BU_ EBCM_HS 1;
BA_ "D12_L02_RdFRcdParam" BU_ EBCM_HS 1;
BA_ "DAA_L01_SndOneRsp" BU_ EBCM_HS 1;
BA_ "D27_N36" BU_ EBCM_HS 1;
BA_ "D28_N22" BU_ EBCM_HS 1;
BA_ "DAA_L04_FastRate" BU_ EBCM_HS 1;
BA_ "D10_N22" BU_ EBCM_HS 1;
BA_ "D3B_N12" BU_ EBCM_HS 1;
BA_ "DAA_L02_SlowRate" BU_ EBCM_HS 1;
BA_ "DAE_N78" BU_ EBCM_HS 1;
BA_ "D27_N22" BU_ EBCM_HS 1;
BA_ "D27_L02_SndKey" BU_ EBCM_HS 1;
BA_ "D2C_N12" BU_ EBCM_HS 1;
BA_ "D27_L01_ReqSeed" BU_ EBCM_HS 1;
BA_ "D3B_N78" BU_ EBCM_HS 1;
BA_ "DAA_FRdDPID" BU_ EBCM_HS 1;
BA_ "D12_N78" BU_ EBCM_HS 1;
BA_ "DAE_FDevCtrl" BU_ EBCM_HS 1;
BA_ "DA9_L82_SndChgDTC" BU_ EBCM_HS 1;
BA_ "D27_N37" BU_ EBCM_HS 1;
BA_ "D22_FRdDataByPID" BU_ EBCM_HS 1;
BA_ "D27_L03_CtrlReqSeed" BU_ EBCM_HS 1;
BA_ "DAE_N31" BU_ EBCM_HS 1;
BA_ "D3B_N31" BU_ EBCM_HS 1;
BA_ "D34_N78" BU_ EBCM_HS 1;
BA_ "D36_N78" BU_ EBCM_HS 1;
BA_ "D23_N31" BU_ EBCM_HS 1;
BA_ "DAA_N31" BU_ EBCM_HS 1;
BA_ "VNECUAllNodes" BU_ EBCM_HS 4;
BA_ "DAE_N12" BU_ EBCM_HS 1;
BA_ "D3E_N12" BU_ EBCM_HS 1;
BA_ "DAA_N12" BU_ EBCM_HS 1;
BA_ "D28_N12" BU_ EBCM_HS 1;
BA_ "ECU_Id" BU_ EBCM_HS 3;
BA_ "D36_N83" BU_ EBCM_HS 1;
BA_ "D1A_N78" BU_ EBCM_HS 1;
BA_ "D27_L04_DevCtrlSeedKey" BU_ EBCM_HS 1;
BA_ "D2C_FDynMsg" BU_ EBCM_HS 1;
BA_ "D20_N12" BU_ EBCM_HS 1;
BA_ "DA9_N12" BU_ EBCM_HS 1;
BA_ "DA9_N31" BU_ EBCM_HS 1;
BA_ "DA5_L03_EnabProgMode" BU_ EBCM_HS 1;
BA_ "D23_N12" BU_ EBCM_HS 1;
BA_ "DA5_L01_ReqProgMode" BU_ EBCM_HS 1;
BA_ "VNECUSLHS_VNReq" BU_ EBCM_HS 4;
BA_ "D12_N31" BU_ EBCM_HS 1;
BA_ "DA5_N12" BU_ EBCM_HS 1;
BA_ "D22_N12" BU_ EBCM_HS 1;
BA_ "D27_FSecAcc" BU_ EBCM_HS 1;
BA_ "D36_N12" BU_ EBCM_HS 1;
BA_ "DA9_L80_RdStatDTCbyNum" BU_ EBCM_HS 1;
BA_ "D1A_N31" BU_ EBCM_HS 1;
BA_ "DAA_L00_StopSnd" BU_ EBCM_HS 1;
BA_ "D36_N85" BU_ EBCM_HS 1;
BA_ "D10_L03_DTCsDurDevCtrl" BU_ EBCM_HS 1;
BA_ "D1A_N22" BU_ EBCM_HS 1;
BA_ "D12_N12" BU_ EBCM_HS 1;
BA_ "D12_L01_RdFRcdData" BU_ EBCM_HS 1;
BA_ "D34_N12" BU_ EBCM_HS 1;
BA_ "D04_N12" BU_ EBCM_HS 1;
BA_ "DAA_L03_MedRate" BU_ EBCM_HS 1;
BA_ "D36_N22" BU_ EBCM_HS 1;
BA_ "D36_L80_DwnldExec" BU_ EBCM_HS 1;
BA_ "D04_N22" BU_ EBCM_HS 1;
BA_ "D3B_N22" BU_ EBCM_HS 1;
BA_ "DAA_N81" BU_ EBCM_HS 1;
BA_ "D36_L00_DownLoad" BU_ EBCM_HS 1;
BA_ "SourceId" BU_ EBCM_HS 40;
BA_ "D2C_N31" BU_ EBCM_HS 1;
BA_ "DA2_N12" BU_ EBCM_HS 1;
BA_ "D10_N12" BU_ EBCM_HS 1;
BA_ "DA9_N78" BU_ ACC_HS 1;
BA_ "VNECUSLHSSharedDiagnostic" BU_ ACC_HS 4;
BA_ "D34_N99" BU_ ACC_HS 1;
BA_ "D23_FRdMemAddr" BU_ ACC_HS 1;
BA_ "D27_N78" BU_ ACC_HS 1;
BA_ "D27_N12" BU_ ACC_HS 1;
BA_ "D34_N22" BU_ ACC_HS 1;
BA_ "D12_FRdFailRec" BU_ ACC_HS 1;
BA_ "D36_N31" BU_ ACC_HS 1;
BA_ "DAA_N78" BU_ ACC_HS 1;
BA_ "D1A_N12" BU_ ACC_HS 1;
BA_ "DAE_NE3" BU_ ACC_HS 1;
BA_ "D10_L02_DisAllDTCs" BU_ ACC_HS 1;
BA_ "D27_N35" BU_ ACC_HS 1;
BA_ "D3B_FWrtBlk" BU_ ACC_HS 1;
BA_ "DA5_N22" BU_ ACC_HS 1;
BA_ "D12_L02_RdFRcdParam" BU_ ACC_HS 1;
BA_ "DAA_L01_SndOneRsp" BU_ ACC_HS 1;
BA_ "D27_N36" BU_ ACC_HS 1;
BA_ "D28_N22" BU_ ACC_HS 1;
BA_ "DAA_L04_FastRate" BU_ ACC_HS 1;
BA_ "D10_N22" BU_ ACC_HS 1;
BA_ "D3B_N12" BU_ ACC_HS 1;
BA_ "DAA_L02_SlowRate" BU_ ACC_HS 1;
BA_ "DAE_N78" BU_ ACC_HS 1;
BA_ "D27_N22" BU_ ACC_HS 1;
BA_ "D27_L02_SndKey" BU_ ACC_HS 1;
BA_ "D27_L01_ReqSeed" BU_ ACC_HS 1;
BA_ "D36_N89" BU_ ACC_HS 1;
BA_ "D3B_N78" BU_ ACC_HS 1;
BA_ "DAA_FRdDPID" BU_ ACC_HS 1;
BA_ "D12_N78" BU_ ACC_HS 1;
BA_ "DAE_FDevCtrl" BU_ ACC_HS 1;
BA_ "DA9_L82_SndChgDTC" BU_ ACC_HS 1;
BA_ "D10_N78" BU_ ACC_HS 1;
BA_ "D27_N37" BU_ ACC_HS 1;
BA_ "D27_L03_CtrlReqSeed" BU_ ACC_HS 1;
BA_ "D04_N78" BU_ ACC_HS 1;
BA_ "DAE_N31" BU_ ACC_HS 1;
BA_ "D3B_N31" BU_ ACC_HS 1;
BA_ "D34_N78" BU_ ACC_HS 1;
BA_ "D36_N78" BU_ ACC_HS 1;
BA_ "D23_N31" BU_ ACC_HS 1;
BA_ "DAA_N31" BU_ ACC_HS 1;
BA_ "VNECUAllNodes" BU_ ACC_HS 4;
BA_ "DAE_N12" BU_ ACC_HS 1;
BA_ "D3E_N12" BU_ ACC_HS 1;
BA_ "DAA_N12" BU_ ACC_HS 1;
BA_ "D28_N12" BU_ ACC_HS 1;
BA_ "ECU_Id" BU_ ACC_HS 27;
BA_ "D36_N83" BU_ ACC_HS 1;
BA_ "D1A_N78" BU_ ACC_HS 1;
BA_ "D27_L04_DevCtrlSeedKey" BU_ ACC_HS 1;
BA_ "DA2_N78" BU_ ACC_HS 1;
BA_ "D20_N12" BU_ ACC_HS 1;
BA_ "DA9_N12" BU_ ACC_HS 1;
BA_ "DA9_N31" BU_ ACC_HS 1;
BA_ "DA5_L03_EnabProgMode" BU_ ACC_HS 1;
BA_ "D23_N12" BU_ ACC_HS 1;
BA_ "D23_N78" BU_ ACC_HS 1;
BA_ "DA5_L01_ReqProgMode" BU_ ACC_HS 1;
BA_ "VNECUSLHS_VNReq" BU_ ACC_HS 4;
BA_ "D12_N31" BU_ ACC_HS 1;
BA_ "DA5_N12" BU_ ACC_HS 1;
BA_ "D27_FSecAcc" BU_ ACC_HS 1;
BA_ "D36_N12" BU_ ACC_HS 1;
BA_ "DA9_L80_RdStatDTCbyNum" BU_ ACC_HS 1;
BA_ "DA5_N78" BU_ ACC_HS 1;
BA_ "D1A_N31" BU_ ACC_HS 1;
BA_ "DAA_L00_StopSnd" BU_ ACC_HS 1;
BA_ "D36_N85" BU_ ACC_HS 1;
BA_ "DA9_L81_RdStatDTCbyMsk" BU_ ACC_HS 1;
BA_ "D10_L03_DTCsDurDevCtrl" BU_ ACC_HS 1;
BA_ "D1A_N22" BU_ ACC_HS 1;
BA_ "D12_N12" BU_ ACC_HS 1;
BA_ "D12_L01_RdFRcdData" BU_ ACC_HS 1;
BA_ "D34_N12" BU_ ACC_HS 1;
BA_ "D04_N12" BU_ ACC_HS 1;
BA_ "DAA_L03_MedRate" BU_ ACC_HS 1;
BA_ "D36_N22" BU_ ACC_HS 1;
BA_ "D36_L80_DwnldExec" BU_ ACC_HS 1;
BA_ "D04_N22" BU_ ACC_HS 1;
BA_ "D3B_N22" BU_ ACC_HS 1;
BA_ "DAA_N81" BU_ ACC_HS 1;
BA_ "D36_L00_DownLoad" BU_ ACC_HS 1;
BA_ "SourceId" BU_ ACC_HS 33;
BA_ "DA2_N12" BU_ ACC_HS 1;
BA_ "D10_N12" BU_ ACC_HS 1;
BA_ "DA9_N78" BU_ BCM_HS 1;
BA_ "VNECUSLHSSharedDiagnostic" BU_ BCM_HS 4;
BA_ "D34_N99" BU_ BCM_HS 1;
BA_ "D23_FRdMemAddr" BU_ BCM_HS 1;
BA_ "D27_N78" BU_ BCM_HS 1;
BA_ "D27_N12" BU_ BCM_HS 1;
BA_ "D34_N22" BU_ BCM_HS 1;
BA_ "D36_N31" BU_ BCM_HS 1;
BA_ "DAA_N78" BU_ BCM_HS 1;
BA_ "D1A_N12" BU_ BCM_HS 1;
BA_ "DAE_NE3" BU_ BCM_HS 1;
BA_ "D10_L02_DisAllDTCs" BU_ BCM_HS 1;
BA_ "D27_N35" BU_ BCM_HS 1;
BA_ "D3B_FWrtBlk" BU_ BCM_HS 1;
BA_ "D2C_N78" BU_ BCM_HS 1;
BA_ "DA5_N22" BU_ BCM_HS 1;
BA_ "DAA_L01_SndOneRsp" BU_ BCM_HS 1;
BA_ "D27_N36" BU_ BCM_HS 1;
BA_ "D28_N22" BU_ BCM_HS 1;
BA_ "DAA_L04_FastRate" BU_ BCM_HS 1;
BA_ "D10_N22" BU_ BCM_HS 1;
BA_ "D3B_N12" BU_ BCM_HS 1;
BA_ "DAA_L02_SlowRate" BU_ BCM_HS 1;
BA_ "DAE_N78" BU_ BCM_HS 1;
BA_ "D27_N22" BU_ BCM_HS 1;
BA_ "D27_L02_SndKey" BU_ BCM_HS 1;
BA_ "D2C_N12" BU_ BCM_HS 1;
BA_ "D27_L01_ReqSeed" BU_ BCM_HS 1;
BA_ "D3B_N78" BU_ BCM_HS 1;
BA_ "DAA_FRdDPID" BU_ BCM_HS 1;
BA_ "DAE_FDevCtrl" BU_ BCM_HS 1;
BA_ "D10_N78" BU_ BCM_HS 1;
BA_ "D27_N37" BU_ BCM_HS 1;
BA_ "D04_N78" BU_ BCM_HS 1;
BA_ "DAE_N31" BU_ BCM_HS 1;
BA_ "D3B_N31" BU_ BCM_HS 1;
BA_ "D34_N78" BU_ BCM_HS 1;
BA_ "D36_N78" BU_ BCM_HS 1;
BA_ "D23_N31" BU_ BCM_HS 1;
BA_ "DAA_N31" BU_ BCM_HS 1;
BA_ "VNECUAllNodes" BU_ BCM_HS 4;
BA_ "DAE_N12" BU_ BCM_HS 1;
BA_ "D3E_N12" BU_ BCM_HS 1;
BA_ "DAA_N12" BU_ BCM_HS 1;
BA_ "D28_N12" BU_ BCM_HS 1;
BA_ "ECU_Id" BU_ BCM_HS 1;
BA_ "D36_N83" BU_ BCM_HS 1;
BA_ "D1A_N78" BU_ BCM_HS 1;
BA_ "D2C_FDynMsg" BU_ BCM_HS 1;
BA_ "DA2_N78" BU_ BCM_HS 1;
BA_ "D20_N12" BU_ BCM_HS 1;
BA_ "DA9_N12" BU_ BCM_HS 1;
BA_ "DA9_N31" BU_ BCM_HS 1;
BA_ "DA5_L03_EnabProgMode" BU_ BCM_HS 1;
BA_ "D23_N12" BU_ BCM_HS 1;
BA_ "D23_N78" BU_ BCM_HS 1;
BA_ "DA5_L01_ReqProgMode" BU_ BCM_HS 1;
BA_ "VNECUSLHS_VNReq" BU_ BCM_HS 4;
BA_ "DA5_N12" BU_ BCM_HS 1;
BA_ "D27_FSecAcc" BU_ BCM_HS 1;
BA_ "D36_N12" BU_ BCM_HS 1;
BA_ "DA5_N78" BU_ BCM_HS 1;
BA_ "D1A_N31" BU_ BCM_HS 1;
BA_ "DAA_L00_StopSnd" BU_ BCM_HS 1;
BA_ "D36_N85" BU_ BCM_HS 1;
BA_ "D10_L03_DTCsDurDevCtrl" BU_ BCM_HS 1;
BA_ "D1A_N22" BU_ BCM_HS 1;
BA_ "D10_L04_WakeUpLinks" BU_ BCM_HS 1;
BA_ "D34_N12" BU_ BCM_HS 1;
BA_ "D04_N12" BU_ BCM_HS 1;
BA_ "DAA_L03_MedRate" BU_ BCM_HS 1;
BA_ "D36_N22" BU_ BCM_HS 1;
BA_ "D36_L80_DwnldExec" BU_ BCM_HS 1;
BA_ "D04_N22" BU_ BCM_HS 1;
BA_ "D3B_N22" BU_ BCM_HS 1;
BA_ "DAA_N81" BU_ BCM_HS 1;
BA_ "D36_L00_DownLoad" BU_ BCM_HS 1;
BA_ "SourceId" BU_ BCM_HS 64;
BA_ "D2C_N31" BU_ BCM_HS 1;
BA_ "DA2_N12" BU_ BCM_HS 1;
BA_ "D10_N12" BU_ BCM_HS 1;
BA_ "DA9_N78" BU_ TCM_HS 1;
BA_ "VNECUSLHSSharedDiagnostic" BU_ TCM_HS 4;
BA_ "D34_N99" BU_ TCM_HS 1;
BA_ "D23_FRdMemAddr" BU_ TCM_HS 1;
BA_ "D27_N78" BU_ TCM_HS 1;
BA_ "D27_N12" BU_ TCM_HS 1;
BA_ "D34_N22" BU_ TCM_HS 1;
BA_ "D12_FRdFailRec" BU_ TCM_HS 1;
BA_ "D36_N31" BU_ TCM_HS 1;
BA_ "DAA_N78" BU_ TCM_HS 1;
BA_ "D1A_N12" BU_ TCM_HS 1;
BA_ "DAE_NE3" BU_ TCM_HS 1;
BA_ "D10_L02_DisAllDTCs" BU_ TCM_HS 1;
BA_ "D27_N35" BU_ TCM_HS 1;
BA_ "D3B_FWrtBlk" BU_ TCM_HS 1;
BA_ "D2C_N78" BU_ TCM_HS 1;
BA_ "DA5_N22" BU_ TCM_HS 1;
BA_ "D12_L02_RdFRcdParam" BU_ TCM_HS 1;
BA_ "DAA_L01_SndOneRsp" BU_ TCM_HS 1;
BA_ "D27_N36" BU_ TCM_HS 1;
BA_ "D28_N22" BU_ TCM_HS 1;
BA_ "DAA_L04_FastRate" BU_ TCM_HS 1;
BA_ "D10_N22" BU_ TCM_HS 1;
BA_ "D3B_N12" BU_ TCM_HS 1;
BA_ "DAA_L02_SlowRate" BU_ TCM_HS 1;
BA_ "DAE_N78" BU_ TCM_HS 1;
BA_ "D27_N22" BU_ TCM_HS 1;
BA_ "D27_L02_SndKey" BU_ TCM_HS 1;
BA_ "D2C_N12" BU_ TCM_HS 1;
BA_ "D27_L01_ReqSeed" BU_ TCM_HS 1;
BA_ "D36_N89" BU_ TCM_HS 1;
BA_ "D3B_N78" BU_ TCM_HS 1;
BA_ "DAA_FRdDPID" BU_ TCM_HS 1;
BA_ "D12_N78" BU_ TCM_HS 1;
BA_ "DAE_FDevCtrl" BU_ TCM_HS 1;
BA_ "DA9_L82_SndChgDTC" BU_ TCM_HS 1;
BA_ "D10_N78" BU_ TCM_HS 1;
BA_ "D27_N37" BU_ TCM_HS 1;
BA_ "D27_L03_CtrlReqSeed" BU_ TCM_HS 1;
BA_ "D04_N78" BU_ TCM_HS 1;
BA_ "DAE_N31" BU_ TCM_HS 1;
BA_ "D3B_N31" BU_ TCM_HS 1;
BA_ "D34_N78" BU_ TCM_HS 1;
BA_ "D36_N78" BU_ TCM_HS 1;
BA_ "D23_N31" BU_ TCM_HS 1;
BA_ "DAA_N31" BU_ TCM_HS 1;
BA_ "VNECUAllNodes" BU_ TCM_HS 4;
BA_ "DAE_N12" BU_ TCM_HS 1;
BA_ "D3E_N12" BU_ TCM_HS 1;
BA_ "DAA_N12" BU_ TCM_HS 1;
BA_ "D28_N12" BU_ TCM_HS 1;
BA_ "ECU_Id" BU_ TCM_HS 226;
BA_ "D36_N83" BU_ TCM_HS 1;
BA_ "D1A_N78" BU_ TCM_HS 1;
BA_ "D27_L04_DevCtrlSeedKey" BU_ TCM_HS 1;
BA_ "D2C_FDynMsg" BU_ TCM_HS 1;
BA_ "DA2_N78" BU_ TCM_HS 1;
BA_ "D20_N12" BU_ TCM_HS 1;
BA_ "DA9_N12" BU_ TCM_HS 1;
BA_ "DA9_N31" BU_ TCM_HS 1;
BA_ "DA5_L03_EnabProgMode" BU_ TCM_HS 1;
BA_ "D23_N12" BU_ TCM_HS 1;
BA_ "D23_N78" BU_ TCM_HS 1;
BA_ "DA5_L01_ReqProgMode" BU_ TCM_HS 1;
BA_ "VNECUSLHS_VNReq" BU_ TCM_HS 4;
BA_ "D12_N31" BU_ TCM_HS 1;
BA_ "DA5_N12" BU_ TCM_HS 1;
BA_ "D27_FSecAcc" BU_ TCM_HS 1;
BA_ "D36_N12" BU_ TCM_HS 1;
BA_ "DA9_L80_RdStatDTCbyNum" BU_ TCM_HS 1;
BA_ "DA5_N78" BU_ TCM_HS 1;
BA_ "D1A_N31" BU_ TCM_HS 1;
BA_ "DAA_L00_StopSnd" BU_ TCM_HS 1;
BA_ "D36_N85" BU_ TCM_HS 1;
BA_ "DA9_L81_RdStatDTCbyMsk" BU_ TCM_HS 1;
BA_ "D10_L03_DTCsDurDevCtrl" BU_ TCM_HS 1;
BA_ "D04_ReqType" BU_ TCM_HS 0;
BA_ "D1A_N22" BU_ TCM_HS 1;
BA_ "D12_N12" BU_ TCM_HS 1;
BA_ "D12_L01_RdFRcdData" BU_ TCM_HS 1;
BA_ "D34_N12" BU_ TCM_HS 1;
BA_ "D04_N12" BU_ TCM_HS 1;
BA_ "DAA_L03_MedRate" BU_ TCM_HS 1;
BA_ "D36_N22" BU_ TCM_HS 1;
BA_ "D36_L80_DwnldExec" BU_ TCM_HS 1;
BA_ "D04_N22" BU_ TCM_HS 1;
BA_ "D3B_N22" BU_ TCM_HS 1;
BA_ "DAA_N81" BU_ TCM_HS 1;
BA_ "D36_L00_DownLoad" BU_ TCM_HS 1;
BA_ "SourceId" BU_ TCM_HS 24;
BA_ "D2C_N31" BU_ TCM_HS 1;
BA_ "DA2_N12" BU_ TCM_HS 1;
BA_ "D10_N12" BU_ TCM_HS 1;
BA_ "DA9_N78" BU_ ECM_HS 1;
BA_ "VNECUSLHSSharedDiagnostic" BU_ ECM_HS 4;
BA_ "D34_N99" BU_ ECM_HS 1;
BA_ "D23_FRdMemAddr" BU_ ECM_HS 1;
BA_ "D27_N78" BU_ ECM_HS 1;
BA_ "D27_N12" BU_ ECM_HS 1;
BA_ "D34_N22" BU_ ECM_HS 1;
BA_ "D12_FRdFailRec" BU_ ECM_HS 1;
BA_ "D36_N31" BU_ ECM_HS 1;
BA_ "DAA_N78" BU_ ECM_HS 1;
BA_ "D1A_N12" BU_ ECM_HS 1;
BA_ "DAE_NE3" BU_ ECM_HS 1;
BA_ "D10_L02_DisAllDTCs" BU_ ECM_HS 1;
BA_ "D27_N35" BU_ ECM_HS 1;
BA_ "D3B_FWrtBlk" BU_ ECM_HS 1;
BA_ "D2C_N78" BU_ ECM_HS 1;
BA_ "DA5_N22" BU_ ECM_HS 1;
BA_ "D12_L02_RdFRcdParam" BU_ ECM_HS 1;
BA_ "DAA_L01_SndOneRsp" BU_ ECM_HS 1;
BA_ "D27_N36" BU_ ECM_HS 1;
BA_ "D28_N22" BU_ ECM_HS 1;
BA_ "DAA_L04_FastRate" BU_ ECM_HS 1;
BA_ "D10_N22" BU_ ECM_HS 1;
BA_ "D3B_N12" BU_ ECM_HS 1;
BA_ "DAA_L02_SlowRate" BU_ ECM_HS 1;
BA_ "DAE_N78" BU_ ECM_HS 1;
BA_ "D27_N22" BU_ ECM_HS 1;
BA_ "D27_L02_SndKey" BU_ ECM_HS 1;
BA_ "D2C_N12" BU_ ECM_HS 1;
BA_ "D27_L01_ReqSeed" BU_ ECM_HS 1;
BA_ "D36_N89" BU_ ECM_HS 1;
BA_ "D3B_N78" BU_ ECM_HS 1;
BA_ "DAA_FRdDPID" BU_ ECM_HS 1;
BA_ "D12_N78" BU_ ECM_HS 1;
BA_ "DAE_FDevCtrl" BU_ ECM_HS 1;
BA_ "DA9_L82_SndChgDTC" BU_ ECM_HS 1;
BA_ "D10_N78" BU_ ECM_HS 1;
BA_ "D27_N37" BU_ ECM_HS 1;
BA_ "D27_L03_CtrlReqSeed" BU_ ECM_HS 1;
BA_ "D04_N78" BU_ ECM_HS 1;
BA_ "DAE_N31" BU_ ECM_HS 1;
BA_ "D3B_N31" BU_ ECM_HS 1;
BA_ "D34_N78" BU_ ECM_HS 1;
BA_ "D36_N78" BU_ ECM_HS 1;
BA_ "D23_N31" BU_ ECM_HS 1;
BA_ "DAA_N31" BU_ ECM_HS 1;
BA_ "VNECUAllNodes" BU_ ECM_HS 4;
BA_ "DAE_N12" BU_ ECM_HS 1;
BA_ "D3E_N12" BU_ ECM_HS 1;
BA_ "DAA_N12" BU_ ECM_HS 1;
BA_ "D28_N12" BU_ ECM_HS 1;
BA_ "ECU_Id" BU_ ECM_HS 224;
BA_ "D36_N83" BU_ ECM_HS 1;
BA_ "D1A_N78" BU_ ECM_HS 1;
BA_ "D27_L04_DevCtrlSeedKey" BU_ ECM_HS 1;
BA_ "D2C_FDynMsg" BU_ ECM_HS 1;
BA_ "DA2_N78" BU_ ECM_HS 1;
BA_ "D20_N12" BU_ ECM_HS 1;
BA_ "DA9_N12" BU_ ECM_HS 1;
BA_ "DA9_N31" BU_ ECM_HS 1;
BA_ "DA5_L03_EnabProgMode" BU_ ECM_HS 1;
BA_ "D23_N12" BU_ ECM_HS 1;
BA_ "D23_N78" BU_ ECM_HS 1;
BA_ "DA5_L01_ReqProgMode" BU_ ECM_HS 1;
BA_ "VNECUSLHS_VNReq" BU_ ECM_HS 4;
BA_ "D12_N31" BU_ ECM_HS 1;
BA_ "DA5_N12" BU_ ECM_HS 1;
BA_ "D27_FSecAcc" BU_ ECM_HS 1;
BA_ "D36_N12" BU_ ECM_HS 1;
BA_ "DA9_L80_RdStatDTCbyNum" BU_ ECM_HS 1;
BA_ "DA5_N78" BU_ ECM_HS 1;
BA_ "D1A_N31" BU_ ECM_HS 1;
BA_ "DAA_L00_StopSnd" BU_ ECM_HS 1;
BA_ "D36_N85" BU_ ECM_HS 1;
BA_ "DA9_L81_RdStatDTCbyMsk" BU_ ECM_HS 1;
BA_ "D10_L03_DTCsDurDevCtrl" BU_ ECM_HS 1;
BA_ "D04_ReqType" BU_ ECM_HS 0;
BA_ "D1A_N22" BU_ ECM_HS 1;
BA_ "D12_N12" BU_ ECM_HS 1;
BA_ "D12_L01_RdFRcdData" BU_ ECM_HS 1;
BA_ "D34_N12" BU_ ECM_HS 1;
BA_ "D04_N12" BU_ ECM_HS 1;
BA_ "DAA_L03_MedRate" BU_ ECM_HS 1;
BA_ "D36_N22" BU_ ECM_HS 1;
BA_ "D36_L80_DwnldExec" BU_ ECM_HS 1;
BA_ "D04_N22" BU_ ECM_HS 1;
BA_ "D3B_N22" BU_ ECM_HS 1;
BA_ "DAA_N81" BU_ ECM_HS 1;
BA_ "D36_L00_DownLoad" BU_ ECM_HS 1;
BA_ "SourceId" BU_ ECM_HS 17;
BA_ "D2C_N31" BU_ ECM_HS 1;
BA_ "DA2_N12" BU_ ECM_HS 1;
BA_ "D10_N12" BU_ ECM_HS 1;
BA_ "Prio" BO_ 844 0;
BA_ "GenMsgSendType" BO_ 844 0;
BA_ "GenMsgCycleTime" BO_ 844 50;
BA_ "MessageSubnet" BO_ 844 2;
BA_ "VNSigAllNodes" SG_ 844 IMUProtYawRtM 1;
BA_ "SignalLongName" SG_ 844 IMUProtYawRtM "Inertial Measurement Unit Protected Yaw Rate Mask";
BA_ "SignalType" SG_ 844 IMUProtYawRtM "ENM";
BA_ "VNSigAllNodes" SG_ 844 IMUProtYawRt 1;
BA_ "SignalLongName" SG_ 844 IMUProtYawRt "Inertial Measurement Unit Protected Yaw Rate";
BA_ "SignalType" SG_ 844 IMUProtYawRt "SNM";
BA_ "VNSigAllNodes" SG_ 844 IMUProtLonAccM 1;
BA_ "SignalLongName" SG_ 844 IMUProtLonAccM "Inertial Measurement Unit Protected Longitudinal Acceleration Mask";
BA_ "SignalType" SG_ 844 IMUProtLonAccM "ENM";
BA_ "VNSigAllNodes" SG_ 844 IMUProtLonAcc 1;
BA_ "SignalLongName" SG_ 844 IMUProtLonAcc "Inertial Measurement Unit Protected Longitudinal Acceleration";
BA_ "SignalType" SG_ 844 IMUProtLonAcc "SNM";
BA_ "VNSigAllNodes" SG_ 844 IMUProtLatAccM 1;
BA_ "SignalLongName" SG_ 844 IMUProtLatAccM "Inertial Measurement Unit Protected Lateral Acceleration Mask";
BA_ "SignalType" SG_ 844 IMUProtLatAccM "ENM";
BA_ "VNSigAllNodes" SG_ 844 IMUProtLatAcc 1;
BA_ "SignalLongName" SG_ 844 IMUProtLatAcc "Inertial Measurement Unit Protected Lateral Acceleration";
BA_ "SignalType" SG_ 844 IMUProtLatAcc "SNM";
BA_ "VNSigAllNodes" SG_ 844 IMUProtChksum 1;
BA_ "SignalLongName" SG_ 844 IMUProtChksum "Inertial Measurement Unit Protected Checksum";
BA_ "SignalType" SG_ 844 IMUProtChksum "UNM";
BA_ "VNSigAllNodes" SG_ 844 IMUProtARC 1;
BA_ "SignalLongName" SG_ 844 IMUProtARC "Inertial Measurement Unit Protected Alive Rolling Count";
BA_ "SignalType" SG_ 844 IMUProtARC "UNM";
BA_ "Prio" BO_ 308 0;
BA_ "GenMsgSendType" BO_ 308 0;
BA_ "GenMsgCycleTime" BO_ 308 1000;
BA_ "MessageSubnet" BO_ 308 2;
BA_ "VNSigAllNodes" SG_ 308 PFAS_SrvPedAlrtIO 1;
BA_ "SignalLongName" SG_ 308 PFAS_SrvPedAlrtIO "Pedestrian Friendly Alert Status : Service Pedestrian Friendly Alert Indication On";
BA_ "SignalType" SG_ 308 PFAS_SrvPedAlrtIO "BLN";
BA_ "VNSigAllNodes" SG_ 308 PFAS_PFASysStat 1;
BA_ "SignalLongName" SG_ 308 PFAS_PFASysStat "Pedestrian Friendly Alert Status : Pedestrian Friendly Alert System Status";
BA_ "SignalType" SG_ 308 PFAS_PFASysStat "ENM";
BA_ "VNSigAllNodes" SG_ 308 PFAS_PFASndVolCtrl 1;
BA_ "SignalLongName" SG_ 308 PFAS_PFASndVolCtrl "Pedestrian Friendly Alert Status : Pedestrian Friendly Alert Sound Volume Control";
BA_ "SignalType" SG_ 308 PFAS_PFASndVolCtrl "UNM";
BA_ "VNSigAllNodes" SG_ 308 PFAS_PFASndGenEn 1;
BA_ "SignalLongName" SG_ 308 PFAS_PFASndGenEn "Pedestrian Friendly Alert Status : Pedestrian Friendly Alert Sound Generation Enable";
BA_ "SignalType" SG_ 308 PFAS_PFASndGenEn "BLN";
BA_ "VNSigAllNodes" SG_ 308 PFAS_PFARevSnd 1;
BA_ "SignalLongName" SG_ 308 PFAS_PFARevSnd "Pedestrian Friendly Alert Status : Pedestrian Friendly Alert Reverse Sound";
BA_ "SignalType" SG_ 308 PFAS_PFARevSnd "ENM";
BA_ "VNSigAllNodes" SG_ 308 PFAS_PFAFwdSnd 1;
BA_ "SignalLongName" SG_ 308 PFAS_PFAFwdSnd "Pedestrian Friendly Alert Status : Pedestrian Friendly Alert Forward Sound";
BA_ "SignalType" SG_ 308 PFAS_PFAFwdSnd "ENM";
BA_ "VNSigAllNodes" SG_ 308 PFAS_PFACrsOvrSpd 1;
BA_ "SignalLongName" SG_ 308 PFAS_PFACrsOvrSpd "Pedestrian Friendly Alert Status : Pedestrian Friendly Alert Crossover Speed";
BA_ "SignalType" SG_ 308 PFAS_PFACrsOvrSpd "UNM";
BA_ "VNSigAllNodes" SG_ 308 PedFrndlyAlrtCsSetAvl 1;
BA_ "SignalLongName" SG_ 308 PedFrndlyAlrtCsSetAvl "Pedestrian Friendly Alert Customization Setting Available";
BA_ "SignalType" SG_ 308 PedFrndlyAlrtCsSetAvl "BLN";
BA_ "VNSigAllNodes" SG_ 308 PedFrndlyAlrtCsCrStVal 1;
BA_ "SignalLongName" SG_ 308 PedFrndlyAlrtCsCrStVal "Pedestrian Friendly Alert Customization Current Setting Value";
BA_ "SignalType" SG_ 308 PedFrndlyAlrtCsCrStVal "ENM";
BA_ "Prio" BO_ 806 0;
BA_ "GenMsgSendType" BO_ 806 0;
BA_ "GenMsgCycleTime" BO_ 806 500;
BA_ "MessageSubnet" BO_ 806 2;
BA_ "VNSigAllNodes" SG_ 806 DCCnvStblznErrIO 1;
BA_ "SignalLongName" SG_ 806 DCCnvStblznErrIO "DC Converter Stabilization Error Indication On";
BA_ "SignalType" SG_ 806 DCCnvStblznErrIO "BLN";
BA_ "Prio" BO_ 426 0;
BA_ "GenMsgSendType" BO_ 426 0;
BA_ "GenMsgCycleTime" BO_ 426 25;
BA_ "MessageSubnet" BO_ 426 2;
BA_ "VNSigAllNodes" SG_ 426 EngPrdctStdyStTorq 1;
BA_ "SignalLongName" SG_ 426 EngPrdctStdyStTorq "Engine Predicted Steady State Torque";
BA_ "SignalType" SG_ 426 EngPrdctStdyStTorq "UNM";
BA_ "VNSigAllNodes" SG_ 426 EngPrdctStdyStTorqV 1;
BA_ "SignalLongName" SG_ 426 EngPrdctStdyStTorqV "Engine Predicted Steady State Torque Validity";
BA_ "SignalType" SG_ 426 EngPrdctStdyStTorqV "ENM";
BA_ "VNSigAllNodes" SG_ 426 CrnkShftTrqMinOffCapV 1;
BA_ "SignalLongName" SG_ 426 CrnkShftTrqMinOffCapV "Crankshaft Torque Minimum Off Capacity Validity";
BA_ "SignalType" SG_ 426 CrnkShftTrqMinOffCapV "ENM";
BA_ "VNSigAllNodes" SG_ 426 CrnkShftTrqMinOffCap 1;
BA_ "SignalLongName" SG_ 426 CrnkShftTrqMinOffCap "Crankshaft Torque Minimum Off Capacity";
BA_ "SignalType" SG_ 426 CrnkShftTrqMinOffCap "UNM";
BA_ "VNSigAllNodes" SG_ 426 CrksftTqMinRunImCapV 1;
BA_ "SignalLongName" SG_ 426 CrksftTqMinRunImCapV "Crankshaft Torque Minimum Run Immediate Capacity Validity";
BA_ "SignalType" SG_ 426 CrksftTqMinRunImCapV "ENM";
BA_ "VNSigAllNodes" SG_ 426 CrksftTqMinRunImCap 1;
BA_ "SignalLongName" SG_ 426 CrksftTqMinRunImCap "Crankshaft Torque Minimum Run Immediate Capacity";
BA_ "SignalType" SG_ 426 CrksftTqMinRunImCap "UNM";
BA_ "Prio" BO_ 1231 0;
BA_ "GenMsgSendType" BO_ 1231 0;
BA_ "GenMsgCycleTime" BO_ 1231 1000;
BA_ "MessageSubnet" BO_ 1231 2;
BA_ "VNSigAllNodes" SG_ 1231 DslExhFluidDistTIndcmt 1;
BA_ "SignalLongName" SG_ 1231 DslExhFluidDistTIndcmt "Diesel Exhaust Fluid Distance to Inducement";
BA_ "SignalType" SG_ 1231 DslExhFluidDistTIndcmt "UNM";
BA_ "VNSigAllNodes" SG_ 1231 DslExhFluidLvlPrcntV 1;
BA_ "SignalLongName" SG_ 1231 DslExhFluidLvlPrcntV "Diesel Exhaust Fluid Level Percent Validity";
BA_ "SignalType" SG_ 1231 DslExhFluidLvlPrcntV "ENM";
BA_ "VNSigAllNodes" SG_ 1231 DslExhFluidLvlPrcnt 1;
BA_ "SignalLongName" SG_ 1231 DslExhFluidLvlPrcnt "Diesel Exhaust Fluid Level Percent";
BA_ "SignalType" SG_ 1231 DslExhFluidLvlPrcnt "UNM";
BA_ "Prio" BO_ 963 0;
BA_ "GenMsgSendType" BO_ 963 0;
BA_ "GenMsgCycleTime" BO_ 963 100;
BA_ "MessageSubnet" BO_ 963 2;
BA_ "VNSigAllNodes" SG_ 963 CltTmpCntlMdEmRMAct 1;
BA_ "SignalLongName" SG_ 963 CltTmpCntlMdEmRMAct "Coolant Temperature Control Module Emissions Related Malfunction Active";
BA_ "SignalType" SG_ 963 CltTmpCntlMdEmRMAct "BLN";
BA_ "VNSigAllNodes" SG_ 963 CTCMERDTC_SysDes 1;
BA_ "SignalLongName" SG_ 963 CTCMERDTC_SysDes "Coolant Temperature Control Module Emissions Related DTC : System Designator";
BA_ "SignalType" SG_ 963 CTCMERDTC_SysDes "ENM";
BA_ "VNSigAllNodes" SG_ 963 CTCMERDTC_CdNum 1;
BA_ "PacketOrder" SG_ 963 CTCMERDTC_CdNum 1;
BA_ "SignalLongName" SG_ 963 CTCMERDTC_CdNum "Coolant Temperature Control Module Emissions Related DTC : Code Number";
BA_ "SignalType" SG_ 963 CTCMERDTC_CdNum "UNM";
BA_ "Prio" BO_ 955 0;
BA_ "GenMsgSendType" BO_ 955 0;
BA_ "GenMsgCycleTime" BO_ 955 100;
BA_ "MessageSubnet" BO_ 955 2;
BA_ "VNSigAllNodes" SG_ 955 RHCS_RdctHtrCCurrV 1;
BA_ "SignalLongName" SG_ 955 RHCS_RdctHtrCCurrV "Reductant Heater Circuits Status : Reductant Heater C Current Validity";
BA_ "SignalType" SG_ 955 RHCS_RdctHtrCCurrV "ENM";
BA_ "VNSigAllNodes" SG_ 955 RHCS_RdctHtrBCurrV 1;
BA_ "PacketOrder" SG_ 955 RHCS_RdctHtrBCurrV 2;
BA_ "SignalLongName" SG_ 955 RHCS_RdctHtrBCurrV "Reductant Heater Circuits Status : Reductant Heater B Current Validity";
BA_ "SignalType" SG_ 955 RHCS_RdctHtrBCurrV "ENM";
BA_ "VNSigAllNodes" SG_ 955 RHCS_RdctHtrACurrV 1;
BA_ "PacketOrder" SG_ 955 RHCS_RdctHtrACurrV 1;
BA_ "SignalLongName" SG_ 955 RHCS_RdctHtrACurrV "Reductant Heater Circuits Status : Reductant Heater A Current Validity";
BA_ "SignalType" SG_ 955 RHCS_RdctHtrACurrV "ENM";
BA_ "VNSigAllNodes" SG_ 955 RdctHtrCrntFdbckRC 1;
BA_ "SignalLongName" SG_ 955 RdctHtrCrntFdbckRC "Reductant Heaters Current Feedback Alive Rolling Count";
BA_ "SignalType" SG_ 955 RdctHtrCrntFdbckRC "UNM";
BA_ "VNSigAllNodes" SG_ 955 RdctHtrCctStatPV 1;
BA_ "SignalLongName" SG_ 955 RdctHtrCctStatPV "Reductant Heater Circuits Status Protection Value";
BA_ "SignalType" SG_ 955 RdctHtrCctStatPV "UNM";
BA_ "VNSigAllNodes" SG_ 955 RdctHtrCCrntFdbckPVa 1;
BA_ "SignalLongName" SG_ 955 RdctHtrCCrntFdbckPVa "Reductant Heater C Current Feedback Protection Value";
BA_ "SignalType" SG_ 955 RdctHtrCCrntFdbckPVa "UNM";
BA_ "VNSigAllNodes" SG_ 955 RdctHtrBCrntFdbckPVa 1;
BA_ "SignalLongName" SG_ 955 RdctHtrBCrntFdbckPVa "Reductant Heater B Current Feedback Protection Value";
BA_ "SignalType" SG_ 955 RdctHtrBCrntFdbckPVa "UNM";
BA_ "VNSigAllNodes" SG_ 955 RdctHtrACrntFdbckPVa 1;
BA_ "SignalLongName" SG_ 955 RdctHtrACrntFdbckPVa "Reductant Heater A Current Feedback Protection Value";
BA_ "SignalType" SG_ 955 RdctHtrACrntFdbckPVa "UNM";
BA_ "VNSigAllNodes" SG_ 955 RdctHtrCCrntFdbck 1;
BA_ "SignalLongName" SG_ 955 RdctHtrCCrntFdbck "Reductant Heater C Current Feedback";
BA_ "SignalType" SG_ 955 RdctHtrCCrntFdbck "UNM";
BA_ "VNSigAllNodes" SG_ 955 RdctHtrBCrntFdbck 1;
BA_ "SignalLongName" SG_ 955 RdctHtrBCrntFdbck "Reductant Heater B Current Feedback";
BA_ "SignalType" SG_ 955 RdctHtrBCrntFdbck "UNM";
BA_ "VNSigAllNodes" SG_ 955 RdctHtrACrntFdbck 1;
BA_ "SignalLongName" SG_ 955 RdctHtrACrntFdbck "Reductant Heater A Current Feedback";
BA_ "SignalType" SG_ 955 RdctHtrACrntFdbck "UNM";
BA_ "Prio" BO_ 208 0;
BA_ "GenMsgSendType" BO_ 208 0;
BA_ "GenMsgCycleTime" BO_ 208 100;
BA_ "MessageSubnet" BO_ 208 2;
BA_ "VNSigAllNodes" SG_ 208 WhlSlipRRWhl 1;
BA_ "SignalLongName" SG_ 208 WhlSlipRRWhl "Wheel Slip Right Rear Wheel";
BA_ "GenSigStartValue" SG_ 208 WhlSlipRRWhl 32768;
BA_ "SignalType" SG_ 208 WhlSlipRRWhl "UNM";
BA_ "VNSigAllNodes" SG_ 208 WhlSlipLRWhl 1;
BA_ "SignalLongName" SG_ 208 WhlSlipLRWhl "Wheel Slip Left Rear Wheel";
BA_ "GenSigStartValue" SG_ 208 WhlSlipLRWhl 32768;
BA_ "SignalType" SG_ 208 WhlSlipLRWhl "UNM";
BA_ "VNSigAllNodes" SG_ 208 WhlSlipRFWhl 1;
BA_ "SignalLongName" SG_ 208 WhlSlipRFWhl "Wheel Slip Right Front Wheel";
BA_ "GenSigStartValue" SG_ 208 WhlSlipRFWhl 32768;
BA_ "SignalType" SG_ 208 WhlSlipRFWhl "UNM";
BA_ "VNSigAllNodes" SG_ 208 WhlSlipLFWhl 1;
BA_ "SignalLongName" SG_ 208 WhlSlipLFWhl "Wheel Slip Left Front Wheel";
BA_ "GenSigStartValue" SG_ 208 WhlSlipLFWhl 32768;
BA_ "SignalType" SG_ 208 WhlSlipLFWhl "UNM";
BA_ "DiagResponse" BO_ 2034 1;
BA_ "Prio" BO_ 2034 0;
BA_ "MessageSubnet" BO_ 2034 2;
BA_ "VNSigAllNodes" SG_ 2034 DgnInf 1;
BA_ "VNSigSLHSSharedDiagnostic" SG_ 2034 DgnInf 1;
BA_ "SignalLongName" SG_ 2034 DgnInf "Diagnostic Information";
BA_ "SignalType" SG_ 2034 DgnInf "UNM";
BA_ "DiagRequest" BO_ 2032 1;
BA_ "Prio" BO_ 2032 0;
BA_ "MessageSubnet" BO_ 2032 2;
BA_ "VNSigAllNodes" SG_ 2032 DgnInf 1;
BA_ "VNSigSLHSSharedDiagnostic" SG_ 2032 DgnInf 1;
BA_ "SignalLongName" SG_ 2032 DgnInf "Diagnostic Information";
BA_ "SignalType" SG_ 2032 DgnInf "UNM";
BA_ "Prio" BO_ 563 0;
BA_ "GenMsgSendType" BO_ 563 0;
BA_ "GenMsgCycleTime" BO_ 563 2000;
BA_ "MessageSubnet" BO_ 563 2;
BA_ "VNSigAllNodes" SG_ 563 SPMCA_SusPrfMd6Avl 1;
BA_ "SignalLongName" SG_ 563 SPMCA_SusPrfMd6Avl "Suspension Performance Mode Customization Available : Suspension Performance Mode 6 Available";
BA_ "SignalType" SG_ 563 SPMCA_SusPrfMd6Avl "BLN";
BA_ "VNSigAllNodes" SG_ 563 SPMCA_SusPrfMd5Avl 1;
BA_ "PacketOrder" SG_ 563 SPMCA_SusPrfMd5Avl 6;
BA_ "SignalLongName" SG_ 563 SPMCA_SusPrfMd5Avl "Suspension Performance Mode Customization Available : Suspension Performance Mode 5 Available";
BA_ "SignalType" SG_ 563 SPMCA_SusPrfMd5Avl "BLN";
BA_ "VNSigAllNodes" SG_ 563 SPMCA_SusPrfMd4Avl 1;
BA_ "PacketOrder" SG_ 563 SPMCA_SusPrfMd4Avl 5;
BA_ "SignalLongName" SG_ 563 SPMCA_SusPrfMd4Avl "Suspension Performance Mode Customization Available : Suspension Performance Mode 4 Available";
BA_ "SignalType" SG_ 563 SPMCA_SusPrfMd4Avl "BLN";
BA_ "VNSigAllNodes" SG_ 563 SPMCA_SusPrfMd3Avl 1;
BA_ "PacketOrder" SG_ 563 SPMCA_SusPrfMd3Avl 4;
BA_ "SignalLongName" SG_ 563 SPMCA_SusPrfMd3Avl "Suspension Performance Mode Customization Available : Suspension Performance Mode 3 Available";
BA_ "SignalType" SG_ 563 SPMCA_SusPrfMd3Avl "BLN";
BA_ "VNSigAllNodes" SG_ 563 SPMCA_SusPrfMd2Avl 1;
BA_ "PacketOrder" SG_ 563 SPMCA_SusPrfMd2Avl 3;
BA_ "SignalLongName" SG_ 563 SPMCA_SusPrfMd2Avl "Suspension Performance Mode Customization Available : Suspension Performance Mode 2 Available";
BA_ "SignalType" SG_ 563 SPMCA_SusPrfMd2Avl "BLN";
BA_ "VNSigAllNodes" SG_ 563 SPMCA_SusPrfMd1Avl 1;
BA_ "PacketOrder" SG_ 563 SPMCA_SusPrfMd1Avl 2;
BA_ "SignalLongName" SG_ 563 SPMCA_SusPrfMd1Avl "Suspension Performance Mode Customization Available : Suspension Performance Mode 1 Available";
BA_ "SignalType" SG_ 563 SPMCA_SusPrfMd1Avl "BLN";
BA_ "VNSigAllNodes" SG_ 563 SPMCA_StrPrfMd6Avl 1;
BA_ "PacketOrder" SG_ 563 SPMCA_StrPrfMd6Avl 1;
BA_ "SignalLongName" SG_ 563 SPMCA_StrPrfMd6Avl "Steering Performance Mode Customization Available : Steering Performance Mode 6 Available";
BA_ "SignalType" SG_ 563 SPMCA_StrPrfMd6Avl "BLN";
BA_ "VNSigAllNodes" SG_ 563 SPMCA_StrPrfMd5Avl 1;
BA_ "PacketOrder" SG_ 563 SPMCA_StrPrfMd5Avl 6;
BA_ "SignalLongName" SG_ 563 SPMCA_StrPrfMd5Avl "Steering Performance Mode Customization Available : Steering Performance Mode 5 Available";
BA_ "SignalType" SG_ 563 SPMCA_StrPrfMd5Avl "BLN";
BA_ "VNSigAllNodes" SG_ 563 SPMCA_StrPrfMd4Avl 1;
BA_ "PacketOrder" SG_ 563 SPMCA_StrPrfMd4Avl 5;
BA_ "SignalLongName" SG_ 563 SPMCA_StrPrfMd4Avl "Steering Performance Mode Customization Available : Steering Performance Mode 4 Available";
BA_ "SignalType" SG_ 563 SPMCA_StrPrfMd4Avl "BLN";
BA_ "VNSigAllNodes" SG_ 563 SPMCA_StrPrfMd3Avl 1;
BA_ "PacketOrder" SG_ 563 SPMCA_StrPrfMd3Avl 4;
BA_ "SignalLongName" SG_ 563 SPMCA_StrPrfMd3Avl "Steering Performance Mode Customization Available : Steering Performance Mode 3 Available";
BA_ "SignalType" SG_ 563 SPMCA_StrPrfMd3Avl "BLN";
BA_ "VNSigAllNodes" SG_ 563 SPMCA_StrPrfMd2Avl 1;
BA_ "PacketOrder" SG_ 563 SPMCA_StrPrfMd2Avl 3;
BA_ "SignalLongName" SG_ 563 SPMCA_StrPrfMd2Avl "Steering Performance Mode Customization Available : Steering Performance Mode 2 Available";
BA_ "SignalType" SG_ 563 SPMCA_StrPrfMd2Avl "BLN";
BA_ "VNSigAllNodes" SG_ 563 SPMCA_StrPrfMd1Avl 1;
BA_ "PacketOrder" SG_ 563 SPMCA_StrPrfMd1Avl 2;
BA_ "SignalLongName" SG_ 563 SPMCA_StrPrfMd1Avl "Steering Performance Mode Customization Available : Steering Performance Mode 1 Available";
BA_ "SignalType" SG_ 563 SPMCA_StrPrfMd1Avl "BLN";
BA_ "VNSigAllNodes" SG_ 563 SPMCA_SndPrfMd6Avl 1;
BA_ "PacketOrder" SG_ 563 SPMCA_SndPrfMd6Avl 1;
BA_ "SignalLongName" SG_ 563 SPMCA_SndPrfMd6Avl "Sound Performance Mode Customization Available : Sound Performance Mode 6 Available";
BA_ "SignalType" SG_ 563 SPMCA_SndPrfMd6Avl "BLN";
BA_ "VNSigAllNodes" SG_ 563 SPMCA_SndPrfMd5Avl 1;
BA_ "PacketOrder" SG_ 563 SPMCA_SndPrfMd5Avl 6;
BA_ "SignalLongName" SG_ 563 SPMCA_SndPrfMd5Avl "Sound Performance Mode Customization Available : Sound Performance Mode 5 Available";
BA_ "SignalType" SG_ 563 SPMCA_SndPrfMd5Avl "BLN";
BA_ "VNSigAllNodes" SG_ 563 SPMCA_SndPrfMd4Avl 1;
BA_ "PacketOrder" SG_ 563 SPMCA_SndPrfMd4Avl 5;
BA_ "SignalLongName" SG_ 563 SPMCA_SndPrfMd4Avl "Sound Performance Mode Customization Available : Sound Performance Mode 4 Available";
BA_ "SignalType" SG_ 563 SPMCA_SndPrfMd4Avl "BLN";
BA_ "VNSigAllNodes" SG_ 563 SPMCA_SndPrfMd3Avl 1;
BA_ "PacketOrder" SG_ 563 SPMCA_SndPrfMd3Avl 4;
BA_ "SignalLongName" SG_ 563 SPMCA_SndPrfMd3Avl "Sound Performance Mode Customization Available : Sound Performance Mode 3 Available";
BA_ "SignalType" SG_ 563 SPMCA_SndPrfMd3Avl "BLN";
BA_ "VNSigAllNodes" SG_ 563 SPMCA_SndPrfMd2Avl 1;
BA_ "PacketOrder" SG_ 563 SPMCA_SndPrfMd2Avl 3;
BA_ "SignalLongName" SG_ 563 SPMCA_SndPrfMd2Avl "Sound Performance Mode Customization Available : Sound Performance Mode 2 Available";
BA_ "SignalType" SG_ 563 SPMCA_SndPrfMd2Avl "BLN";
BA_ "VNSigAllNodes" SG_ 563 SPMCA_SndPrfMd1Avl 1;
BA_ "PacketOrder" SG_ 563 SPMCA_SndPrfMd1Avl 2;
BA_ "SignalLongName" SG_ 563 SPMCA_SndPrfMd1Avl "Sound Performance Mode Customization Available : Sound Performance Mode 1 Available";
BA_ "SignalType" SG_ 563 SPMCA_SndPrfMd1Avl "BLN";
BA_ "VNSigAllNodes" SG_ 563 DPMCA_DispPrfMd6Avl 1;
BA_ "PacketOrder" SG_ 563 DPMCA_DispPrfMd6Avl 1;
BA_ "SignalLongName" SG_ 563 DPMCA_DispPrfMd6Avl "Display Performance Mode Customization Available : Display Performance Mode 6 Available";
BA_ "SignalType" SG_ 563 DPMCA_DispPrfMd6Avl "BLN";
BA_ "VNSigAllNodes" SG_ 563 DPMCA_DispPrfMd5Avl 1;
BA_ "PacketOrder" SG_ 563 DPMCA_DispPrfMd5Avl 6;
BA_ "SignalLongName" SG_ 563 DPMCA_DispPrfMd5Avl "Display Performance Mode Customization Available : Display Performance Mode 5 Available";
BA_ "SignalType" SG_ 563 DPMCA_DispPrfMd5Avl "BLN";
BA_ "VNSigAllNodes" SG_ 563 DPMCA_DispPrfMd4Avl 1;
BA_ "PacketOrder" SG_ 563 DPMCA_DispPrfMd4Avl 5;
BA_ "SignalLongName" SG_ 563 DPMCA_DispPrfMd4Avl "Display Performance Mode Customization Available : Display Performance Mode 4 Available";
BA_ "SignalType" SG_ 563 DPMCA_DispPrfMd4Avl "BLN";
BA_ "VNSigAllNodes" SG_ 563 DPMCA_DispPrfMd3Avl 1;
BA_ "PacketOrder" SG_ 563 DPMCA_DispPrfMd3Avl 4;
BA_ "SignalLongName" SG_ 563 DPMCA_DispPrfMd3Avl "Display Performance Mode Customization Available : Display Performance Mode 3 Available";
BA_ "SignalType" SG_ 563 DPMCA_DispPrfMd3Avl "BLN";
BA_ "VNSigAllNodes" SG_ 563 DPMCA_DispPrfMd2Avl 1;
BA_ "PacketOrder" SG_ 563 DPMCA_DispPrfMd2Avl 3;
BA_ "SignalLongName" SG_ 563 DPMCA_DispPrfMd2Avl "Display Performance Mode Customization Available : Display Performance Mode 2 Available";
BA_ "SignalType" SG_ 563 DPMCA_DispPrfMd2Avl "BLN";
BA_ "VNSigAllNodes" SG_ 563 DPMCA_DispPrfMd1Avl 1;
BA_ "PacketOrder" SG_ 563 DPMCA_DispPrfMd1Avl 2;
BA_ "SignalLongName" SG_ 563 DPMCA_DispPrfMd1Avl "Display Performance Mode Customization Available : Display Performance Mode 1 Available";
BA_ "SignalType" SG_ 563 DPMCA_DispPrfMd1Avl "BLN";
BA_ "VNSigAllNodes" SG_ 563 DPMCA_DrvlPrfMd6Avl 1;
BA_ "PacketOrder" SG_ 563 DPMCA_DrvlPrfMd6Avl 1;
BA_ "SignalLongName" SG_ 563 DPMCA_DrvlPrfMd6Avl "Driveline Performance Mode Customization Available : Driveline Performance Mode 6 Available";
BA_ "SignalType" SG_ 563 DPMCA_DrvlPrfMd6Avl "BLN";
BA_ "VNSigAllNodes" SG_ 563 DPMCA_DrvlPrfMd5Avl 1;
BA_ "PacketOrder" SG_ 563 DPMCA_DrvlPrfMd5Avl 6;
BA_ "SignalLongName" SG_ 563 DPMCA_DrvlPrfMd5Avl "Driveline Performance Mode Customization Available : Driveline Performance Mode 5 Available";
BA_ "SignalType" SG_ 563 DPMCA_DrvlPrfMd5Avl "BLN";
BA_ "VNSigAllNodes" SG_ 563 DPMCA_DrvlPrfMd4Avl 1;
BA_ "PacketOrder" SG_ 563 DPMCA_DrvlPrfMd4Avl 5;
BA_ "SignalLongName" SG_ 563 DPMCA_DrvlPrfMd4Avl "Driveline Performance Mode Customization Available : Driveline Performance Mode 4 Available";
BA_ "SignalType" SG_ 563 DPMCA_DrvlPrfMd4Avl "BLN";
BA_ "VNSigAllNodes" SG_ 563 DPMCA_DrvlPrfMd3Avl 1;
BA_ "PacketOrder" SG_ 563 DPMCA_DrvlPrfMd3Avl 4;
BA_ "SignalLongName" SG_ 563 DPMCA_DrvlPrfMd3Avl "Driveline Performance Mode Customization Available : Driveline Performance Mode 3 Available";
BA_ "SignalType" SG_ 563 DPMCA_DrvlPrfMd3Avl "BLN";
BA_ "VNSigAllNodes" SG_ 563 DPMCA_DrvlPrfMd2Avl 1;
BA_ "PacketOrder" SG_ 563 DPMCA_DrvlPrfMd2Avl 3;
BA_ "SignalLongName" SG_ 563 DPMCA_DrvlPrfMd2Avl "Driveline Performance Mode Customization Available : Driveline Performance Mode 2 Available";
BA_ "SignalType" SG_ 563 DPMCA_DrvlPrfMd2Avl "BLN";
BA_ "VNSigAllNodes" SG_ 563 DPMCA_DrvlPrfMd1Avl 1;
BA_ "PacketOrder" SG_ 563 DPMCA_DrvlPrfMd1Avl 2;
BA_ "SignalLongName" SG_ 563 DPMCA_DrvlPrfMd1Avl "Driveline Performance Mode Customization Available : Driveline Performance Mode 1 Available";
BA_ "SignalType" SG_ 563 DPMCA_DrvlPrfMd1Avl "BLN";
BA_ "Prio" BO_ 1323 0;
BA_ "GenMsgSendType" BO_ 1323 0;
BA_ "GenMsgCycleTime" BO_ 1323 1000;
BA_ "MessageSubnet" BO_ 1323 2;
BA_ "VNSigAllNodes" SG_ 1323 TireLRTmpV 1;
BA_ "SignalLongName" SG_ 1323 TireLRTmpV "Tire Left Rear Temperature Validity";
BA_ "SignalType" SG_ 1323 TireLRTmpV "ENM";
BA_ "VNSigAllNodes" SG_ 1323 TireLRTmp 1;
BA_ "SignalLongName" SG_ 1323 TireLRTmp "Tire Left Rear Temperature";
BA_ "SignalType" SG_ 1323 TireLRTmp "UNM";
BA_ "VNSigAllNodes" SG_ 1323 TireLFTmpV 1;
BA_ "SignalLongName" SG_ 1323 TireLFTmpV "Tire Left Front Temperature Validity";
BA_ "SignalType" SG_ 1323 TireLFTmpV "ENM";
BA_ "VNSigAllNodes" SG_ 1323 TireLFTmp 1;
BA_ "SignalLongName" SG_ 1323 TireLFTmp "Tire Left Front Temperature";
BA_ "SignalType" SG_ 1323 TireLFTmp "UNM";
BA_ "VNSigAllNodes" SG_ 1323 TireRRTmpV 1;
BA_ "SignalLongName" SG_ 1323 TireRRTmpV "Tire Right Rear Temperature Validity";
BA_ "SignalType" SG_ 1323 TireRRTmpV "ENM";
BA_ "VNSigAllNodes" SG_ 1323 TireRRTmp 1;
BA_ "SignalLongName" SG_ 1323 TireRRTmp "Tire Right Rear Temperature";
BA_ "SignalType" SG_ 1323 TireRRTmp "UNM";
BA_ "VNSigAllNodes" SG_ 1323 TireRFTmpV 1;
BA_ "SignalLongName" SG_ 1323 TireRFTmpV "Tire Right Front Temperature Validity";
BA_ "SignalType" SG_ 1323 TireRFTmpV "ENM";
BA_ "VNSigAllNodes" SG_ 1323 TireRFTmp 1;
BA_ "SignalLongName" SG_ 1323 TireRFTmp "Tire Right Front Temperature";
BA_ "SignalType" SG_ 1323 TireRFTmp "UNM";
BA_ "Prio" BO_ 1247 0;
BA_ "GenMsgSendType" BO_ 1247 0;
BA_ "GenMsgCycleTime" BO_ 1247 500;
BA_ "MessageSubnet" BO_ 1247 2;
BA_ "VNSigAllNodes" SG_ 1247 RrPTCoolFanStatV 1;
BA_ "SignalLongName" SG_ 1247 RrPTCoolFanStatV "Rear Powertrain Cooling Fan Status Validity";
BA_ "SignalType" SG_ 1247 RrPTCoolFanStatV "ENM";
BA_ "VNSigAllNodes" SG_ 1247 RrPTCoolFanStat 1;
BA_ "SignalLongName" SG_ 1247 RrPTCoolFanStat "Rear Powertrain Cooling Fan Status";
BA_ "SignalType" SG_ 1247 RrPTCoolFanStat "ENM";
BA_ "VNSigAllNodes" SG_ 1247 RrPTCoolFanSpPctCmd 1;
BA_ "SignalLongName" SG_ 1247 RrPTCoolFanSpPctCmd "Rear Powertrain Cooling Fan Speed Percent Commanded";
BA_ "SignalType" SG_ 1247 RrPTCoolFanSpPctCmd "UNM";
BA_ "Prio" BO_ 873 0;
BA_ "GenMsgSendType" BO_ 873 0;
BA_ "GenMsgCycleTime" BO_ 873 100;
BA_ "MessageSubnet" BO_ 873 2;
BA_ "VNSigAllNodes" SG_ 873 FrtCmModIntgStat 1;
BA_ "SignalLongName" SG_ 873 FrtCmModIntgStat "Front Camera Module Integrity Status";
BA_ "SignalType" SG_ 873 FrtCmModIntgStat "ENM";
BA_ "VNSigAllNodes" SG_ 873 FrtCmModAsmt 1;
BA_ "SignalLongName" SG_ 873 FrtCmModAsmt "Front Camera Module Assessment";
BA_ "SignalType" SG_ 873 FrtCmModAsmt "ENM";
BA_ "VNSigAllNodes" SG_ 873 ACCMR_RptdChlng 1;
BA_ "PacketOrder" SG_ 873 ACCMR_RptdChlng 1;
BA_ "SignalLongName" SG_ 873 ACCMR_RptdChlng "Adaptive Cruise Control Module Response : Repeated Challenge";
BA_ "SignalType" SG_ 873 ACCMR_RptdChlng "UNM";
BA_ "VNSigAllNodes" SG_ 873 ACCMR_Answr 1;
BA_ "PacketOrder" SG_ 873 ACCMR_Answr 2;
BA_ "SignalLongName" SG_ 873 ACCMR_Answr "Adaptive Cruise Control Module Response : Answer";
BA_ "SignalType" SG_ 873 ACCMR_Answr "UNM";
BA_ "VNSigAllNodes" SG_ 873 AdptCrsCtrlModChlng 1;
BA_ "SignalLongName" SG_ 873 AdptCrsCtrlModChlng "Adaptive Cruise Control Module Challenge";
BA_ "SignalType" SG_ 873 AdptCrsCtrlModChlng "UNM";
BA_ "Prio" BO_ 306 0;
BA_ "GenMsgSendType" BO_ 306 0;
BA_ "GenMsgCycleTime" BO_ 306 100;
BA_ "MessageSubnet" BO_ 306 2;
BA_ "VNSigAllNodes" SG_ 306 ClntCrcFlwRtEst 1;
BA_ "SignalLongName" SG_ 306 ClntCrcFlwRtEst "Coolant Circulation Flow Rate Estimated";
BA_ "SignalType" SG_ 306 ClntCrcFlwRtEst "UNM";
BA_ "Prio" BO_ 723 0;
BA_ "GenMsgSendType" BO_ 723 0;
BA_ "GenMsgCycleTime" BO_ 723 50;
BA_ "MessageSubnet" BO_ 723 2;
BA_ "VNSigAllNodes" SG_ 723 PerfTrcEngSpdRqStat 1;
BA_ "SignalLongName" SG_ 723 PerfTrcEngSpdRqStat "Performance Traction Engine Speed Request Status";
BA_ "SignalType" SG_ 723 PerfTrcEngSpdRqStat "ENM";
BA_ "VNSigAllNodes" SG_ 723 PerfTrcEngSpdLmtStat 1;
BA_ "SignalLongName" SG_ 723 PerfTrcEngSpdLmtStat "Performance Traction Engine Speed Limiting Status";
BA_ "SignalType" SG_ 723 PerfTrcEngSpdLmtStat "ENM";
BA_ "VNSigAllNodes" SG_ 723 PerfTrcTrqRqStat 1;
BA_ "SignalLongName" SG_ 723 PerfTrcTrqRqStat "Performance Traction Torque Request Status";
BA_ "SignalType" SG_ 723 PerfTrcTrqRqStat "ENM";
BA_ "VNSigAllNodes" SG_ 723 PerfTrcTrqLmtStat 1;
BA_ "SignalLongName" SG_ 723 PerfTrcTrqLmtStat "Performance Traction Torque Limiting Status";
BA_ "SignalType" SG_ 723 PerfTrcTrqLmtStat "ENM";
BA_ "Prio" BO_ 405 0;
BA_ "GenMsgSendType" BO_ 405 0;
BA_ "GenMsgCycleTime" BO_ 405 12;
BA_ "MessageSubnet" BO_ 405 2;
BA_ "VNSigAllNodes" SG_ 405 EngDistFuelMdDefltd 1;
BA_ "SignalLongName" SG_ 405 EngDistFuelMdDefltd "Engine Distributed Fuel Mode Defaulted";
BA_ "SignalType" SG_ 405 EngDistFuelMdDefltd "BLN";
BA_ "VNSigAllNodes" SG_ 405 EngInjEnbldD 1;
BA_ "SignalLongName" SG_ 405 EngInjEnbldD "Engine Injector Enabled D";
BA_ "SignalType" SG_ 405 EngInjEnbldD "BLN";
BA_ "VNSigAllNodes" SG_ 405 EngInjEnbldC 1;
BA_ "SignalLongName" SG_ 405 EngInjEnbldC "Engine Injector Enabled C";
BA_ "SignalType" SG_ 405 EngInjEnbldC "BLN";
BA_ "VNSigAllNodes" SG_ 405 EngInjEnbldB 1;
BA_ "SignalLongName" SG_ 405 EngInjEnbldB "Engine Injector Enabled B";
BA_ "SignalType" SG_ 405 EngInjEnbldB "BLN";
BA_ "VNSigAllNodes" SG_ 405 EngInjEnbldA 1;
BA_ "SignalLongName" SG_ 405 EngInjEnbldA "Engine Injector Enabled A";
BA_ "SignalType" SG_ 405 EngInjEnbldA "BLN";
BA_ "VNSigAllNodes" SG_ 405 ThrPosV 1;
BA_ "SignalLongName" SG_ 405 ThrPosV "Throttle Position Validity";
BA_ "SignalType" SG_ 405 ThrPosV "ENM";
BA_ "VNSigAllNodes" SG_ 405 ThrPos 1;
BA_ "SignalLongName" SG_ 405 ThrPos "Throttle Position";
BA_ "SignalType" SG_ 405 ThrPos "UNM";
BA_ "VNSigAllNodes" SG_ 405 MassAirFloV 1;
BA_ "SignalLongName" SG_ 405 MassAirFloV "Mass Air Flow Validity";
BA_ "SignalType" SG_ 405 MassAirFloV "ENM";
BA_ "VNSigAllNodes" SG_ 405 MassAirFlo 1;
BA_ "SignalLongName" SG_ 405 MassAirFlo "Mass Air Flow";
BA_ "SignalType" SG_ 405 MassAirFlo "UNM";
BA_ "VNSigAllNodes" SG_ 405 EngManfldAbsPrsERV 1;
BA_ "SignalLongName" SG_ 405 EngManfldAbsPrsERV "Engine Manifold Absolute Pressure Extended Range Validity";
BA_ "SignalType" SG_ 405 EngManfldAbsPrsERV "ENM";
BA_ "VNSigAllNodes" SG_ 405 EngManfldAbsPrsER 1;
BA_ "SignalLongName" SG_ 405 EngManfldAbsPrsER "Engine Manifold Absolute Pressure Extended Range";
BA_ "SignalType" SG_ 405 EngManfldAbsPrsER "UNM";
BA_ "Prio" BO_ 419 0;
BA_ "GenMsgSendType" BO_ 419 0;
BA_ "GenMsgCycleTime" BO_ 419 25;
BA_ "MessageSubnet" BO_ 419 2;
BA_ "VNSigAllNodes" SG_ 419 EngRunng 1;
BA_ "SignalLongName" SG_ 419 EngRunng "Engine Running";
BA_ "SignalType" SG_ 419 EngRunng "BLN";
BA_ "Prio" BO_ 289 0;
BA_ "GenMsgSendType" BO_ 289 0;
BA_ "GenMsgCycleTime" BO_ 289 20;
BA_ "MessageSubnet" BO_ 289 2;
BA_ "VNSigAllNodes" SG_ 289 ARDM_RawData 1;
BA_ "PacketOrder" SG_ 289 ARDM_RawData 1;
BA_ "SignalLongName" SG_ 289 ARDM_RawData "ADASIS Raw Data Multiplexed : Raw Data";
BA_ "SignalType" SG_ 289 ARDM_RawData "UNM";
BA_ "VNSigAllNodes" SG_ 289 ARDM_MsgType 1;
BA_ "PacketOrder" SG_ 289 ARDM_MsgType 1;
BA_ "SignalLongName" SG_ 289 ARDM_MsgType "ADASIS Raw Data Multiplexed : Message Type";
BA_ "SignalType" SG_ 289 ARDM_MsgType "ENM";
BA_ "Prio" BO_ 871 0;
BA_ "GenMsgSendType" BO_ 871 0;
BA_ "GenMsgCycleTime" BO_ 871 100;
BA_ "MessageSubnet" BO_ 871 2;
BA_ "VNSigAllNodes" SG_ 871 ACCModIntgStat 1;
BA_ "SignalLongName" SG_ 871 ACCModIntgStat "Adaptive Cruise Control Module Integrity Status";
BA_ "SignalType" SG_ 871 ACCModIntgStat "ENM";
BA_ "VNSigAllNodes" SG_ 871 AdptCrsCtrlModAsmt 1;
BA_ "SignalLongName" SG_ 871 AdptCrsCtrlModAsmt "Adaptive Cruise Control Module Assessment";
BA_ "SignalType" SG_ 871 AdptCrsCtrlModAsmt "ENM";
BA_ "VNSigAllNodes" SG_ 871 FCMR_RptdChlng 1;
BA_ "PacketOrder" SG_ 871 FCMR_RptdChlng 1;
BA_ "SignalLongName" SG_ 871 FCMR_RptdChlng "Front Camera Module Response : Repeated Challenge";
BA_ "SignalType" SG_ 871 FCMR_RptdChlng "UNM";
BA_ "VNSigAllNodes" SG_ 871 FCMR_Answr 1;
BA_ "PacketOrder" SG_ 871 FCMR_Answr 2;
BA_ "SignalLongName" SG_ 871 FCMR_Answr "Front Camera Module Response : Answer";
BA_ "SignalType" SG_ 871 FCMR_Answr "UNM";
BA_ "VNSigAllNodes" SG_ 871 FrtCmModChlng 1;
BA_ "SignalLongName" SG_ 871 FrtCmModChlng "Front Camera Module Challenge";
BA_ "SignalType" SG_ 871 FrtCmModChlng "UNM";
BA_ "Prio" BO_ 800 0;
BA_ "GenMsgSendType" BO_ 800 0;
BA_ "GenMsgCycleTime" BO_ 800 100;
BA_ "MessageSubnet" BO_ 800 2;
BA_ "VNSigAllNodes" SG_ 800 FCACtrlBrkSysCmdPrtVl 1;
BA_ "SignalLongName" SG_ 800 FCACtrlBrkSysCmdPrtVl "Forward Collision Alert Control Brake System Command Protection Value";
BA_ "SignalType" SG_ 800 FCACtrlBrkSysCmdPrtVl "UNM";
BA_ "VNSigAllNodes" SG_ 800 FCACBSC_CtrlAcc 1;
BA_ "PacketOrder" SG_ 800 FCACBSC_CtrlAcc 2;
BA_ "SignalLongName" SG_ 800 FCACBSC_CtrlAcc "Forward Collision Alert Control Brake System Command : Control Acceleration";
BA_ "SignalType" SG_ 800 FCACBSC_CtrlAcc "SNM";
BA_ "VNSigAllNodes" SG_ 800 FCACBSC_AutBrkRpRt 1;
BA_ "PacketOrder" SG_ 800 FCACBSC_AutBrkRpRt 4;
BA_ "SignalLongName" SG_ 800 FCACBSC_AutBrkRpRt "Forward Collision Alert Control Brake System Command : Automatic Braking Ramp Rate";
BA_ "SignalType" SG_ 800 FCACBSC_AutBrkRpRt "ENM";
BA_ "VNSigAllNodes" SG_ 800 FCACBSC_AutBrkRqTp 1;
BA_ "PacketOrder" SG_ 800 FCACBSC_AutBrkRqTp 2;
BA_ "SignalLongName" SG_ 800 FCACBSC_AutBrkRqTp "Forward Collision Alert Control Brake System Command : Automatic Braking Request Type";
BA_ "SignalType" SG_ 800 FCACBSC_AutBrkRqTp "ENM";
BA_ "VNSigAllNodes" SG_ 800 FCACBSC_AutBrkRqd 1;
BA_ "PacketOrder" SG_ 800 FCACBSC_AutBrkRqd 3;
BA_ "SignalLongName" SG_ 800 FCACBSC_AutBrkRqd "Forward Collision Alert Control Brake System Command : Automatic Braking Requested";
BA_ "SignalType" SG_ 800 FCACBSC_AutBrkRqd "BLN";
BA_ "VNSigAllNodes" SG_ 800 FCACtrlBrkSysCmdRC 1;
BA_ "SignalLongName" SG_ 800 FCACtrlBrkSysCmdRC "Forward Collision Alert Control Brake System Command Rolling Count";
BA_ "SignalType" SG_ 800 FCACtrlBrkSysCmdRC "UNM";
BA_ "Prio" BO_ 388 0;
BA_ "GenMsgSendType" BO_ 388 0;
BA_ "GenMsgCycleTime" BO_ 388 100;
BA_ "MessageSubnet" BO_ 388 2;
BA_ "VNSigAllNodes" SG_ 388 HndsOffStrWhlDtStV 1;
BA_ "SignalLongName" SG_ 388 HndsOffStrWhlDtStV "Hands Off Steering Wheel Detection State Validity";
BA_ "SignalType" SG_ 388 HndsOffStrWhlDtStV "ENM";
BA_ "VNSigAllNodes" SG_ 388 HndsOffStrWhlDtSt 1;
BA_ "SignalLongName" SG_ 388 HndsOffStrWhlDtSt "Hands Off Steering Wheel Detection State";
BA_ "SignalType" SG_ 388 HndsOffStrWhlDtSt "ENM";
BA_ "VNSigAllNodes" SG_ 388 HndsOffStrWhlDtMd 1;
BA_ "SignalLongName" SG_ 388 HndsOffStrWhlDtMd "Hands Off Steering Wheel Detection Mode";
BA_ "SignalType" SG_ 388 HndsOffStrWhlDtMd "ENM";
BA_ "VNSigAllNodes" SG_ 388 LKATrqOvrlDlvdPrtVl 1;
BA_ "SignalLongName" SG_ 388 LKATrqOvrlDlvdPrtVl "Lane Keeping Assist Torque Overlay Delivered Protection Value";
BA_ "SignalType" SG_ 388 LKATrqOvrlDlvdPrtVl "UNM";
BA_ "VNSigAllNodes" SG_ 388 LKATrqOvrlDltTrqDlvd 1;
BA_ "SignalLongName" SG_ 388 LKATrqOvrlDltTrqDlvd "Lane Keeping Assist Torque Overlay Delta Torque Delivered";
BA_ "SignalType" SG_ 388 LKATrqOvrlDltTrqDlvd "SNM";
BA_ "VNSigAllNodes" SG_ 388 LKATrqOvrlDlvdRC 1;
BA_ "SignalLongName" SG_ 388 LKATrqOvrlDlvdRC "Lane Keeping Assist Torque Overlay Delivered Rolling Count";
BA_ "SignalType" SG_ 388 LKATrqOvrlDlvdRC "UNM";
BA_ "VNSigAllNodes" SG_ 388 LKAElPwrStTtlTqDlvd 1;
BA_ "SignalLongName" SG_ 388 LKAElPwrStTtlTqDlvd "Lane Keeping Assist Electrical Power Steering Total Torque Delivered";
BA_ "SignalType" SG_ 388 LKAElPwrStTtlTqDlvd "SNM";
BA_ "VNSigAllNodes" SG_ 388 LKATrqOvrlTrqDStat 1;
BA_ "SignalLongName" SG_ 388 LKATrqOvrlTrqDStat "Lane Keeping Assist Torque Overlay Torque Delivered Status";
BA_ "SignalType" SG_ 388 LKATrqOvrlTrqDStat "ENM";
BA_ "Prio" BO_ 384 0;
BA_ "GenMsgSendType" BO_ 384 0;
BA_ "GenMsgCycleTime" BO_ 384 100;
BA_ "MessageSubnet" BO_ 384 2;
BA_ "VNSigAllNodes" SG_ 384 LKATqOvrDltCmdPrtVl 1;
BA_ "SignalLongName" SG_ 384 LKATqOvrDltCmdPrtVl "Lane Keeping Assist Torque Overlay Delta Command Protection Value";
BA_ "SignalType" SG_ 384 LKATqOvrDltCmdPrtVl "UNM";
BA_ "VNSigAllNodes" SG_ 384 LKATqOvrDltCmdRC 1;
BA_ "SignalLongName" SG_ 384 LKATqOvrDltCmdRC "Lane Keeping Assist Torque Overlay Delta Command Rolling Count";
BA_ "SignalType" SG_ 384 LKATqOvrDltCmdRC "UNM";
BA_ "VNSigAllNodes" SG_ 384 LKATODC_TrqVl 1;
BA_ "PacketOrder" SG_ 384 LKATODC_TrqVl 1;
BA_ "SignalLongName" SG_ 384 LKATODC_TrqVl "Lane Keeping Assist Torque Overlay Delta Command : Torque Value";
BA_ "SignalType" SG_ 384 LKATODC_TrqVl "SNM";
BA_ "VNSigAllNodes" SG_ 384 LKATODC_TrqRqAct 1;
BA_ "PacketOrder" SG_ 384 LKATODC_TrqRqAct 2;
BA_ "SignalLongName" SG_ 384 LKATODC_TrqRqAct "Lane Keeping Assist Torque Overlay Delta Command : Torque Request Active";
BA_ "SignalType" SG_ 384 LKATODC_TrqRqAct "BLN";
BA_ "Prio" BO_ 866 0;
BA_ "GenMsgSendType" BO_ 866 0;
BA_ "GenMsgCycleTime" BO_ 866 50;
BA_ "MessageSubnet" BO_ 866 2;
BA_ "VNSigAllNodes" SG_ 866 ColPrSysHzrdLghtsReq 1;
BA_ "SignalLongName" SG_ 866 ColPrSysHzrdLghtsReq "Collision Preparation System Hazard Lights Request";
BA_ "SignalType" SG_ 866 ColPrSysHzrdLghtsReq "ENM";
BA_ "VNSigAllNodes" SG_ 866 ColPrSysWndwsReq 1;
BA_ "SignalLongName" SG_ 866 ColPrSysWndwsReq "Collision Preparation System Windows Request";
BA_ "SignalType" SG_ 866 ColPrSysWndwsReq "ENM";
BA_ "VNSigAllNodes" SG_ 866 ColPrSysDrsReq 1;
BA_ "SignalLongName" SG_ 866 ColPrSysDrsReq "Collision Preparation System Doors Request";
BA_ "SignalType" SG_ 866 ColPrSysDrsReq "ENM";
BA_ "VNSigAllNodes" SG_ 866 ColPrSysSnrfReq 1;
BA_ "SignalLongName" SG_ 866 ColPrSysSnrfReq "Collision Preparation System Sunroof Request";
BA_ "SignalType" SG_ 866 ColPrSysSnrfReq "ENM";
BA_ "VNSigAllNodes" SG_ 866 CPSInfotmntMtReq 1;
BA_ "SignalLongName" SG_ 866 CPSInfotmntMtReq "Collision Preparation System Infotainment Mute Request";
BA_ "SignalType" SG_ 866 CPSInfotmntMtReq "ENM";
BA_ "VNSigAllNodes" SG_ 866 StBltTgtSetAvl 1;
BA_ "SignalLongName" SG_ 866 StBltTgtSetAvl "Seat Belt Tightening Settings Available";
BA_ "SignalType" SG_ 866 StBltTgtSetAvl "BLN";
BA_ "VNSigAllNodes" SG_ 866 StBltTgtCrtSetVal 1;
BA_ "SignalLongName" SG_ 866 StBltTgtCrtSetVal "Seat Belt Tightening Current Setting Value";
BA_ "SignalType" SG_ 866 StBltTgtCrtSetVal "ENM";
BA_ "VNSigAllNodes" SG_ 866 MotStBltUnblIO 1;
BA_ "SignalLongName" SG_ 866 MotStBltUnblIO "Motorized Seat Belt Unavailable Indication On";
BA_ "SignalType" SG_ 866 MotStBltUnblIO "BLN";
BA_ "VNSigAllNodes" SG_ 866 MotStBltFldIO 1;
BA_ "SignalLongName" SG_ 866 MotStBltFldIO "Motorized Seat Belt Failed Indication On";
BA_ "SignalType" SG_ 866 MotStBltFldIO "BLN";
BA_ "VNSigAllNodes" SG_ 866 RegenBrkAxTrqAch 1;
BA_ "SignalLongName" SG_ 866 RegenBrkAxTrqAch "Regenerative Braking Axle Torque Achieved";
BA_ "SignalType" SG_ 866 RegenBrkAxTrqAch "UNM";
BA_ "Prio" BO_ 951 0;
BA_ "GenMsgSendType" BO_ 951 0;
BA_ "GenMsgCycleTime" BO_ 951 100;
BA_ "MessageSubnet" BO_ 951 2;
BA_ "VNSigAllNodes" SG_ 951 AltFuelLvlPrcnt 1;
BA_ "SignalLongName" SG_ 951 AltFuelLvlPrcnt "Alternative Fuel Level Percent";
BA_ "SignalType" SG_ 951 AltFuelLvlPrcnt "UNM";
BA_ "VNSigAllNodes" SG_ 951 FuelInjCntrlModInjFltAct 1;
BA_ "SignalLongName" SG_ 951 FuelInjCntrlModInjFltAct "Fuel Injector Control Module Injection Fault Active";
BA_ "SignalType" SG_ 951 FuelInjCntrlModInjFltAct "BLN";
BA_ "VNSigAllNodes" SG_ 951 AFRP_RailPrs 1;
BA_ "PacketOrder" SG_ 951 AFRP_RailPrs 2;
BA_ "SignalLongName" SG_ 951 AFRP_RailPrs "Alternative Fuel Rail Pressure : Rail Pressure";
BA_ "SignalType" SG_ 951 AFRP_RailPrs "UNM";
BA_ "VNSigAllNodes" SG_ 951 AFRP_SnsTyp 1;
BA_ "PacketOrder" SG_ 951 AFRP_SnsTyp 1;
BA_ "SignalLongName" SG_ 951 AFRP_SnsTyp "Alternative Fuel Rail Pressure : Sensor Type";
BA_ "SignalType" SG_ 951 AFRP_SnsTyp "ENM";
BA_ "VNSigAllNodes" SG_ 951 FICMDS3_DTCStatus 1;
BA_ "PacketOrder" SG_ 951 FICMDS3_DTCStatus 2;
BA_ "SignalLongName" SG_ 951 FICMDS3_DTCStatus "Fuel Injector Control Module Diagnostic Status 3 : Diagnostic Trouble Code Status";
BA_ "SignalType" SG_ 951 FICMDS3_DTCStatus "ENM";
BA_ "VNSigAllNodes" SG_ 951 FICMDS3_DTCIndx 1;
BA_ "PacketOrder" SG_ 951 FICMDS3_DTCIndx 1;
BA_ "SignalLongName" SG_ 951 FICMDS3_DTCIndx "Fuel Injector Control Module Diagnostic Status 3 : Diagnostic Trouble Code Index";
BA_ "SignalType" SG_ 951 FICMDS3_DTCIndx "UNM";
BA_ "VNSigAllNodes" SG_ 951 FICMDS2_DTCStatus 1;
BA_ "PacketOrder" SG_ 951 FICMDS2_DTCStatus 2;
BA_ "SignalLongName" SG_ 951 FICMDS2_DTCStatus "Fuel Injector Control Module Diagnostic Status 2 : Diagnostic Trouble Code Status";
BA_ "SignalType" SG_ 951 FICMDS2_DTCStatus "ENM";
BA_ "VNSigAllNodes" SG_ 951 FICMDS2_DTCIndx 1;
BA_ "PacketOrder" SG_ 951 FICMDS2_DTCIndx 1;
BA_ "SignalLongName" SG_ 951 FICMDS2_DTCIndx "Fuel Injector Control Module Diagnostic Status 2 : Diagnostic Trouble Code Index";
BA_ "SignalType" SG_ 951 FICMDS2_DTCIndx "UNM";
BA_ "VNSigAllNodes" SG_ 951 FICMDS1_DTCStatus 1;
BA_ "PacketOrder" SG_ 951 FICMDS1_DTCStatus 2;
BA_ "SignalLongName" SG_ 951 FICMDS1_DTCStatus "Fuel Injector Control Module Diagnostic Status 1 : Diagnostic Trouble Code Status";
BA_ "SignalType" SG_ 951 FICMDS1_DTCStatus "ENM";
BA_ "VNSigAllNodes" SG_ 951 FICMDS1_DTCIndx 1;
BA_ "PacketOrder" SG_ 951 FICMDS1_DTCIndx 1;
BA_ "SignalLongName" SG_ 951 FICMDS1_DTCIndx "Fuel Injector Control Module Diagnostic Status 1 : Diagnostic Trouble Code Index";
BA_ "SignalType" SG_ 951 FICMDS1_DTCIndx "UNM";
BA_ "Prio" BO_ 949 0;
BA_ "GenMsgSendType" BO_ 949 0;
BA_ "GenMsgCycleTime" BO_ 949 100;
BA_ "MessageSubnet" BO_ 949 2;
BA_ "VNSigAllNodes" SG_ 949 AltFuelRFuelTrmLmtOff 1;
BA_ "SignalLongName" SG_ 949 AltFuelRFuelTrmLmtOff "Alternative Fuel Rich Fuel Trim Limit Offset";
BA_ "SignalType" SG_ 949 AltFuelRFuelTrmLmtOff "SNM";
BA_ "VNSigAllNodes" SG_ 949 AltFuelLnFuelTrmLmtOff 1;
BA_ "SignalLongName" SG_ 949 AltFuelLnFuelTrmLmtOff "Alternative Fuel Lean Fuel Trim Limit Offset";
BA_ "SignalType" SG_ 949 AltFuelLnFuelTrmLmtOff "SNM";
BA_ "VNSigAllNodes" SG_ 949 AltFuelInjMinPlsOffst 1;
BA_ "SignalLongName" SG_ 949 AltFuelInjMinPlsOffst "Alternative Fuel Injector Min Pulse Offset";
BA_ "SignalType" SG_ 949 AltFuelInjMinPlsOffst "SNM";
BA_ "VNSigAllNodes" SG_ 949 AltFuelInjOpnOffst 1;
BA_ "SignalLongName" SG_ 949 AltFuelInjOpnOffst "Alternative Fuel Injector Opening Offset";
BA_ "SignalType" SG_ 949 AltFuelInjOpnOffst "SNM";
BA_ "VNSigAllNodes" SG_ 949 AltFuelInjFlwOffst 1;
BA_ "SignalLongName" SG_ 949 AltFuelInjFlwOffst "Alternative Fuel Injector Flow Offset";
BA_ "SignalType" SG_ 949 AltFuelInjFlwOffst "SNM";
BA_ "VNSigAllNodes" SG_ 949 AltFuelEqvlntRatBsOffst 1;
BA_ "SignalLongName" SG_ 949 AltFuelEqvlntRatBsOffst "Alternative Fuel Equivalence Ratio Bias Offset";
BA_ "SignalType" SG_ 949 AltFuelEqvlntRatBsOffst "SNM";
BA_ "VNSigAllNodes" SG_ 949 AltFuelPst02BsOffst 1;
BA_ "SignalLongName" SG_ 949 AltFuelPst02BsOffst "Alternative Fuel Post O2 Bias Offset";
BA_ "SignalType" SG_ 949 AltFuelPst02BsOffst "SNM";
BA_ "Prio" BO_ 1223 0;
BA_ "GenMsgSendType" BO_ 1223 0;
BA_ "GenMsgCycleTime" BO_ 1223 500;
BA_ "MessageSubnet" BO_ 1223 2;
BA_ "VNSigAllNodes" SG_ 1223 EngSnPwrECoolLpTmpV 1;
BA_ "SignalLongName" SG_ 1223 EngSnPwrECoolLpTmpV "Engine Sensed Power Electronics Cooling Loop Temperature Validity";
BA_ "SignalType" SG_ 1223 EngSnPwrECoolLpTmpV "ENM";
BA_ "VNSigAllNodes" SG_ 1223 EngSnPwrECoolLpTmp 1;
BA_ "SignalLongName" SG_ 1223 EngSnPwrECoolLpTmp "Engine Sensed Power Electronics Cooling Loop Temperature";
BA_ "SignalType" SG_ 1223 EngSnPwrECoolLpTmp "UNM";
BA_ "VNSigAllNodes" SG_ 1223 PropSysOffTmeV 1;
BA_ "SignalLongName" SG_ 1223 PropSysOffTmeV "Propulsion System Off Time Validity";
BA_ "SignalType" SG_ 1223 PropSysOffTmeV "ENM";
BA_ "VNSigAllNodes" SG_ 1223 PropSysOffTmeM 1;
BA_ "SignalLongName" SG_ 1223 PropSysOffTmeM "Propulsion System Off Time Mask";
BA_ "SignalType" SG_ 1223 PropSysOffTmeM "ENM";
BA_ "VNSigAllNodes" SG_ 1223 PropSysOffTme 1;
BA_ "SignalLongName" SG_ 1223 PropSysOffTme "Propulsion System Off Time";
BA_ "SignalType" SG_ 1223 PropSysOffTme "UNM";
BA_ "Prio" BO_ 1227 0;
BA_ "GenMsgSendType" BO_ 1227 0;
BA_ "GenMsgCycleTime" BO_ 1227 500;
BA_ "MessageSubnet" BO_ 1227 2;
BA_ "VNSigAllNodes" SG_ 1227 BattThrmlCondOffTmeV 1;
BA_ "SignalLongName" SG_ 1227 BattThrmlCondOffTmeV "Battery Thermal Conditioning Off Time Validity";
BA_ "SignalType" SG_ 1227 BattThrmlCondOffTmeV "ENM";
BA_ "VNSigAllNodes" SG_ 1227 BattThrmlCondOffTmeM 1;
BA_ "SignalLongName" SG_ 1227 BattThrmlCondOffTmeM "Battery Thermal Conditioning Off Time Mask";
BA_ "SignalType" SG_ 1227 BattThrmlCondOffTmeM "ENM";
BA_ "VNSigAllNodes" SG_ 1227 BattThrmlCondOffTme 1;
BA_ "SignalLongName" SG_ 1227 BattThrmlCondOffTme "Battery Thermal Conditioning Off Time";
BA_ "SignalType" SG_ 1227 BattThrmlCondOffTme "UNM";
BA_ "VNSigAllNodes" SG_ 1227 OffBrdChrgOffTmeV 1;
BA_ "SignalLongName" SG_ 1227 OffBrdChrgOffTmeV "Off Board Charging Off Time Validity";
BA_ "SignalType" SG_ 1227 OffBrdChrgOffTmeV "ENM";
BA_ "VNSigAllNodes" SG_ 1227 OffBrdChrgOffTmeM 1;
BA_ "SignalLongName" SG_ 1227 OffBrdChrgOffTmeM "Off Board Charging Off Time Mask";
BA_ "SignalType" SG_ 1227 OffBrdChrgOffTmeM "ENM";
BA_ "VNSigAllNodes" SG_ 1227 OffBrdChrgOffTme 1;
BA_ "SignalLongName" SG_ 1227 OffBrdChrgOffTme "Off Board Charging Off Time";
BA_ "SignalType" SG_ 1227 OffBrdChrgOffTme "UNM";
BA_ "Prio" BO_ 543 0;
BA_ "GenMsgSendType" BO_ 543 0;
BA_ "GenMsgCycleTime" BO_ 543 100;
BA_ "MessageSubnet" BO_ 543 2;
BA_ "VNSigAllNodes" SG_ 543 PTOTpStpSpdCsStReq 1;
BA_ "SignalLongName" SG_ 543 PTOTpStpSpdCsStReq "Power Take Off Tap Step Speed Customization Setting Request";
BA_ "SignalType" SG_ 543 PTOTpStpSpdCsStReq "ENM";
BA_ "VNSigAllNodes" SG_ 543 PTOStdbySpdCsStReq 1;
BA_ "SignalLongName" SG_ 543 PTOStdbySpdCsStReq "Power Take Off Standby Speed Customization Setting Request";
BA_ "SignalType" SG_ 543 PTOStdbySpdCsStReq "ENM";
BA_ "VNSigAllNodes" SG_ 543 PTOEngRnTmrCsStRq 1;
BA_ "SignalLongName" SG_ 543 PTOEngRnTmrCsStRq "Power Take Off Engine Run Timer Customization Setting Request";
BA_ "SignalType" SG_ 543 PTOEngRnTmrCsStRq "ENM";
BA_ "VNSigAllNodes" SG_ 543 PTOSet2SpdCsStReq 1;
BA_ "SignalLongName" SG_ 543 PTOSet2SpdCsStReq "Power Take Off Set 2 Speed Customization Setting Request";
BA_ "SignalType" SG_ 543 PTOSet2SpdCsStReq "ENM";
BA_ "VNSigAllNodes" SG_ 543 PTOSet1SpdCsStReq 1;
BA_ "SignalLongName" SG_ 543 PTOSet1SpdCsStReq "Power Take Off Set 1 Speed Customization Setting Request";
BA_ "SignalType" SG_ 543 PTOSet1SpdCsStReq "ENM";
BA_ "Prio" BO_ 544 0;
BA_ "GenMsgSendType" BO_ 544 0;
BA_ "GenMsgCycleTime" BO_ 544 250;
BA_ "MessageSubnet" BO_ 544 2;
BA_ "VNSigAllNodes" SG_ 544 PTOAudExtAlertReq 1;
BA_ "SignalLongName" SG_ 544 PTOAudExtAlertReq "Power Take Off Audible External Alert Request";
BA_ "SignalType" SG_ 544 PTOAudExtAlertReq "BLN";
BA_ "VNSigAllNodes" SG_ 544 PTOTransInGearIO 1;
BA_ "SignalLongName" SG_ 544 PTOTransInGearIO "Power Take Off Transmission In Gear Indication On";
BA_ "SignalType" SG_ 544 PTOTransInGearIO "BLN";
BA_ "VNSigAllNodes" SG_ 544 PTOTpStpSpdCsStAvl 1;
BA_ "SignalLongName" SG_ 544 PTOTpStpSpdCsStAvl "Power Take Off Tap Step Speed Customization Setting Available";
BA_ "SignalType" SG_ 544 PTOTpStpSpdCsStAvl "BLN";
BA_ "VNSigAllNodes" SG_ 544 PTOTpStSpdCsCrStVal 1;
BA_ "SignalLongName" SG_ 544 PTOTpStSpdCsCrStVal "Power Take Off Tap Step Speed Customization Current Setting Value";
BA_ "SignalType" SG_ 544 PTOTpStSpdCsCrStVal "ENM";
BA_ "VNSigAllNodes" SG_ 544 PTOStdbySpdCsStAvl 1;
BA_ "SignalLongName" SG_ 544 PTOStdbySpdCsStAvl "Power Take Off Standby Speed Customization Setting Available";
BA_ "SignalType" SG_ 544 PTOStdbySpdCsStAvl "BLN";
BA_ "VNSigAllNodes" SG_ 544 PTOStdbSpdCsCrStVal 1;
BA_ "SignalLongName" SG_ 544 PTOStdbSpdCsCrStVal "Power Take Off Standby Speed Customization Current Setting Value";
BA_ "SignalType" SG_ 544 PTOStdbSpdCsCrStVal "ENM";
BA_ "VNSigAllNodes" SG_ 544 PTOSetPrkBrkIO 1;
BA_ "SignalLongName" SG_ 544 PTOSetPrkBrkIO "Power Take Off Set Park Brake Indication On";
BA_ "SignalType" SG_ 544 PTOSetPrkBrkIO "BLN";
BA_ "VNSigAllNodes" SG_ 544 PTOSet2SpdCsStAvl 1;
BA_ "SignalLongName" SG_ 544 PTOSet2SpdCsStAvl "Power Take Off Set 2 Speed Customization Setting Available";
BA_ "SignalType" SG_ 544 PTOSet2SpdCsStAvl "BLN";
BA_ "VNSigAllNodes" SG_ 544 PTOSet2SpdCsCrStVal 1;
BA_ "SignalLongName" SG_ 544 PTOSet2SpdCsCrStVal "Power Take Off Set 2 Speed Customization Current Setting Value";
BA_ "SignalType" SG_ 544 PTOSet2SpdCsCrStVal "ENM";
BA_ "VNSigAllNodes" SG_ 544 PTOSet1SpdCsStAvl 1;
BA_ "SignalLongName" SG_ 544 PTOSet1SpdCsStAvl "Power Take Off Set 1 Speed Customization Setting Available";
BA_ "SignalType" SG_ 544 PTOSet1SpdCsStAvl "BLN";
BA_ "VNSigAllNodes" SG_ 544 PTOSet1SpdCsCrStVal 1;
BA_ "SignalLongName" SG_ 544 PTOSet1SpdCsCrStVal "Power Take Off Set 1 Speed Customization Current Setting Value";
BA_ "SignalType" SG_ 544 PTOSet1SpdCsCrStVal "ENM";
BA_ "VNSigAllNodes" SG_ 544 PTORelCltPedIO 1;
BA_ "SignalLongName" SG_ 544 PTORelCltPedIO "Power Take Off Release Clutch Pedal Indication On";
BA_ "SignalType" SG_ 544 PTORelCltPedIO "BLN";
BA_ "VNSigAllNodes" SG_ 544 PTORelBrkPedIO 1;
BA_ "SignalLongName" SG_ 544 PTORelBrkPedIO "Power Take Off Release Brake Pedal Indication On";
BA_ "SignalType" SG_ 544 PTORelBrkPedIO "BLN";
BA_ "VNSigAllNodes" SG_ 544 PTORelAccPedIO 1;
BA_ "SignalLongName" SG_ 544 PTORelAccPedIO "Power Take Off Release Accelerator Pedal Indication On";
BA_ "SignalType" SG_ 544 PTORelAccPedIO "BLN";
BA_ "VNSigAllNodes" SG_ 544 PTORedEngSpdIO 1;
BA_ "SignalLongName" SG_ 544 PTORedEngSpdIO "Power Take Off Reduce Engine Speed Indication On";
BA_ "SignalType" SG_ 544 PTORedEngSpdIO "BLN";
BA_ "VNSigAllNodes" SG_ 544 PTOPrsRelCltPedIO 1;
BA_ "SignalLongName" SG_ 544 PTOPrsRelCltPedIO "Power Take Off Press and Release Clutch Pedal Indication On";
BA_ "SignalType" SG_ 544 PTOPrsRelCltPedIO "BLN";
BA_ "VNSigAllNodes" SG_ 544 PTOPrsRelBrkPedIO 1;
BA_ "SignalLongName" SG_ 544 PTOPrsRelBrkPedIO "Power Take Off Press and Release Brake Pedal Indication On";
BA_ "SignalType" SG_ 544 PTOPrsRelBrkPedIO "BLN";
BA_ "VNSigAllNodes" SG_ 544 PTOEngRnTmrCsStAvl 1;
BA_ "SignalLongName" SG_ 544 PTOEngRnTmrCsStAvl "Power Take Off Engine Run Timer Customization Setting Available";
BA_ "SignalType" SG_ 544 PTOEngRnTmrCsStAvl "BLN";
BA_ "VNSigAllNodes" SG_ 544 PTOEnRnTmCsCrStVal 1;
BA_ "SignalLongName" SG_ 544 PTOEnRnTmCsCrStVal "Power Take Off Engine Run Timer Customization Current Setting Value";
BA_ "SignalType" SG_ 544 PTOEnRnTmCsCrStVal "ENM";
BA_ "VNSigAllNodes" SG_ 544 PTOEngmntStatInd 1;
BA_ "SignalLongName" SG_ 544 PTOEngmntStatInd "Power Take Off Engagement Status Indication";
BA_ "SignalType" SG_ 544 PTOEngmntStatInd "ENM";
BA_ "VNSigAllNodes" SG_ 544 PTODisengCrsCntlIO 1;
BA_ "SignalLongName" SG_ 544 PTODisengCrsCntlIO "Power Take Off Disengage Cruise Control Indication On";
BA_ "SignalType" SG_ 544 PTODisengCrsCntlIO "BLN";
BA_ "Prio" BO_ 901 0;
BA_ "GenMsgSendType" BO_ 901 0;
BA_ "GenMsgCycleTime" BO_ 901 100;
BA_ "MessageSubnet" BO_ 901 2;
BA_ "VNSigAllNodes" SG_ 901 TrnsMtrBCoolFlwEst 1;
BA_ "SignalLongName" SG_ 901 TrnsMtrBCoolFlwEst "Transmission Motor B Cooling Flow Estimated";
BA_ "SignalType" SG_ 901 TrnsMtrBCoolFlwEst "UNM";
BA_ "VNSigAllNodes" SG_ 901 TrnsMtrACoolFlwEst 1;
BA_ "SignalLongName" SG_ 901 TrnsMtrACoolFlwEst "Transmission Motor A Cooling Flow Estimated";
BA_ "SignalType" SG_ 901 TrnsMtrACoolFlwEst "UNM";
BA_ "VNSigAllNodes" SG_ 901 TrnsLubeFlwEst 1;
BA_ "SignalLongName" SG_ 901 TrnsLubeFlwEst "Transmission Lube Flow Estimated";
BA_ "SignalType" SG_ 901 TrnsLubeFlwEst "UNM";
BA_ "Prio" BO_ 1032 0;
BA_ "GenMsgSendType" BO_ 1032 0;
BA_ "GenMsgCycleTime" BO_ 1032 100;
BA_ "MessageSubnet" BO_ 1032 2;
BA_ "VNSigAllNodes" SG_ 1032 RdTyp 1;
BA_ "SignalLongName" SG_ 1032 RdTyp "Road Type";
BA_ "SignalType" SG_ 1032 RdTyp "ENM";
BA_ "VNSigAllNodes" SG_ 1032 FwdCamSysOpStat 1;
BA_ "SignalLongName" SG_ 1032 FwdCamSysOpStat "Forward Camera System Operating Status";
BA_ "SignalType" SG_ 1032 FwdCamSysOpStat "ENM";
BA_ "VNSigAllNodes" SG_ 1032 EnvIllum 1;
BA_ "SignalLongName" SG_ 1032 EnvIllum "Environment Illumination";
BA_ "SignalType" SG_ 1032 EnvIllum "ENM";
BA_ "VNSigAllNodes" SG_ 1032 AutoHgBmSts 1;
BA_ "SignalLongName" SG_ 1032 AutoHgBmSts "Automatic High Beam Status";
BA_ "SignalType" SG_ 1032 AutoHgBmSts "ENM";
BA_ "Prio" BO_ 1031 0;
BA_ "GenMsgSendType" BO_ 1031 0;
BA_ "GenMsgCycleTime" BO_ 1031 100;
BA_ "MessageSubnet" BO_ 1031 2;
BA_ "VNSigAllNodes" SG_ 1031 FCO8D_ObjVertVar 1;
BA_ "PacketOrder" SG_ 1031 FCO8D_ObjVertVar 8;
BA_ "SignalLongName" SG_ 1031 FCO8D_ObjVertVar "Forward Camera Object 8 Detected : Object Vertical Variance";
BA_ "SignalType" SG_ 1031 FCO8D_ObjVertVar "SNM";
BA_ "VNSigAllNodes" SG_ 1031 FCO8D_ObjVertPos 1;
BA_ "PacketOrder" SG_ 1031 FCO8D_ObjVertPos 7;
BA_ "SignalLongName" SG_ 1031 FCO8D_ObjVertPos "Forward Camera Object 8 Detected : Object Vertical Position";
BA_ "SignalType" SG_ 1031 FCO8D_ObjVertPos "SNM";
BA_ "VNSigAllNodes" SG_ 1031 FCO8D_ObjTyp 1;
BA_ "PacketOrder" SG_ 1031 FCO8D_ObjTyp 3;
BA_ "SignalLongName" SG_ 1031 FCO8D_ObjTyp "Forward Camera Object 8 Detected : Object Type";
BA_ "SignalType" SG_ 1031 FCO8D_ObjTyp "ENM";
BA_ "VNSigAllNodes" SG_ 1031 FCO8D_ObjQlty 1;
BA_ "PacketOrder" SG_ 1031 FCO8D_ObjQlty 1;
BA_ "SignalLongName" SG_ 1031 FCO8D_ObjQlty "Forward Camera Object 8 Detected : Object Quality";
BA_ "SignalType" SG_ 1031 FCO8D_ObjQlty "ENM";
BA_ "VNSigAllNodes" SG_ 1031 FCO8D_ObjId 1;
BA_ "PacketOrder" SG_ 1031 FCO8D_ObjId 2;
BA_ "SignalLongName" SG_ 1031 FCO8D_ObjId "Forward Camera Object 8 Detected : Object ID";
BA_ "SignalType" SG_ 1031 FCO8D_ObjId "UNM";
BA_ "VNSigAllNodes" SG_ 1031 FCO8D_ObjHorzPos 1;
BA_ "PacketOrder" SG_ 1031 FCO8D_ObjHorzPos 4;
BA_ "SignalLongName" SG_ 1031 FCO8D_ObjHorzPos "Forward Camera Object 8 Detected : Object Horizontal Position";
BA_ "SignalType" SG_ 1031 FCO8D_ObjHorzPos "SNM";
BA_ "VNSigAllNodes" SG_ 1031 FCO8D_ObjHorzDim 1;
BA_ "PacketOrder" SG_ 1031 FCO8D_ObjHorzDim 6;
BA_ "SignalLongName" SG_ 1031 FCO8D_ObjHorzDim "Forward Camera Object 8 Detected : Object Horizontal Dimension";
BA_ "SignalType" SG_ 1031 FCO8D_ObjHorzDim "UNM";
BA_ "VNSigAllNodes" SG_ 1031 FCO8D_ObjDist 1;
BA_ "PacketOrder" SG_ 1031 FCO8D_ObjDist 9;
BA_ "SignalLongName" SG_ 1031 FCO8D_ObjDist "Forward Camera Object 8 Detected : Object Distance";
BA_ "SignalType" SG_ 1031 FCO8D_ObjDist "UNM";
BA_ "VNSigAllNodes" SG_ 1031 FCO8D_DetMthd 1;
BA_ "PacketOrder" SG_ 1031 FCO8D_DetMthd 5;
BA_ "SignalLongName" SG_ 1031 FCO8D_DetMthd "Forward Camera Object 8 Detected : Detection Method";
BA_ "SignalType" SG_ 1031 FCO8D_DetMthd "ENM";
BA_ "Prio" BO_ 1030 0;
BA_ "GenMsgSendType" BO_ 1030 0;
BA_ "GenMsgCycleTime" BO_ 1030 100;
BA_ "MessageSubnet" BO_ 1030 2;
BA_ "VNSigAllNodes" SG_ 1030 FCO7D_ObjVertVar 1;
BA_ "PacketOrder" SG_ 1030 FCO7D_ObjVertVar 8;
BA_ "SignalLongName" SG_ 1030 FCO7D_ObjVertVar "Forward Camera Object 7 Detected : Object Vertical Variance";
BA_ "SignalType" SG_ 1030 FCO7D_ObjVertVar "SNM";
BA_ "VNSigAllNodes" SG_ 1030 FCO7D_ObjVertPos 1;
BA_ "PacketOrder" SG_ 1030 FCO7D_ObjVertPos 7;
BA_ "SignalLongName" SG_ 1030 FCO7D_ObjVertPos "Forward Camera Object 7 Detected : Object Vertical Position";
BA_ "SignalType" SG_ 1030 FCO7D_ObjVertPos "SNM";
BA_ "VNSigAllNodes" SG_ 1030 FCO7D_ObjTyp 1;
BA_ "PacketOrder" SG_ 1030 FCO7D_ObjTyp 3;
BA_ "SignalLongName" SG_ 1030 FCO7D_ObjTyp "Forward Camera Object 7 Detected : Object Type";
BA_ "SignalType" SG_ 1030 FCO7D_ObjTyp "ENM";
BA_ "VNSigAllNodes" SG_ 1030 FCO7D_ObjQlty 1;
BA_ "PacketOrder" SG_ 1030 FCO7D_ObjQlty 1;
BA_ "SignalLongName" SG_ 1030 FCO7D_ObjQlty "Forward Camera Object 7 Detected : Object Quality";
BA_ "SignalType" SG_ 1030 FCO7D_ObjQlty "ENM";
BA_ "VNSigAllNodes" SG_ 1030 FCO7D_ObjId 1;
BA_ "PacketOrder" SG_ 1030 FCO7D_ObjId 2;
BA_ "SignalLongName" SG_ 1030 FCO7D_ObjId "Forward Camera Object 7 Detected : Object ID";
BA_ "SignalType" SG_ 1030 FCO7D_ObjId "UNM";
BA_ "VNSigAllNodes" SG_ 1030 FCO7D_ObjHorzPos 1;
BA_ "PacketOrder" SG_ 1030 FCO7D_ObjHorzPos 4;
BA_ "SignalLongName" SG_ 1030 FCO7D_ObjHorzPos "Forward Camera Object 7 Detected : Object Horizontal Position";
BA_ "SignalType" SG_ 1030 FCO7D_ObjHorzPos "SNM";
BA_ "VNSigAllNodes" SG_ 1030 FCO7D_ObjHorzDim 1;
BA_ "PacketOrder" SG_ 1030 FCO7D_ObjHorzDim 6;
BA_ "SignalLongName" SG_ 1030 FCO7D_ObjHorzDim "Forward Camera Object 7 Detected : Object Horizontal Dimension";
BA_ "SignalType" SG_ 1030 FCO7D_ObjHorzDim "UNM";
BA_ "VNSigAllNodes" SG_ 1030 FCO7D_ObjDist 1;
BA_ "PacketOrder" SG_ 1030 FCO7D_ObjDist 9;
BA_ "SignalLongName" SG_ 1030 FCO7D_ObjDist "Forward Camera Object 7 Detected : Object Distance";
BA_ "SignalType" SG_ 1030 FCO7D_ObjDist "UNM";
BA_ "VNSigAllNodes" SG_ 1030 FCO7D_DetMthd 1;
BA_ "PacketOrder" SG_ 1030 FCO7D_DetMthd 5;
BA_ "SignalLongName" SG_ 1030 FCO7D_DetMthd "Forward Camera Object 7 Detected : Detection Method";
BA_ "SignalType" SG_ 1030 FCO7D_DetMthd "ENM";
BA_ "Prio" BO_ 479 0;
BA_ "GenMsgSendType" BO_ 479 0;
BA_ "GenMsgCycleTime" BO_ 479 25;
BA_ "MessageSubnet" BO_ 479 2;
BA_ "VNSigAllNodes" SG_ 479 ASIRI_Indication16 1;
BA_ "PacketOrder" SG_ 479 ASIRI_Indication16 16;
BA_ "SignalLongName" SG_ 479 ASIRI_Indication16 "Auto Stop Inhibit Reason Indication : Indication 16";
BA_ "SignalType" SG_ 479 ASIRI_Indication16 "BLN";
BA_ "VNSigAllNodes" SG_ 479 ASIRI_Indication15 1;
BA_ "PacketOrder" SG_ 479 ASIRI_Indication15 15;
BA_ "SignalLongName" SG_ 479 ASIRI_Indication15 "Auto Stop Inhibit Reason Indication : Indication 15";
BA_ "SignalType" SG_ 479 ASIRI_Indication15 "BLN";
BA_ "VNSigAllNodes" SG_ 479 ASIRI_Indication14 1;
BA_ "PacketOrder" SG_ 479 ASIRI_Indication14 14;
BA_ "SignalLongName" SG_ 479 ASIRI_Indication14 "Auto Stop Inhibit Reason Indication : Indication 14";
BA_ "SignalType" SG_ 479 ASIRI_Indication14 "BLN";
BA_ "VNSigAllNodes" SG_ 479 ASIRI_Indication13 1;
BA_ "PacketOrder" SG_ 479 ASIRI_Indication13 13;
BA_ "SignalLongName" SG_ 479 ASIRI_Indication13 "Auto Stop Inhibit Reason Indication : Indication 13";
BA_ "SignalType" SG_ 479 ASIRI_Indication13 "BLN";
BA_ "VNSigAllNodes" SG_ 479 ASIRI_Indication12 1;
BA_ "PacketOrder" SG_ 479 ASIRI_Indication12 12;
BA_ "SignalLongName" SG_ 479 ASIRI_Indication12 "Auto Stop Inhibit Reason Indication : Indication 12";
BA_ "SignalType" SG_ 479 ASIRI_Indication12 "BLN";
BA_ "VNSigAllNodes" SG_ 479 ASIRI_Indication11 1;
BA_ "PacketOrder" SG_ 479 ASIRI_Indication11 11;
BA_ "SignalLongName" SG_ 479 ASIRI_Indication11 "Auto Stop Inhibit Reason Indication : Indication 11";
BA_ "SignalType" SG_ 479 ASIRI_Indication11 "BLN";
BA_ "VNSigAllNodes" SG_ 479 ASIRI_Indication10 1;
BA_ "PacketOrder" SG_ 479 ASIRI_Indication10 10;
BA_ "SignalLongName" SG_ 479 ASIRI_Indication10 "Auto Stop Inhibit Reason Indication : Indication 10";
BA_ "SignalType" SG_ 479 ASIRI_Indication10 "BLN";
BA_ "VNSigAllNodes" SG_ 479 ASIRI_Indication09 1;
BA_ "PacketOrder" SG_ 479 ASIRI_Indication09 9;
BA_ "SignalLongName" SG_ 479 ASIRI_Indication09 "Auto Stop Inhibit Reason Indication : Indication 9";
BA_ "SignalType" SG_ 479 ASIRI_Indication09 "BLN";
BA_ "VNSigAllNodes" SG_ 479 ASIRI_Indication08 1;
BA_ "PacketOrder" SG_ 479 ASIRI_Indication08 8;
BA_ "SignalLongName" SG_ 479 ASIRI_Indication08 "Auto Stop Inhibit Reason Indication : Indication 8";
BA_ "SignalType" SG_ 479 ASIRI_Indication08 "BLN";
BA_ "VNSigAllNodes" SG_ 479 ASIRI_Indication07 1;
BA_ "PacketOrder" SG_ 479 ASIRI_Indication07 7;
BA_ "SignalLongName" SG_ 479 ASIRI_Indication07 "Auto Stop Inhibit Reason Indication : Indication 7";
BA_ "SignalType" SG_ 479 ASIRI_Indication07 "BLN";
BA_ "VNSigAllNodes" SG_ 479 ASIRI_Indication06 1;
BA_ "SignalLongName" SG_ 479 ASIRI_Indication06 "Auto Stop Inhibit Reason Indication : Indication 6";
BA_ "SignalType" SG_ 479 ASIRI_Indication06 "BLN";
BA_ "VNSigAllNodes" SG_ 479 ASIRI_Indication05 1;
BA_ "PacketOrder" SG_ 479 ASIRI_Indication05 5;
BA_ "SignalLongName" SG_ 479 ASIRI_Indication05 "Auto Stop Inhibit Reason Indication : Indication 5";
BA_ "SignalType" SG_ 479 ASIRI_Indication05 "BLN";
BA_ "VNSigAllNodes" SG_ 479 ASIRI_Indication04 1;
BA_ "PacketOrder" SG_ 479 ASIRI_Indication04 4;
BA_ "SignalLongName" SG_ 479 ASIRI_Indication04 "Auto Stop Inhibit Reason Indication : Indication 4";
BA_ "SignalType" SG_ 479 ASIRI_Indication04 "BLN";
BA_ "VNSigAllNodes" SG_ 479 ASIRI_Indication03 1;
BA_ "PacketOrder" SG_ 479 ASIRI_Indication03 3;
BA_ "SignalLongName" SG_ 479 ASIRI_Indication03 "Auto Stop Inhibit Reason Indication : Indication 3";
BA_ "SignalType" SG_ 479 ASIRI_Indication03 "BLN";
BA_ "VNSigAllNodes" SG_ 479 ASIRI_Indication02 1;
BA_ "PacketOrder" SG_ 479 ASIRI_Indication02 2;
BA_ "SignalLongName" SG_ 479 ASIRI_Indication02 "Auto Stop Inhibit Reason Indication : Indication 2";
BA_ "SignalType" SG_ 479 ASIRI_Indication02 "BLN";
BA_ "VNSigAllNodes" SG_ 479 ASIRI_Indication01 1;
BA_ "PacketOrder" SG_ 479 ASIRI_Indication01 1;
BA_ "SignalLongName" SG_ 479 ASIRI_Indication01 "Auto Stop Inhibit Reason Indication : Indication 1";
BA_ "SignalType" SG_ 479 ASIRI_Indication01 "BLN";
BA_ "VNSigAllNodes" SG_ 479 PTWrmgWtToShftIO 1;
BA_ "SignalLongName" SG_ 479 PTWrmgWtToShftIO "Powertrain Warming Wait To Shift Indication On";
BA_ "SignalType" SG_ 479 PTWrmgWtToShftIO "BLN";
BA_ "VNSigAllNodes" SG_ 479 PrplsnSysAtv 1;
BA_ "SignalLongName" SG_ 479 PrplsnSysAtv "Propulsion System Active";
BA_ "SignalType" SG_ 479 PrplsnSysAtv "BLN";
BA_ "VNSigAllNodes" SG_ 479 PTShftLvrLckRqd 1;
BA_ "SignalLongName" SG_ 479 PTShftLvrLckRqd "Powertrain Shift Lever Lock Requested";
BA_ "SignalType" SG_ 479 PTShftLvrLckRqd "BLN";
BA_ "Prio" BO_ 211 0;
BA_ "GenMsgSendType" BO_ 211 0;
BA_ "GenMsgCycleTime" BO_ 211 12;
BA_ "MessageSubnet" BO_ 211 2;
BA_ "VNSigAllNodes" SG_ 211 ActAxleTrqV 1;
BA_ "SignalLongName" SG_ 211 ActAxleTrqV "Actual Axle Torque Validity";
BA_ "SignalType" SG_ 211 ActAxleTrqV "ENM";
BA_ "VNSigAllNodes" SG_ 211 ActAxleTrq 1;
BA_ "SignalLongName" SG_ 211 ActAxleTrq "Actual Axle Torque";
BA_ "SignalType" SG_ 211 ActAxleTrq "UNM";
BA_ "Prio" BO_ 1020 0;
BA_ "GenMsgSendType" BO_ 1020 0;
BA_ "GenMsgCycleTime" BO_ 1020 250;
BA_ "MessageSubnet" BO_ 1020 2;
BA_ "VNSigAllNodes" SG_ 1020 OtsAirTmpEmsnsRelV 1;
BA_ "SignalLongName" SG_ 1020 OtsAirTmpEmsnsRelV "Outside Air Temperature Emissions Related Validity";
BA_ "SignalType" SG_ 1020 OtsAirTmpEmsnsRelV "ENM";
BA_ "VNSigAllNodes" SG_ 1020 OtsAirTmpEmsnsRel 1;
BA_ "SignalLongName" SG_ 1020 OtsAirTmpEmsnsRel "Outside Air Temperature Emissions Related";
BA_ "SignalType" SG_ 1020 OtsAirTmpEmsnsRel "UNM";
BA_ "VNSigAllNodes" SG_ 1020 OATEmsnsRelCrValV 1;
BA_ "SignalLongName" SG_ 1020 OATEmsnsRelCrValV "Outside Air Temperature Emissions Related Corrected Value Validity";
BA_ "SignalType" SG_ 1020 OATEmsnsRelCrValV "ENM";
BA_ "VNSigAllNodes" SG_ 1020 OATEmsnsRelCrValM 1;
BA_ "SignalLongName" SG_ 1020 OATEmsnsRelCrValM "Outside Air Temperature Emissions Related Corrected Value Mask";
BA_ "SignalType" SG_ 1020 OATEmsnsRelCrValM "ENM";
BA_ "VNSigAllNodes" SG_ 1020 OATEmsnsRelCrVal 1;
BA_ "SignalLongName" SG_ 1020 OATEmsnsRelCrVal "Outside Air Temperature Emissions Related Corrected Value";
BA_ "SignalType" SG_ 1020 OATEmsnsRelCrVal "UNM";
BA_ "VNSigAllNodes" SG_ 1020 CatlystOutGasTempEstV 1;
BA_ "SignalLongName" SG_ 1020 CatlystOutGasTempEstV "Catalyst Outlet Gas Temperature Estimate Validity";
BA_ "SignalType" SG_ 1020 CatlystOutGasTempEstV "ENM";
BA_ "VNSigAllNodes" SG_ 1020 CatlystOutGasTempEst 1;
BA_ "SignalLongName" SG_ 1020 CatlystOutGasTempEst "Catalyst Outlet Gas Temperature Estimate";
BA_ "SignalType" SG_ 1020 CatlystOutGasTempEst "UNM";
BA_ "VNSigAllNodes" SG_ 1020 OtsAirTmpCrValMsk 1;
BA_ "SignalLongName" SG_ 1020 OtsAirTmpCrValMsk "Outside Air Temperature Corrected Value Mask";
BA_ "SignalType" SG_ 1020 OtsAirTmpCrValMsk "ENM";
BA_ "VNSigAllNodes" SG_ 1020 OtsAirTmpV 1;
BA_ "SignalLongName" SG_ 1020 OtsAirTmpV "Outside Air Temperature Validity";
BA_ "SignalType" SG_ 1020 OtsAirTmpV "ENM";
BA_ "VNSigAllNodes" SG_ 1020 OtsAirTmpCrValV 1;
BA_ "SignalLongName" SG_ 1020 OtsAirTmpCrValV "Outside Air Temperature Corrected Value Validity";
BA_ "SignalType" SG_ 1020 OtsAirTmpCrValV "ENM";
BA_ "VNSigAllNodes" SG_ 1020 OtsAirTmpCrVal 1;
BA_ "SignalLongName" SG_ 1020 OtsAirTmpCrVal "Outside Air Temperature Corrected Value";
BA_ "SignalType" SG_ 1020 OtsAirTmpCrVal "UNM";
BA_ "VNSigAllNodes" SG_ 1020 OtsAirTmp 1;
BA_ "SignalLongName" SG_ 1020 OtsAirTmp "Outside Air Temperature";
BA_ "SignalType" SG_ 1020 OtsAirTmp "UNM";
BA_ "VNSigAllNodes" SG_ 1020 EngInltSpcfcHmdtyV 1;
BA_ "SignalLongName" SG_ 1020 EngInltSpcfcHmdtyV "Engine Inlet Specific Humidity Validity";
BA_ "SignalType" SG_ 1020 EngInltSpcfcHmdtyV "ENM";
BA_ "VNSigAllNodes" SG_ 1020 EngInltSpcfcHmdtyM 1;
BA_ "SignalLongName" SG_ 1020 EngInltSpcfcHmdtyM "Engine Inlet Specific Humidity Mask";
BA_ "SignalType" SG_ 1020 EngInltSpcfcHmdtyM "ENM";
BA_ "VNSigAllNodes" SG_ 1020 EngInltSpcfcHmdty 1;
BA_ "SignalLongName" SG_ 1020 EngInltSpcfcHmdty "Engine Inlet Specific Humidity";
BA_ "SignalType" SG_ 1020 EngInltSpcfcHmdty "UNM";
